VERSION ""

NS_ :

BS_:

BU_: IVI_IF IC HUD MFW ECALL ALC VAP EPA GW_IF

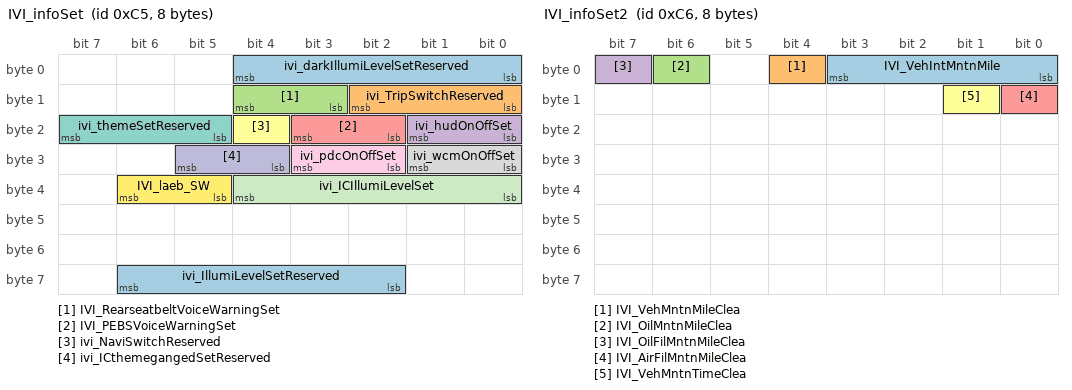
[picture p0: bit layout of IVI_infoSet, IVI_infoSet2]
BO_ 197 IVI_infoSet: 8 IVI_IF
 SG_ ivi_darkIllumiLevelSetReserved : 0|5@1+ (1,0) [0|31] "" Vector__XXX
 SG_ ivi_TripSwitchReserved : 8|3@1+ (1,0) [0|7] "" Vector__XXX
 SG_ IVI_RearseatbeltVoiceWarningSet : 11|2@1+ (1,0) [0|3] ""  GW_IF
 SG_ ivi_hudOnOffSet : 16|2@1+ (1,0) [0|3] ""  HUD,GW_IF
 SG_ IVI_PEBSVoiceWarningSet : 18|2@1+ (1,0) [0|3] ""  GW_IF
 SG_ ivi_NaviSwitchReserved : 20|1@1+ (1,0) [0|1] ""  GW_IF
 SG_ ivi_themeSetReserved : 21|3@1+ (1,0) [0|7] ""  GW_IF
 SG_ ivi_wcmOnOffSet : 24|2@1+ (1,0) [0|3] ""  GW_IF
 SG_ ivi_pdcOnOffSet : 26|2@1+ (1,0) [0|3] ""  GW_IF
 SG_ ivi_ICthemegangedSetReserved : 28|2@1+ (1,0) [0|3] "" Vector__XXX
 SG_ ivi_ICIllumiLevelSet : 32|5@1+ (1,0) [0|31] ""  IC
 SG_ IVI_laeb_SW : 37|2@1+ (1,0) [0|3] ""  GW_IF
 SG_ ivi_IllumiLevelSetReserved : 58|5@1+ (1,0) [0|31] "" Vector__XXX

BO_ 198 IVI_infoSet2: 8 IVI_IF
 SG_ IVI_VehIntMntnMile : 0|4@1+ (500,3000) [3000|10000] "Km" Vector__XXX
 SG_ IVI_VehMntnMileClea : 4|1@1+ (1,0) [0|1] "" Vector__XXX
 SG_ IVI_OilMntnMileClea : 6|1@1+ (1,0) [0|1] "" Vector__XXX
 SG_ IVI_OilFilMntnMileClea : 7|1@1+ (1,0) [0|1] "" Vector__XXX
 SG_ IVI_AirFilMntnMileClea : 8|1@1+ (1,0) [0|1] "" Vector__XXX
 SG_ IVI_VehMntnTimeClea : 9|1@1+ (1,0) [0|1] "" Vector__XXX

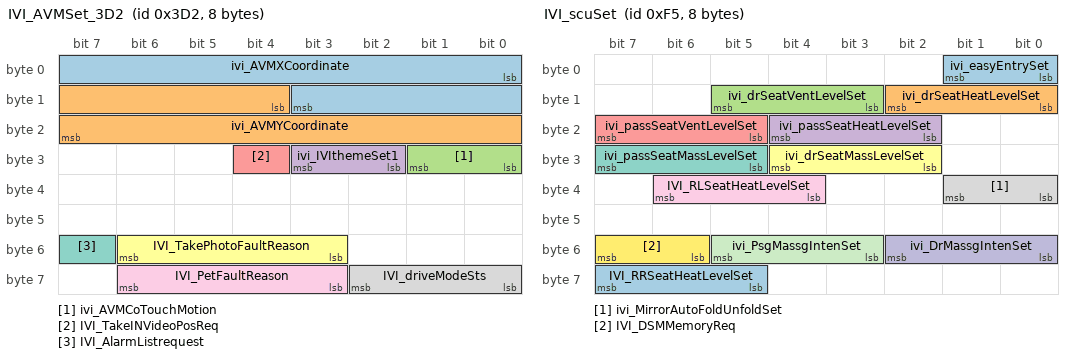
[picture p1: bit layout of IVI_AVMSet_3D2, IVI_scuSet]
BO_ 978 IVI_AVMSet_3D2: 8 IVI_IF
 SG_ ivi_AVMXCoordinate : 0|12@1+ (1,0) [0|1920] ""  GW_IF
 SG_ ivi_AVMYCoordinate : 12|12@1+ (1,0) [0|1080] ""  GW_IF
 SG_ ivi_AVMCoTouchMotion : 24|2@1+ (1,0) [0|3] ""  GW_IF
 SG_ ivi_IVIthemeSet1 : 26|2@1+ (1,0) [0|3] ""  GW_IF
 SG_ IVI_TakeINVideoPosReq : 28|1@1+ (1,0) [0|1] "" Vector__XXX
 SG_ IVI_TakePhotoFaultReason : 51|4@1+ (1,0) [0|15] "" Vector__XXX
 SG_ IVI_AlarmListrequest : 55|1@1+ (1,0) [0|1] "" Vector__XXX
 SG_ IVI_driveModeSts : 56|3@1+ (1,0) [0|7] "" Vector__XXX
 SG_ IVI_PetFaultReason : 59|4@1+ (1,0) [0|15] ""  GW_IF

BO_ 245 IVI_scuSet: 8 IVI_IF
 SG_ ivi_easyEntrySet : 0|2@1+ (1,0) [0|3] ""  GW_IF
 SG_ ivi_drSeatHeatLevelSet : 8|3@1+ (1,0) [0|7] ""  GW_IF
 SG_ ivi_drSeatVentLevelSet : 11|3@1+ (1,0) [0|7] ""  GW_IF
 SG_ ivi_passSeatHeatLevelSet : 18|3@1+ (1,0) [0|7] ""  GW_IF
 SG_ ivi_passSeatVentLevelSet : 21|3@1+ (1,0) [0|7] ""  GW_IF
 SG_ ivi_drSeatMassLevelSet : 26|3@1+ (1,0) [0|7] ""  GW_IF
 SG_ ivi_passSeatMassLevelSet : 29|3@1+ (1,0) [0|7] ""  GW_IF
 SG_ ivi_MirrorAutoFoldUnfoldSet : 32|2@1+ (1,0) [0|3] ""  GW_IF
 SG_ IVI_RLSeatHeatLevelSet : 36|3@1+ (1,0) [0|7] ""  GW_IF
 SG_ ivi_DrMassgIntenSet : 48|3@1+ (1,0) [0|7] ""  GW_IF
 SG_ ivi_PsgMassgIntenSet : 51|3@1+ (1,0) [0|7] ""  GW_IF
 SG_ IVI_DSMMemoryReq : 54|2@1+ (1,0) [0|3] ""  GW_IF
 SG_ IVI_RRSeatHeatLevelSet : 61|3@1+ (1,0) [0|7] ""  GW_IF

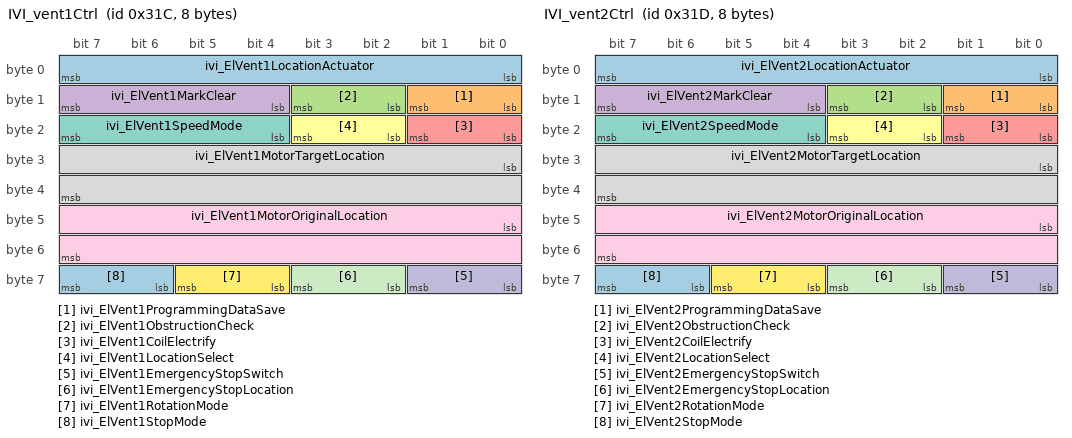
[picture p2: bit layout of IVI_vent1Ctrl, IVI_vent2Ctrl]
BO_ 796 IVI_vent1Ctrl: 8 IVI_IF
 SG_ ivi_ElVent1LocationActuator : 0|8@1+ (1,0) [0|255] ""  GW_IF
 SG_ ivi_ElVent1ProgrammingDataSave : 8|2@1+ (1,0) [0|3] ""  GW_IF
 SG_ ivi_ElVent1ObstructionCheck : 10|2@1+ (1,0) [0|3] ""  GW_IF
 SG_ ivi_ElVent1MarkClear : 12|4@1+ (1,0) [0|15] ""  GW_IF
 SG_ ivi_ElVent1CoilElectrify : 16|2@1+ (1,0) [0|3] ""  GW_IF
 SG_ ivi_ElVent1LocationSelect : 18|2@1+ (1,0) [0|3] ""  GW_IF
 SG_ ivi_ElVent1SpeedMode : 20|4@1+ (1,0) [0|15] ""  GW_IF
 SG_ ivi_ElVent1MotorTargetLocation : 24|16@1+ (1,0) [0|65535] ""  GW_IF
 SG_ ivi_ElVent1MotorOriginalLocation : 40|16@1+ (1,0) [0|65535] ""  GW_IF
 SG_ ivi_ElVent1EmergencyStopSwitch : 56|2@1+ (1,0) [0|3] ""  GW_IF
 SG_ ivi_ElVent1EmergencyStopLocation : 58|2@1+ (1,0) [0|3] ""  GW_IF
 SG_ ivi_ElVent1RotationMode : 60|2@1+ (1,0) [0|3] ""  GW_IF
 SG_ ivi_ElVent1StopMode : 62|2@1+ (1,0) [0|3] ""  GW_IF

BO_ 797 IVI_vent2Ctrl: 8 IVI_IF
 SG_ ivi_ElVent2LocationActuator : 0|8@1+ (1,0) [0|255] ""  GW_IF
 SG_ ivi_ElVent2ProgrammingDataSave : 8|2@1+ (1,0) [0|3] ""  GW_IF
 SG_ ivi_ElVent2ObstructionCheck : 10|2@1+ (1,0) [0|3] ""  GW_IF
 SG_ ivi_ElVent2MarkClear : 12|4@1+ (1,0) [0|15] ""  GW_IF
 SG_ ivi_ElVent2CoilElectrify : 16|2@1+ (1,0) [0|3] ""  GW_IF
 SG_ ivi_ElVent2LocationSelect : 18|2@1+ (1,0) [0|3] ""  GW_IF
 SG_ ivi_ElVent2SpeedMode : 20|4@1+ (1,0) [0|15] ""  GW_IF
 SG_ ivi_ElVent2MotorTargetLocation : 24|16@1+ (1,0) [0|65535] ""  GW_IF
 SG_ ivi_ElVent2MotorOriginalLocation : 40|16@1+ (1,0) [0|65535] ""  GW_IF
 SG_ ivi_ElVent2EmergencyStopSwitch : 56|2@1+ (1,0) [0|3] ""  GW_IF
 SG_ ivi_ElVent2EmergencyStopLocation : 58|2@1+ (1,0) [0|3] ""  GW_IF
 SG_ ivi_ElVent2RotationMode : 60|2@1+ (1,0) [0|3] ""  GW_IF
 SG_ ivi_ElVent2StopMode : 62|2@1+ (1,0) [0|3] ""  GW_IF

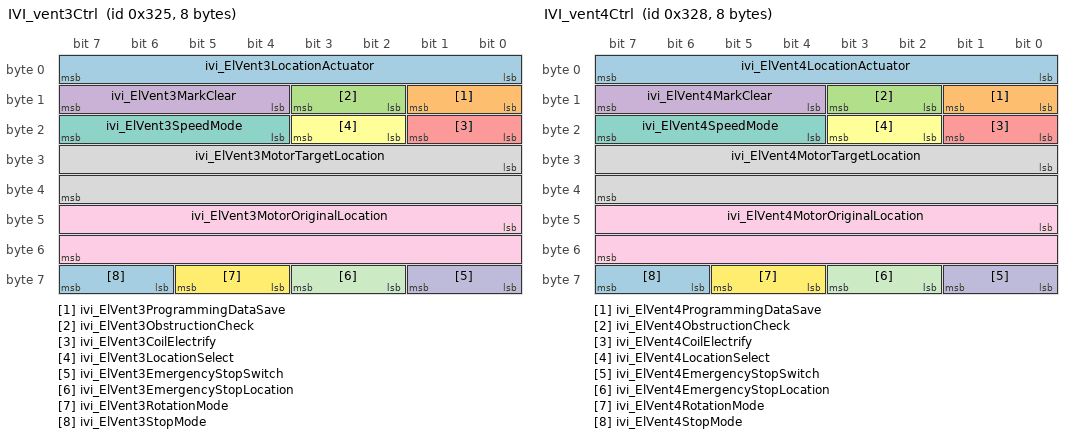
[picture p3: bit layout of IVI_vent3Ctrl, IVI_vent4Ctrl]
BO_ 805 IVI_vent3Ctrl: 8 IVI_IF
 SG_ ivi_ElVent3LocationActuator : 0|8@1+ (1,0) [0|255] ""  GW_IF
 SG_ ivi_ElVent3ProgrammingDataSave : 8|2@1+ (1,0) [0|3] ""  GW_IF
 SG_ ivi_ElVent3ObstructionCheck : 10|2@1+ (1,0) [0|3] ""  GW_IF
 SG_ ivi_ElVent3MarkClear : 12|4@1+ (1,0) [0|15] ""  GW_IF
 SG_ ivi_ElVent3CoilElectrify : 16|2@1+ (1,0) [0|3] ""  GW_IF
 SG_ ivi_ElVent3LocationSelect : 18|2@1+ (1,0) [0|3] ""  GW_IF
 SG_ ivi_ElVent3SpeedMode : 20|4@1+ (1,0) [0|15] ""  GW_IF
 SG_ ivi_ElVent3MotorTargetLocation : 24|16@1+ (1,0) [0|65535] ""  GW_IF
 SG_ ivi_ElVent3MotorOriginalLocation : 40|16@1+ (1,0) [0|65535] ""  GW_IF
 SG_ ivi_ElVent3EmergencyStopSwitch : 56|2@1+ (1,0) [0|3] ""  GW_IF
 SG_ ivi_ElVent3EmergencyStopLocation : 58|2@1+ (1,0) [0|3] ""  GW_IF
 SG_ ivi_ElVent3RotationMode : 60|2@1+ (1,0) [0|3] ""  GW_IF
 SG_ ivi_ElVent3StopMode : 62|2@1+ (1,0) [0|3] ""  GW_IF

BO_ 808 IVI_vent4Ctrl: 8 IVI_IF
 SG_ ivi_ElVent4LocationActuator : 0|8@1+ (1,0) [0|255] ""  GW_IF
 SG_ ivi_ElVent4ProgrammingDataSave : 8|2@1+ (1,0) [0|3] ""  GW_IF
 SG_ ivi_ElVent4ObstructionCheck : 10|2@1+ (1,0) [0|3] ""  GW_IF
 SG_ ivi_ElVent4MarkClear : 12|4@1+ (1,0) [0|15] ""  GW_IF
 SG_ ivi_ElVent4CoilElectrify : 16|2@1+ (1,0) [0|3] ""  GW_IF
 SG_ ivi_ElVent4LocationSelect : 18|2@1+ (1,0) [0|3] ""  GW_IF
 SG_ ivi_ElVent4SpeedMode : 20|4@1+ (1,0) [0|15] ""  GW_IF
 SG_ ivi_ElVent4MotorTargetLocation : 24|16@1+ (1,0) [0|65535] ""  GW_IF
 SG_ ivi_ElVent4MotorOriginalLocation : 40|16@1+ (1,0) [0|65535] ""  GW_IF
 SG_ ivi_ElVent4EmergencyStopSwitch : 56|2@1+ (1,0) [0|3] ""  GW_IF
 SG_ ivi_ElVent4EmergencyStopLocation : 58|2@1+ (1,0) [0|3] ""  GW_IF
 SG_ ivi_ElVent4RotationMode : 60|2@1+ (1,0) [0|3] ""  GW_IF
 SG_ ivi_ElVent4StopMode : 62|2@1+ (1,0) [0|3] ""  GW_IF

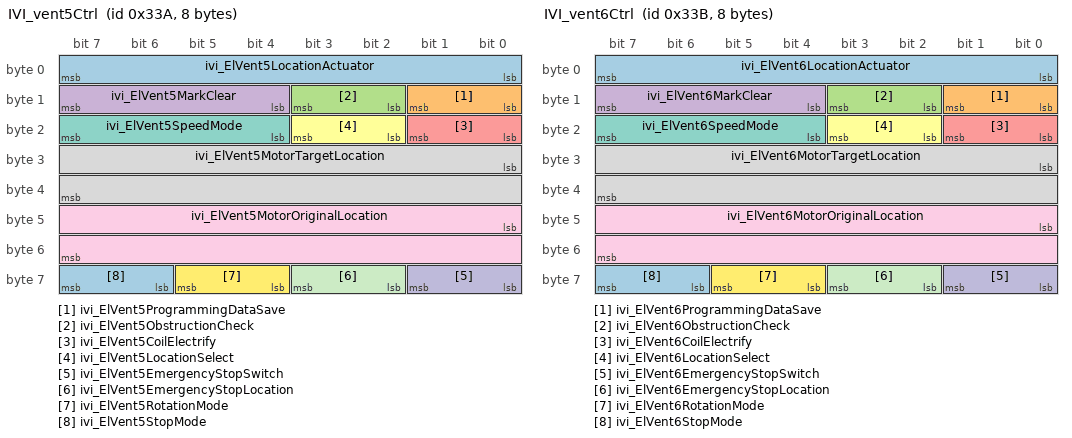
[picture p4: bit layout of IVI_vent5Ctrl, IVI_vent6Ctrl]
BO_ 826 IVI_vent5Ctrl: 8 IVI_IF
 SG_ ivi_ElVent5LocationActuator : 0|8@1+ (1,0) [0|255] ""  GW_IF
 SG_ ivi_ElVent5ProgrammingDataSave : 8|2@1+ (1,0) [0|3] ""  GW_IF
 SG_ ivi_ElVent5ObstructionCheck : 10|2@1+ (1,0) [0|3] ""  GW_IF
 SG_ ivi_ElVent5MarkClear : 12|4@1+ (1,0) [0|15] ""  GW_IF
 SG_ ivi_ElVent5CoilElectrify : 16|2@1+ (1,0) [0|3] ""  GW_IF
 SG_ ivi_ElVent5LocationSelect : 18|2@1+ (1,0) [0|3] ""  GW_IF
 SG_ ivi_ElVent5SpeedMode : 20|4@1+ (1,0) [0|15] ""  GW_IF
 SG_ ivi_ElVent5MotorTargetLocation : 24|16@1+ (1,0) [0|65535] ""  GW_IF
 SG_ ivi_ElVent5MotorOriginalLocation : 40|16@1+ (1,0) [0|65535] ""  GW_IF
 SG_ ivi_ElVent5EmergencyStopSwitch : 56|2@1+ (1,0) [0|3] ""  GW_IF
 SG_ ivi_ElVent5EmergencyStopLocation : 58|2@1+ (1,0) [0|3] ""  GW_IF
 SG_ ivi_ElVent5RotationMode : 60|2@1+ (1,0) [0|3] ""  GW_IF
 SG_ ivi_ElVent5StopMode : 62|2@1+ (1,0) [0|3] ""  GW_IF

BO_ 827 IVI_vent6Ctrl: 8 IVI_IF
 SG_ ivi_ElVent6LocationActuator : 0|8@1+ (1,0) [0|255] ""  GW_IF
 SG_ ivi_ElVent6ProgrammingDataSave : 8|2@1+ (1,0) [0|3] ""  GW_IF
 SG_ ivi_ElVent6ObstructionCheck : 10|2@1+ (1,0) [0|3] ""  GW_IF
 SG_ ivi_ElVent6MarkClear : 12|4@1+ (1,0) [0|15] ""  GW_IF
 SG_ ivi_ElVent6CoilElectrify : 16|2@1+ (1,0) [0|3] ""  GW_IF
 SG_ ivi_ElVent6LocationSelect : 18|2@1+ (1,0) [0|3] ""  GW_IF
 SG_ ivi_ElVent6SpeedMode : 20|4@1+ (1,0) [0|15] ""  GW_IF
 SG_ ivi_ElVent6MotorTargetLocation : 24|16@1+ (1,0) [0|65535] ""  GW_IF
 SG_ ivi_ElVent6MotorOriginalLocation : 40|16@1+ (1,0) [0|65535] ""  GW_IF
 SG_ ivi_ElVent6EmergencyStopSwitch : 56|2@1+ (1,0) [0|3] ""  GW_IF
 SG_ ivi_ElVent6EmergencyStopLocation : 58|2@1+ (1,0) [0|3] ""  GW_IF
 SG_ ivi_ElVent6RotationMode : 60|2@1+ (1,0) [0|3] ""  GW_IF
 SG_ ivi_ElVent6StopMode : 62|2@1+ (1,0) [0|3] ""  GW_IF

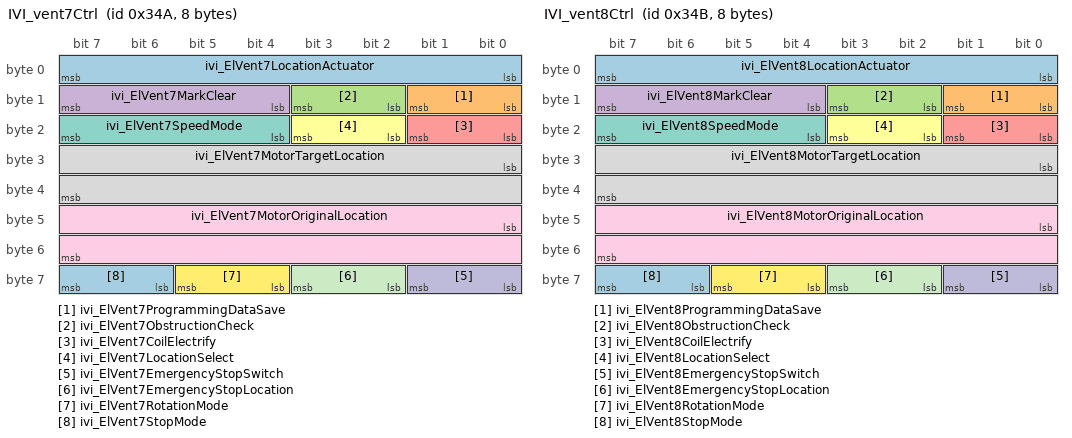
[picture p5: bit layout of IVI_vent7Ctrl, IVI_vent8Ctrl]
BO_ 842 IVI_vent7Ctrl: 8 IVI_IF
 SG_ ivi_ElVent7LocationActuator : 0|8@1+ (1,0) [0|255] ""  GW_IF
 SG_ ivi_ElVent7ProgrammingDataSave : 8|2@1+ (1,0) [0|3] ""  GW_IF
 SG_ ivi_ElVent7ObstructionCheck : 10|2@1+ (1,0) [0|3] ""  GW_IF
 SG_ ivi_ElVent7MarkClear : 12|4@1+ (1,0) [0|15] ""  GW_IF
 SG_ ivi_ElVent7CoilElectrify : 16|2@1+ (1,0) [0|3] ""  GW_IF
 SG_ ivi_ElVent7LocationSelect : 18|2@1+ (1,0) [0|3] ""  GW_IF
 SG_ ivi_ElVent7SpeedMode : 20|4@1+ (1,0) [0|15] ""  GW_IF
 SG_ ivi_ElVent7MotorTargetLocation : 24|16@1+ (1,0) [0|65535] ""  GW_IF
 SG_ ivi_ElVent7MotorOriginalLocation : 40|16@1+ (1,0) [0|65535] ""  GW_IF
 SG_ ivi_ElVent7EmergencyStopSwitch : 56|2@1+ (1,0) [0|3] ""  GW_IF
 SG_ ivi_ElVent7EmergencyStopLocation : 58|2@1+ (1,0) [0|3] ""  GW_IF
 SG_ ivi_ElVent7RotationMode : 60|2@1+ (1,0) [0|3] ""  GW_IF
 SG_ ivi_ElVent7StopMode : 62|2@1+ (1,0) [0|3] ""  GW_IF

BO_ 843 IVI_vent8Ctrl: 8 IVI_IF
 SG_ ivi_ElVent8LocationActuator : 0|8@1+ (1,0) [0|255] ""  GW_IF
 SG_ ivi_ElVent8ProgrammingDataSave : 8|2@1+ (1,0) [0|3] ""  GW_IF
 SG_ ivi_ElVent8ObstructionCheck : 10|2@1+ (1,0) [0|3] ""  GW_IF
 SG_ ivi_ElVent8MarkClear : 12|4@1+ (1,0) [0|15] ""  GW_IF
 SG_ ivi_ElVent8CoilElectrify : 16|2@1+ (1,0) [0|3] ""  GW_IF
 SG_ ivi_ElVent8LocationSelect : 18|2@1+ (1,0) [0|3] ""  GW_IF
 SG_ ivi_ElVent8SpeedMode : 20|4@1+ (1,0) [0|15] ""  GW_IF
 SG_ ivi_ElVent8MotorTargetLocation : 24|16@1+ (1,0) [0|65535] ""  GW_IF
 SG_ ivi_ElVent8MotorOriginalLocation : 40|16@1+ (1,0) [0|65535] ""  GW_IF
 SG_ ivi_ElVent8EmergencyStopSwitch : 56|2@1+ (1,0) [0|3] ""  GW_IF
 SG_ ivi_ElVent8EmergencyStopLocation : 58|2@1+ (1,0) [0|3] ""  GW_IF
 SG_ ivi_ElVent8RotationMode : 60|2@1+ (1,0) [0|3] ""  GW_IF
 SG_ ivi_ElVent8StopMode : 62|2@1+ (1,0) [0|3] ""  GW_IF

BO_ 966 GW_vent1Sts: 8 GW_IF
 SG_ gw_ElVent1ErrorStatus : 0|1@1+ (1,0) [0|1] ""  IVI_IF
 SG_ gw_ElVent1OverHeatStatus : 2|2@1+ (1,0) [0|3] ""  IVI_IF
 SG_ gw_ElVent1ElectricalFailureSts : 4|2@1+ (1,0) [0|3] ""  IVI_IF
 SG_ gw_ElVent1VoltageStatus : 6|2@1+ (1,0) [0|3] ""  IVI_IF
 SG_ gw_ElVent1EmergencyRunningSts : 8|2@1+ (1,0) [0|3] ""  IVI_IF
 SG_ gw_ElVent1ObstructionDetect : 10|2@1+ (1,0) [0|3] ""  IVI_IF
 SG_ gw_ElVent1ObstructionStatus : 12|2@1+ (1,0) [0|3] ""  IVI_IF
 SG_ gw_ElVent1ResetStatus : 14|2@1+ (1,0) [0|3] ""  IVI_IF
 SG_ gw_ElVent1CoilStatus : 16|2@1+ (1,0) [0|3] ""  IVI_IF
 SG_ gw_ElVent1LocationStatus : 18|2@1+ (1,0) [0|3] ""  IVI_IF
 SG_ gw_ElVent1SpeedStatus : 20|4@1+ (1,0) [0|15] ""  IVI_IF
 SG_ gw_ElVent1MotorCurrentLocation : 24|16@1+ (1,0) [0|65535] ""  IVI_IF
 SG_ gw_ElVent1MotorDrivingDirection : 40|2@1+ (1,0) [0|3] ""  IVI_IF
 SG_ gw_ElVent1TorqueKeepingSts : 42|2@1+ (1,0) [0|3] ""  IVI_IF
 SG_ gw_ElVent1SpecialFunction : 44|2@1+ (1,0) [0|3] ""  IVI_IF
 SG_ gw_ElVent1LocationActuator : 48|8@1+ (1,0) [0|255] ""  IVI_IF
 SG_ gw_ElVent1EmgyStopSwitchSts : 56|2@1+ (1,0) [0|3] ""  IVI_IF
 SG_ gw_ElVent1EmgyStopSLocation : 58|2@1+ (1,0) [0|3] ""  IVI_IF
 SG_ gw_ElVent1RotationMode : 60|2@1+ (1,0) [0|3] ""  IVI_IF
 SG_ gw_ElVent1StopStatus : 62|2@1+ (1,0) [0|3] ""  IVI_IF

BO_ 967 GW_vent2Sts: 8 GW_IF
 SG_ gw_ElVent2ErrorStatus : 0|1@1+ (1,0) [0|1] ""  IVI_IF
 SG_ gw_ElVent2OverHeatStatus : 2|2@1+ (1,0) [0|3] ""  IVI_IF
 SG_ gw_ElVent2ElectricalFailureSts : 4|2@1+ (1,0) [0|3] ""  IVI_IF
 SG_ gw_ElVent2VoltageStatus : 6|2@1+ (1,0) [0|3] ""  IVI_IF
 SG_ gw_ElVent2EmergencyRunningSts : 8|2@1+ (1,0) [0|3] ""  IVI_IF
 SG_ gw_ElVent2ObstructionDetect : 10|2@1+ (1,0) [0|3] ""  IVI_IF
 SG_ gw_ElVent2ObstructionStatus : 12|2@1+ (1,0) [0|3] ""  IVI_IF
 SG_ gw_ElVent2ResetStatus : 14|2@1+ (1,0) [0|3] ""  IVI_IF
 SG_ gw_ElVent2CoilStatus : 16|2@1+ (1,0) [0|3] ""  IVI_IF
 SG_ gw_ElVent2LocationStatus : 18|2@1+ (1,0) [0|3] ""  IVI_IF
 SG_ gw_ElVent2SpeedStatus : 20|4@1+ (1,0) [0|15] ""  IVI_IF
 SG_ gw_ElVent2MotorCurrentLocation : 24|16@1+ (1,0) [0|65535] ""  IVI_IF
 SG_ gw_ElVent2MotorDrivingDirection : 40|2@1+ (1,0) [0|3] ""  IVI_IF
 SG_ gw_ElVent2TorqueKeepingSts : 42|2@1+ (1,0) [0|3] ""  IVI_IF
 SG_ gw_ElVent2SpecialFunction : 44|2@1+ (1,0) [0|3] ""  IVI_IF
 SG_ gw_ElVent2LocationActuator : 48|8@1+ (1,0) [0|255] ""  IVI_IF
 SG_ gw_ElVent2EmgyStopSwitchSts : 56|2@1+ (1,0) [0|3] ""  IVI_IF
 SG_ gw_ElVent2EmgyStopSLocation : 58|2@1+ (1,0) [0|3] ""  IVI_IF
 SG_ gw_ElVent2RotationMode : 60|2@1+ (1,0) [0|3] ""  IVI_IF
 SG_ gw_ElVent2StopStatus : 62|2@1+ (1,0) [0|3] ""  IVI_IF

BO_ 968 GW_vent3Sts: 8 GW_IF
 SG_ gw_ElVent3ErrorStatus : 0|1@1+ (1,0) [0|1] ""  IVI_IF
 SG_ gw_ElVent3OverHeatStatus : 2|2@1+ (1,0) [0|3] ""  IVI_IF
 SG_ gw_ElVent3ElectricalFailureSts : 4|2@1+ (1,0) [0|3] ""  IVI_IF
 SG_ gw_ElVent3VoltageStatus : 6|2@1+ (1,0) [0|3] ""  IVI_IF
 SG_ gw_ElVent3EmergencyRunningSts : 8|2@1+ (1,0) [0|3] ""  IVI_IF
 SG_ gw_ElVent3ObstructionDetect : 10|2@1+ (1,0) [0|3] ""  IVI_IF
 SG_ gw_ElVent3ObstructionStatus : 12|2@1+ (1,0) [0|3] ""  IVI_IF
 SG_ gw_ElVent3ResetStatus : 14|2@1+ (1,0) [0|3] ""  IVI_IF
 SG_ gw_ElVent3CoilStatus : 16|2@1+ (1,0) [0|3] ""  IVI_IF
 SG_ gw_ElVent3LocationStatus : 18|2@1+ (1,0) [0|3] ""  IVI_IF
 SG_ gw_ElVent3SpeedStatus : 20|4@1+ (1,0) [0|15] ""  IVI_IF
 SG_ gw_ElVent3MotorCurrentLocation : 24|16@1+ (1,0) [0|65535] ""  IVI_IF
 SG_ gw_ElVent3MotorDrivingDirection : 40|2@1+ (1,0) [0|3] ""  IVI_IF
 SG_ gw_ElVent3TorqueKeepingSts : 42|2@1+ (1,0) [0|3] ""  IVI_IF
 SG_ gw_ElVent3SpecialFunction : 44|2@1+ (1,0) [0|3] ""  IVI_IF
 SG_ gw_ElVent3LocationActuator : 48|8@1+ (1,0) [0|255] ""  IVI_IF
 SG_ gw_ElVent3EmgyStopSwitchSts : 56|2@1+ (1,0) [0|3] ""  IVI_IF
 SG_ gw_ElVent3EmgyStopSLocation : 58|2@1+ (1,0) [0|3] ""  IVI_IF
 SG_ gw_ElVent3RotationMode : 60|2@1+ (1,0) [0|3] ""  IVI_IF
 SG_ gw_ElVent3StopStatus : 62|2@1+ (1,0) [0|3] ""  IVI_IF

BO_ 969 GW_vent4Sts: 8 GW_IF
 SG_ gw_ElVent4ErrorStatus : 0|1@1+ (1,0) [0|1] ""  IVI_IF
 SG_ gw_ElVent4OverHeatStatus : 2|2@1+ (1,0) [0|3] ""  IVI_IF
 SG_ gw_ElVent4ElectricalFailureSts : 4|2@1+ (1,0) [0|3] ""  IVI_IF
 SG_ gw_ElVent4VoltageStatus : 6|2@1+ (1,0) [0|3] ""  IVI_IF
 SG_ gw_ElVent4EmergencyRunningSts : 8|2@1+ (1,0) [0|3] ""  IVI_IF
 SG_ gw_ElVent4ObstructionDetect : 10|2@1+ (1,0) [0|3] ""  IVI_IF
 SG_ gw_ElVent4ObstructionStatus : 12|2@1+ (1,0) [0|3] ""  IVI_IF
 SG_ gw_ElVent4ResetStatus : 14|2@1+ (1,0) [0|3] ""  IVI_IF
 SG_ gw_ElVent4CoilStatus : 16|2@1+ (1,0) [0|3] ""  IVI_IF
 SG_ gw_ElVent4LocationStatus : 18|2@1+ (1,0) [0|3] ""  IVI_IF
 SG_ gw_ElVent4SpeedStatus : 20|4@1+ (1,0) [0|15] ""  IVI_IF
 SG_ gw_ElVent4MotorCurrentLocation : 24|16@1+ (1,0) [0|65535] ""  IVI_IF
 SG_ gw_ElVent4MotorDrivingDirection : 40|2@1+ (1,0) [0|3] ""  IVI_IF
 SG_ gw_ElVent4TorqueKeepingSts : 42|2@1+ (1,0) [0|3] ""  IVI_IF
 SG_ gw_ElVent4SpecialFunction : 44|2@1+ (1,0) [0|3] ""  IVI_IF
 SG_ gw_ElVent4LocationActuator : 48|8@1+ (1,0) [0|255] ""  IVI_IF
 SG_ gw_ElVent4EmgyStopSwitchSts : 56|2@1+ (1,0) [0|3] ""  IVI_IF
 SG_ gw_ElVent4EmgyStopSLocation : 58|2@1+ (1,0) [0|3] ""  IVI_IF
 SG_ gw_ElVent4RotationMode : 60|2@1+ (1,0) [0|3] ""  IVI_IF
 SG_ gw_ElVent4StopStatus : 62|2@1+ (1,0) [0|3] ""  IVI_IF

BO_ 970 GW_vent5Sts: 8 GW_IF
 SG_ gw_ElVent5ErrorStatus : 0|1@1+ (1,0) [0|1] ""  IVI_IF
 SG_ gw_ElVent5OverHeatStatus : 2|2@1+ (1,0) [0|3] ""  IVI_IF
 SG_ gw_ElVent5ElectricalFailureSts : 4|2@1+ (1,0) [0|3] ""  IVI_IF
 SG_ gw_ElVent5VoltageStatus : 6|2@1+ (1,0) [0|3] ""  IVI_IF
 SG_ gw_ElVent5EmergencyRunningSts : 8|2@1+ (1,0) [0|3] ""  IVI_IF
 SG_ gw_ElVent5ObstructionDetect : 10|2@1+ (1,0) [0|3] ""  IVI_IF
 SG_ gw_ElVent5ObstructionStatus : 12|2@1+ (1,0) [0|3] ""  IVI_IF
 SG_ gw_ElVent5ResetStatus : 14|2@1+ (1,0) [0|3] ""  IVI_IF
 SG_ gw_ElVent5CoilStatus : 16|2@1+ (1,0) [0|3] ""  IVI_IF
 SG_ gw_ElVent5LocationStatus : 18|2@1+ (1,0) [0|3] ""  IVI_IF
 SG_ gw_ElVent5SpeedStatus : 20|4@1+ (1,0) [0|15] ""  IVI_IF
 SG_ gw_ElVent5MotorCurrentLocation : 24|16@1+ (1,0) [0|65535] ""  IVI_IF
 SG_ gw_ElVent5MotorDrivingDirection : 40|2@1+ (1,0) [0|3] ""  IVI_IF
 SG_ gw_ElVent5TorqueKeepingSts : 42|2@1+ (1,0) [0|3] ""  IVI_IF
 SG_ gw_ElVent5SpecialFunction : 44|2@1+ (1,0) [0|3] ""  IVI_IF
 SG_ gw_ElVent5LocationActuator : 48|8@1+ (1,0) [0|255] ""  IVI_IF
 SG_ gw_ElVent5EmgyStopSwitchSts : 56|2@1+ (1,0) [0|3] ""  IVI_IF
 SG_ gw_ElVent5EmgyStopSLocation : 58|2@1+ (1,0) [0|3] ""  IVI_IF
 SG_ gw_ElVent5RotationMode : 60|2@1+ (1,0) [0|3] ""  IVI_IF
 SG_ gw_ElVent5StopStatus : 62|2@1+ (1,0) [0|3] ""  IVI_IF

BO_ 971 GW_vent6Sts: 8 GW_IF
 SG_ gw_ElVent6ErrorStatus : 0|1@1+ (1,0) [0|1] ""  IVI_IF
 SG_ gw_ElVent6OverHeatStatus : 2|2@1+ (1,0) [0|3] ""  IVI_IF
 SG_ gw_ElVent6ElectricalFailureSts : 4|2@1+ (1,0) [0|3] ""  IVI_IF
 SG_ gw_ElVent6VoltageStatus : 6|2@1+ (1,0) [0|3] ""  IVI_IF
 SG_ gw_ElVent6EmergencyRunningSts : 8|2@1+ (1,0) [0|3] ""  IVI_IF
 SG_ gw_ElVent6ObstructionDetect : 10|2@1+ (1,0) [0|3] ""  IVI_IF
 SG_ gw_ElVent6ObstructionStatus : 12|2@1+ (1,0) [0|3] ""  IVI_IF
 SG_ gw_ElVent6ResetStatus : 14|2@1+ (1,0) [0|3] ""  IVI_IF
 SG_ gw_ElVent6CoilStatus : 16|2@1+ (1,0) [0|3] ""  IVI_IF
 SG_ gw_ElVent6LocationStatus : 18|2@1+ (1,0) [0|3] ""  IVI_IF
 SG_ gw_ElVent6SpeedStatus : 20|4@1+ (1,0) [0|15] ""  IVI_IF
 SG_ gw_ElVent6MotorCurrentLocation : 24|16@1+ (1,0) [0|65535] ""  IVI_IF
 SG_ gw_ElVent6MotorDrivingDirection : 40|2@1+ (1,0) [0|3] ""  IVI_IF
 SG_ gw_ElVent6TorqueKeepingSts : 42|2@1+ (1,0) [0|3] ""  IVI_IF
 SG_ gw_ElVent6SpecialFunction : 44|2@1+ (1,0) [0|3] ""  IVI_IF
 SG_ gw_ElVent6LocationActuator : 48|8@1+ (1,0) [0|255] ""  IVI_IF
 SG_ gw_ElVent6EmgyStopSwitchSts : 56|2@1+ (1,0) [0|3] ""  IVI_IF
 SG_ gw_ElVent6EmgyStopSLocation : 58|2@1+ (1,0) [0|3] ""  IVI_IF
 SG_ gw_ElVent6RotationMode : 60|2@1+ (1,0) [0|3] ""  IVI_IF
 SG_ gw_ElVent6StopStatus : 62|2@1+ (1,0) [0|3] ""  IVI_IF

BO_ 972 GW_vent7Sts: 8 GW_IF
 SG_ gw_ElVent7ErrorStatus : 0|1@1+ (1,0) [0|1] ""  IVI_IF
 SG_ gw_ElVent7OverHeatStatus : 2|2@1+ (1,0) [0|3] ""  IVI_IF
 SG_ gw_ElVent7ElectricalFailureSts : 4|2@1+ (1,0) [0|3] ""  IVI_IF
 SG_ gw_ElVent7VoltageStatus : 6|2@1+ (1,0) [0|3] ""  IVI_IF
 SG_ gw_ElVent7EmergencyRunningSts : 8|2@1+ (1,0) [0|3] ""  IVI_IF
 SG_ gw_ElVent7ObstructionDetect : 10|2@1+ (1,0) [0|3] ""  IVI_IF
 SG_ gw_ElVent7ObstructionStatus : 12|2@1+ (1,0) [0|3] ""  IVI_IF
 SG_ gw_ElVent7ResetStatus : 14|2@1+ (1,0) [0|3] ""  IVI_IF
 SG_ gw_ElVent7CoilStatus : 16|2@1+ (1,0) [0|3] ""  IVI_IF
 SG_ gw_ElVent7LocationStatus : 18|2@1+ (1,0) [0|3] ""  IVI_IF
 SG_ gw_ElVent7SpeedStatus : 20|4@1+ (1,0) [0|15] ""  IVI_IF
 SG_ gw_ElVent7MotorCurrentLocation : 24|16@1+ (1,0) [0|65535] ""  IVI_IF
 SG_ gw_ElVent7MotorDrivingDirection : 40|2@1+ (1,0) [0|3] ""  IVI_IF
 SG_ gw_ElVent7TorqueKeepingSts : 42|2@1+ (1,0) [0|3] ""  IVI_IF
 SG_ gw_ElVent7SpecialFunction : 44|2@1+ (1,0) [0|3] ""  IVI_IF
 SG_ gw_ElVent7LocationActuator : 48|8@1+ (1,0) [0|255] ""  IVI_IF
 SG_ gw_ElVent7EmgyStopSwitchSts : 56|2@1+ (1,0) [0|3] ""  IVI_IF
 SG_ gw_ElVent7EmgyStopSLocation : 58|2@1+ (1,0) [0|3] ""  IVI_IF
 SG_ gw_ElVent7RotationMode : 60|2@1+ (1,0) [0|3] ""  IVI_IF
 SG_ gw_ElVent7StopStatus : 62|2@1+ (1,0) [0|3] ""  IVI_IF

BO_ 973 GW_vent8Sts: 8 GW_IF
 SG_ gw_ElVent8ErrorStatus : 0|1@1+ (1,0) [0|1] ""  IVI_IF
 SG_ gw_ElVent8OverHeatStatus : 2|2@1+ (1,0) [0|3] ""  IVI_IF
 SG_ gw_ElVent8ElectricalFailureSts : 4|2@1+ (1,0) [0|3] ""  IVI_IF
 SG_ gw_ElVent8VoltageStatus : 6|2@1+ (1,0) [0|3] ""  IVI_IF
 SG_ gw_ElVent8EmergencyRunningSts : 8|2@1+ (1,0) [0|3] ""  IVI_IF
 SG_ gw_ElVent8ObstructionDetect : 10|2@1+ (1,0) [0|3] ""  IVI_IF
 SG_ gw_ElVent8ObstructionStatus : 12|2@1+ (1,0) [0|3] ""  IVI_IF
 SG_ gw_ElVent8ResetStatus : 14|2@1+ (1,0) [0|3] ""  IVI_IF
 SG_ gw_ElVent8CoilStatus : 16|2@1+ (1,0) [0|3] ""  IVI_IF
 SG_ gw_ElVent8LocationStatus : 18|2@1+ (1,0) [0|3] ""  IVI_IF
 SG_ gw_ElVent8SpeedStatus : 20|4@1+ (1,0) [0|15] ""  IVI_IF
 SG_ gw_ElVent8MotorCurrentLocation : 24|16@1+ (1,0) [0|65535] ""  IVI_IF
 SG_ gw_ElVent8MotorDrivingDirection : 40|2@1+ (1,0) [0|3] ""  IVI_IF
 SG_ gw_ElVent8TorqueKeepingSts : 42|2@1+ (1,0) [0|3] ""  IVI_IF
 SG_ gw_ElVent8SpecialFunction : 44|2@1+ (1,0) [0|3] ""  IVI_IF
 SG_ gw_ElVent8LocationActuator : 48|8@1+ (1,0) [0|255] ""  IVI_IF
 SG_ gw_ElVent8EmgyStopSwitchSts : 56|2@1+ (1,0) [0|3] ""  IVI_IF
 SG_ gw_ElVent8EmgyStopSLocation : 58|2@1+ (1,0) [0|3] ""  IVI_IF
 SG_ gw_ElVent8RotationMode : 60|2@1+ (1,0) [0|3] ""  IVI_IF
 SG_ gw_ElVent8StopStatus : 62|2@1+ (1,0) [0|3] ""  IVI_IF

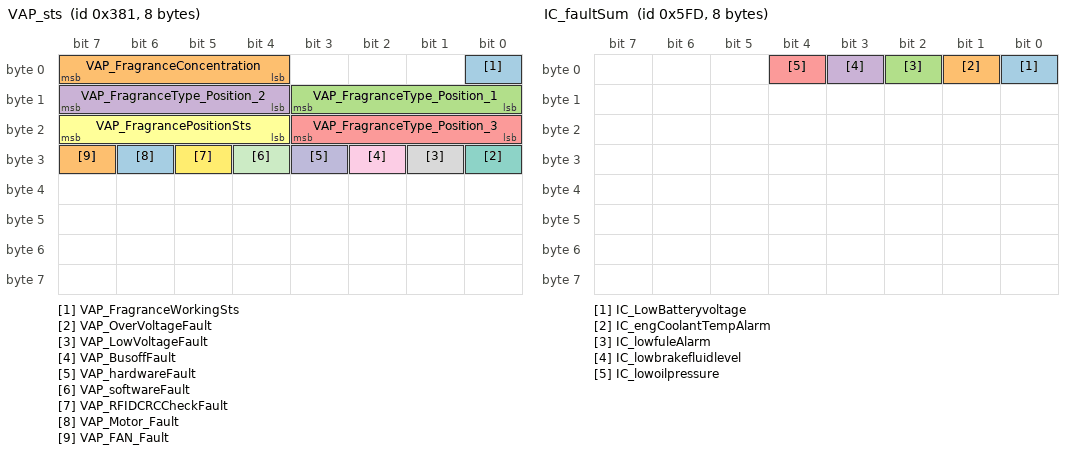
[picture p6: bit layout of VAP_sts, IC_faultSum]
BO_ 897 VAP_sts: 8 VAP
 SG_ VAP_FragranceWorkingSts : 0|1@1+ (1,0) [0|1] ""  IVI_IF
 SG_ VAP_FragranceConcentration : 4|4@1+ (1,0) [0|10] ""  IVI_IF
 SG_ VAP_FragranceType_Position_1 : 8|4@1+ (1,0) [0|15] ""  IVI_IF
 SG_ VAP_FragranceType_Position_2 : 12|4@1+ (1,0) [0|15] ""  IVI_IF
 SG_ VAP_FragranceType_Position_3 : 16|4@1+ (1,0) [0|15] ""  IVI_IF
 SG_ VAP_FragrancePositionSts : 20|4@1+ (1,0) [0|15] ""  IVI_IF
 SG_ VAP_OverVoltageFault : 24|1@1+ (1,0) [0|1] ""  IVI_IF
 SG_ VAP_LowVoltageFault : 25|1@1+ (1,0) [0|1] ""  IVI_IF
 SG_ VAP_BusoffFault : 26|1@1+ (1,0) [0|1] ""  IVI_IF
 SG_ VAP_hardwareFault : 27|1@1+ (1,0) [0|1] ""  IVI_IF
 SG_ VAP_softwareFault : 28|1@1+ (1,0) [0|1] ""  IVI_IF
 SG_ VAP_RFIDCRCCheckFault : 29|1@1+ (1,0) [0|1] ""  IVI_IF
 SG_ VAP_Motor_Fault : 30|1@1+ (1,0) [0|1] ""  IVI_IF
 SG_ VAP_FAN_Fault : 31|1@1+ (1,0) [0|1] ""  IVI_IF

BO_ 82 IC_engineOFF: 8 IVI_IF
 SG_ ic_engOffTime : 0|10@1+ (1,0) [0|1000] "min"  GW_IF
 SG_ ic_engOffTimeValid : 10|1@1+ (1,0) [0|1] ""  GW_IF
 SG_ IC_songFaultNum : 16|6@1+ (1,0) [0|63] "" Vector__XXX
 SG_ IC_songWarningSts : 22|2@1+ (1,0) [0|3] "" Vector__XXX

BO_ 1533 IC_faultSum: 8 IVI_IF
 SG_ IC_LowBatteryvoltage : 0|1@1+ (1,0) [0|1] "" Vector__XXX
 SG_ IC_engCoolantTempAlarm : 1|1@1+ (1,0) [0|1] "" Vector__XXX
 SG_ IC_lowfuleAlarm : 2|1@1+ (1,0) [0|1] "" Vector__XXX
 SG_ IC_lowbrakefluidlevel : 3|1@1+ (1,0) [0|1] "" Vector__XXX
 SG_ IC_lowoilpressure : 4|1@1+ (1,0) [0|1] "" Vector__XXX

BO_ 1010 IC_infoSet: 8 IVI_IF
 SG_ ic_hudScreenTransition : 0|2@1+ (1,0) [0|3] ""  HUD
 SG_ ic_hudHeightSet : 2|5@1+ (1,-14) [-14|14] ""  HUD
 SG_ ic_hudillumiLvSet : 8|4@1+ (1,-5) [-5|5] ""  HUD

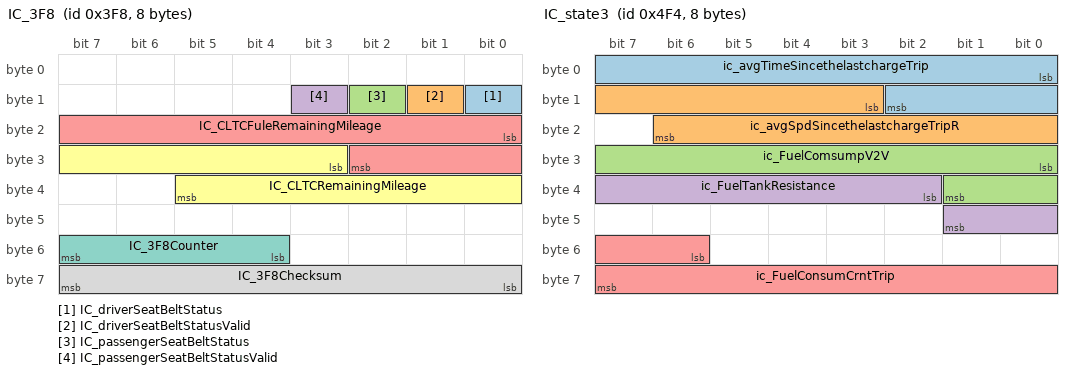
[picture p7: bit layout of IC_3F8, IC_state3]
BO_ 1016 IC_3F8: 8 IVI_IF
 SG_ IC_driverSeatBeltStatus : 8|1@1+ (1,0) [0|1] ""  GW_IF
 SG_ IC_driverSeatBeltStatusValid : 9|1@1+ (1,0) [0|1] ""  GW_IF
 SG_ IC_passengerSeatBeltStatus : 10|1@1+ (1,0) [0|1] ""  GW_IF
 SG_ IC_passengerSeatBeltStatusValid : 11|1@1+ (1,0) [0|1] ""  GW_IF
 SG_ IC_CLTCFuleRemainingMileage : 16|11@1+ (1,0) [0|2047] "km"  GW_IF
 SG_ IC_CLTCRemainingMileage : 27|11@1+ (1,0) [0|2047] "km"  GW_IF
 SG_ IC_3F8Counter : 52|4@1+ (1,0) [0|15] ""  GW_IF
 SG_ IC_3F8Checksum : 56|8@1+ (1,0) [0|255] ""  GW_IF

BO_ 1020 IC_3FC: 8 IVI_IF
 SG_ IC_NEDCRemainingMileage : 0|11@1+ (1,0) [0|2047] "km"  GW_IF
 SG_ IC_NEDCFuleRemainingMileage : 11|11@1+ (1,0) [0|2047] "km"  GW_IF

BO_ 1268 IC_state3: 8 IVI_IF
 SG_ ic_avgTimeSincethelastchargeTrip : 0|11@1+ (1,0) [0|1440] "min"  GW_IF
 SG_ ic_avgSpdSincethelastchargeTripR : 11|12@1+ (0.1,0) [0|280] "KPH"  GW_IF
 SG_ ic_FuelComsumpV2V : 24|10@1+ (0.1,0) [0|102.3] "L"  GW_IF
 SG_ ic_FuelTankResistance : 34|8@1+ (1,0) [0|255] "Ω"  GW_IF
 SG_ ic_FuelConsumCrntTrip : 54|10@1+ (0.1,0) [0|99.9] "L" Vector__XXX

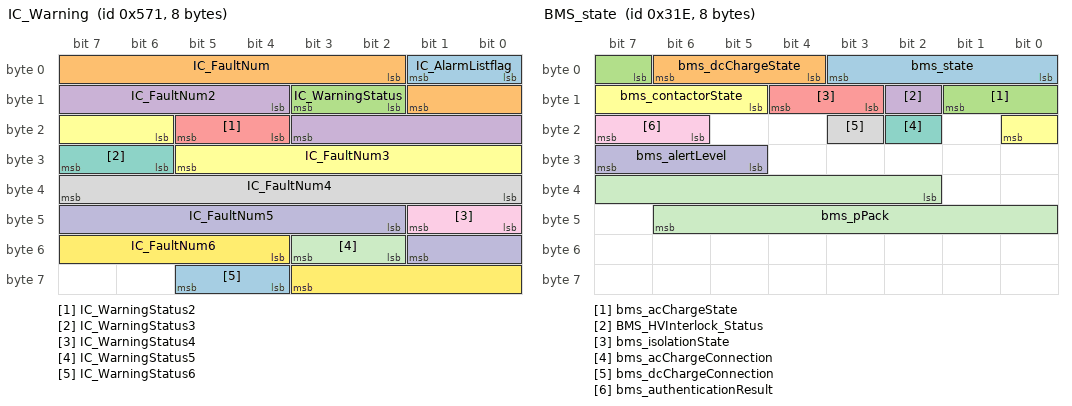
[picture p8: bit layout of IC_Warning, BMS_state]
BO_ 1393 IC_Warning: 8 IVI_IF
 SG_ IC_AlarmListflag : 0|2@1+ (1,0) [0|3] "" Vector__XXX
 SG_ IC_FaultNum : 2|8@1+ (1,0) [0|255] "" Vector__XXX
 SG_ IC_WarningStatus : 10|2@1+ (1,0) [0|3] "" Vector__XXX
 SG_ IC_FaultNum2 : 12|8@1+ (1,0) [0|255] "" Vector__XXX
 SG_ IC_WarningStatus2 : 20|2@1+ (1,0) [0|3] "" Vector__XXX
 SG_ IC_FaultNum3 : 22|8@1+ (1,0) [0|255] "" Vector__XXX
 SG_ IC_WarningStatus3 : 30|2@1+ (1,0) [0|3] "" Vector__XXX
 SG_ IC_FaultNum4 : 32|8@1+ (1,0) [0|255] "" Vector__XXX
 SG_ IC_WarningStatus4 : 40|2@1+ (1,0) [0|3] "" Vector__XXX
 SG_ IC_FaultNum5 : 42|8@1+ (1,0) [0|255] "" Vector__XXX
 SG_ IC_WarningStatus5 : 50|2@1+ (1,0) [0|3] "" Vector__XXX
 SG_ IC_FaultNum6 : 52|8@1+ (1,0) [0|255] "" Vector__XXX
 SG_ IC_WarningStatus6 : 60|2@1+ (1,0) [0|3] "" Vector__XXX

BO_ 1392 IC_Warningfb: 8 IVI_IF
 SG_ IC_DMS_DistractionIconFB : 0|3@1+ (1,0) [0|7] "" Vector__XXX
 SG_ IC_DMS_FatigueIconFB : 3|3@1+ (1,0) [0|7] "" Vector__XXX
 SG_ IC_DMS_Res1 : 16|8@1+ (1,0) [0|255] "" Vector__XXX
 SG_ IC_DMS_Res2 : 24|8@1+ (1,0) [0|255] "" Vector__XXX
 SG_ IC_DMS_Res3 : 32|8@1+ (1,0) [0|255] "" Vector__XXX

BO_ 990 GW_BMS_meas: 8 GW_IF
 SG_ bms_vPackBmu : 0|14@1+ (0.05,0) [0|800] "V"  IVI_IF
 SG_ bms_vPackBms : 14|14@1+ (0.05,0) [0|800] "V"  IVI_IF
 SG_ bms_iPack : 28|14@1+ (0.2,-600) [-600|2500] "A"  IVI_IF

BO_ 798 BMS_state: 8 GW_IF
 SG_ bms_state : 0|4@1+ (1,0) [0|15] ""  IVI_IF
 SG_ bms_dcChargeState : 4|3@1+ (1,0) [0|7] ""  IVI_IF
 SG_ bms_acChargeState : 7|3@1+ (1,0) [0|7] ""  IVI_IF
 SG_ BMS_HVInterlock_Status : 10|1@1+ (1,0) [0|1] ""  IVI_IF
 SG_ bms_isolationState : 11|2@1+ (1,0) [0|3] ""  IVI_IF
 SG_ bms_contactorState : 13|4@1+ (1,0) [0|15] ""  IVI_IF
 SG_ bms_acChargeConnection : 18|1@1+ (1,0) [0|1] ""  IVI_IF
 SG_ bms_dcChargeConnection : 19|1@1+ (1,0) [0|1] ""  IVI_IF
 SG_ bms_authenticationResult : 22|2@1+ (1,0) [0|3] ""  IVI_IF
 SG_ bms_alertLevel : 29|3@1+ (1,0) [0|7] ""  IVI_IF
 SG_ bms_pPack : 34|13@1+ (0.25,-200) [-200|1000] "KW"  IVI_IF

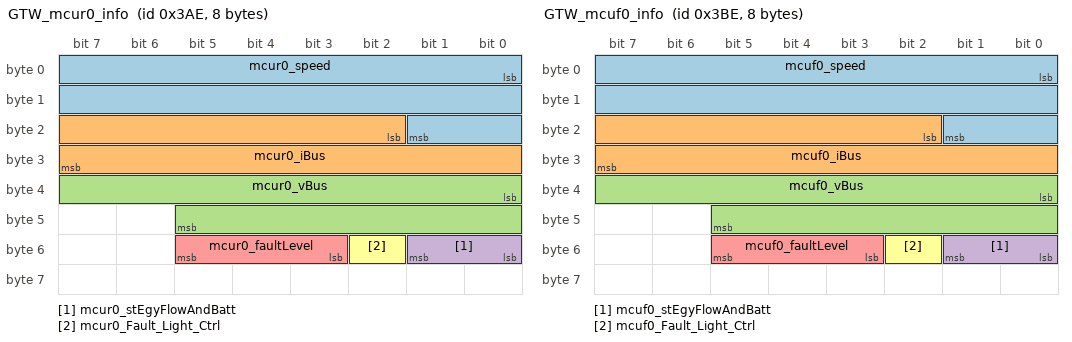
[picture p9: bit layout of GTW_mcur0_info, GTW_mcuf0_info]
BO_ 942 GTW_mcur0_info: 8 GW_IF
 SG_ mcur0_speed : 0|18@1- (0.2,0) [-26000|26000] "RPM"  IVI_IF
 SG_ mcur0_iBus : 18|14@1+ (0.2,-600) [-600|2500] "A"  IVI_IF
 SG_ mcur0_vBus : 32|14@1+ (0.05,0) [0|800] "V"  IVI_IF
 SG_ mcur0_stEgyFlowAndBatt : 48|2@1+ (1,0) [0|3] ""  IVI_IF
 SG_ mcur0_faultLevel : 51|3@1+ (1,0) [0|7] ""  IVI_IF
 SG_ mcur0_Fault_Light_Ctrl : 50|1@1+ (1,0) [0|1] ""  IVI_IF

BO_ 958 GTW_mcuf0_info: 8 GW_IF
 SG_ mcuf0_speed : 0|18@1- (0.2,0) [-26000|26000] "RPM"  IVI_IF
 SG_ mcuf0_iBus : 18|14@1+ (0.2,-600) [-600|2500] "A"  IVI_IF
 SG_ mcuf0_vBus : 32|14@1+ (0.05,0) [0|800] "V"  IVI_IF
 SG_ mcuf0_stEgyFlowAndBatt : 48|2@1+ (1,0) [0|3] ""  IVI_IF
 SG_ mcuf0_faultLevel : 51|3@1+ (1,0) [0|7] ""  IVI_IF
 SG_ mcuf0_Fault_Light_Ctrl : 50|1@1+ (1,0) [0|1] ""  IVI_IF

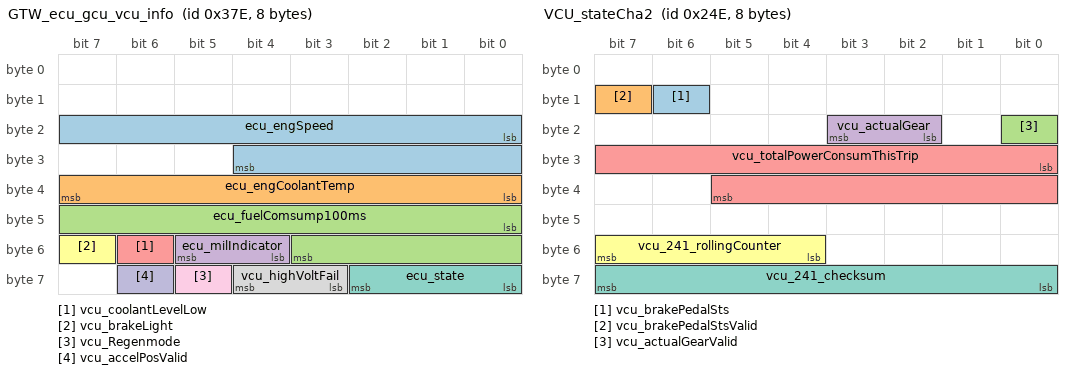
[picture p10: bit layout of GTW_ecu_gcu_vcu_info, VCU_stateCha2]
BO_ 894 GTW_ecu_gcu_vcu_info: 8 GW_IF
 SG_ ecu_engSpeed : 16|13@1+ (1,0) [0|8000] "RPM"  IVI_IF
 SG_ ecu_engCoolantTemp : 32|8@1+ (0.75,-48) [-48|142.5] "C"  IVI_IF
 SG_ ecu_fuelComsump100ms : 40|12@1+ (0.001,0) [0|4] "ml"  IVI_IF
 SG_ ecu_milIndicator : 52|2@1+ (1,0) [0|3] ""  IVI_IF
 SG_ vcu_coolantLevelLow : 54|1@1+ (1,0) [0|1] ""  IVI_IF
 SG_ vcu_brakeLight : 55|1@1+ (1,0) [0|1] ""  IVI_IF
 SG_ ecu_state : 56|3@1+ (1,0) [0|7] ""  IVI_IF
 SG_ vcu_highVoltFail : 59|2@1+ (1,0) [0|3] ""  IVI_IF
 SG_ vcu_Regenmode : 61|1@1+ (1,0) [0|1] ""  IVI_IF
 SG_ vcu_accelPosValid : 62|1@1+ (1,0) [0|1] ""  IVI_IF,EPA

BO_ 547 GTW_esc_eps_iB_info: 8 GW_IF
 SG_ esc_vehicleSpeed : 0|13@1+ (0.05625,0) [0|270] "km/h"  IVI_IF,MFW,ALC,EPA
 SG_ esc_vehicleSpeedValid : 13|1@1+ (1,0) [0|1] ""  IVI_IF,MFW,ALC,EPA
 SG_ esc_avhActive : 15|1@1+ (1,0) [0|1] ""  IVI_IF,HUD
 SG_ esc_avhStandby : 16|1@1+ (1,0) [0|1] ""  IVI_IF,HUD
 SG_ esc_avhAvailable : 17|1@1+ (1,0) [0|1] ""  IVI_IF
 SG_ esc_hdcStatus : 19|2@1+ (1,0) [0|3] ""  IVI_IF
 SG_ esc_vlcTorqReq : 24|13@1+ (0.25,-500) [-500|1547.5] "N.m"  IVI_IF
 SG_ esc_vlcTorqReqActive : 37|1@1+ (1,0) [0|1] ""  IVI_IF
 SG_ esc_vlcError : 38|1@1+ (1,0) [0|1] ""  IVI_IF
 SG_ esc_vlcAvalible : 39|1@1+ (1,0) [0|1] ""  IVI_IF
 SG_ esc_vlcInterTargetAx : 40|8@1+ (0.05,-7) [-7|5.75] ""  IVI_IF
 SG_ esc_vlcActive : 48|1@1+ (1,0) [0|1] ""  IVI_IF
 SG_ eps_modeStatus : 50|2@1+ (1,0) [0|3] ""  IVI_IF
 SG_ esc_escActive : 52|1@1+ (1,0) [0|1] ""  IVI_IF
 SG_ esc_hdcAvailable : 55|1@1+ (1,0) [0|1] ""  IVI_IF
 SG_ iB_hmiWarningOn : 58|2@1+ (1,0) [0|3] ""  IVI_IF
 SG_ iB_hmiWarningOn_Q : 60|2@1+ (1,0) [0|3] ""  IVI_IF
 SG_ esc_hhcAvailable : 63|1@1+ (1,0) [0|1] ""  IVI_IF

BO_ 851 GW_EPS_state: 8 GW_IF
 SG_ eps_torsionBarTorque : 8|11@1+ (0.01,-10.24) [-10.24|10.23] "Nm"  IVI_IF
 SG_ eps_torsionBarTorqueValid : 19|1@1+ (1,0) [0|1] ""  IVI_IF

BO_ 590 VCU_stateCha2: 8 GW_IF
 SG_ vcu_brakePedalSts : 14|1@1+ (1,0) [0|1] ""  IVI_IF
 SG_ vcu_brakePedalStsValid : 15|1@1+ (1,0) [0|1] ""  IVI_IF
 SG_ vcu_actualGearValid : 16|1@1+ (1,0) [0|1] ""  IVI_IF,IC,HUD,ALC,EPA
 SG_ vcu_actualGear : 18|2@1+ (1,0) [0|3] ""  IVI_IF,IC,HUD,ALC,EPA
 SG_ vcu_totalPowerConsumThisTrip : 24|14@1+ (0.1,0) [0|1000] "kw/h"  IVI_IF
 SG_ vcu_241_rollingCounter : 52|4@1+ (1,0) [0|15] ""  IVI_IF
 SG_ vcu_241_checksum : 56|8@1+ (1,0) [0|255] ""  IVI_IF

BO_ 974 AC_temp_pressure: 8 GW_IF
 SG_ ac_ambientTemp : 0|8@1+ (0.5,-40) [-40|85] "degreeC"  IVI_IF
 SG_ ac_cabinTemp : 8|8@1+ (0.5,-40) [-40|85] "degreeC"  IVI_IF
 SG_ ac_ambientTempValid : 56|1@1+ (1,0) [0|1] "bit"  IVI_IF

BO_ 951 PDC_state: 8 GW_IF
 SG_ pdc_buzzerAlarmPattern : 0|3@1+ (1,0) [0|7] ""  IVI_IF
 SG_ pdc_modeStatus : 3|3@1+ (1,0) [0|7] ""  IVI_IF
 SG_ pdc_distanceFL : 8|3@1+ (1,0) [0|7] ""  IVI_IF
 SG_ pdc_sensorFaultFL : 11|1@1+ (1,0) [0|1] ""  IVI_IF
 SG_ pdc_distanceFML : 12|3@1+ (1,0) [0|7] ""  IVI_IF
 SG_ pdc_sensorFaultFML : 15|1@1+ (1,0) [0|1] ""  IVI_IF
 SG_ pdc_distanceFMR : 16|3@1+ (1,0) [0|7] ""  IVI_IF
 SG_ pdc_sensorFaultFMR : 19|1@1+ (1,0) [0|1] ""  IVI_IF
 SG_ pdc_distanceFR : 20|3@1+ (1,0) [0|7] ""  IVI_IF
 SG_ pdc_sensorFaultFR : 23|1@1+ (1,0) [0|1] ""  IVI_IF
 SG_ pdc_distanceRL : 24|3@1+ (1,0) [0|7] ""  IVI_IF
 SG_ pdc_sensorFaultRL : 27|1@1+ (1,0) [0|1] ""  IVI_IF
 SG_ pdc_distanceRML : 28|3@1+ (1,0) [0|7] ""  IVI_IF
 SG_ pdc_sensorFaultRML : 31|1@1+ (1,0) [0|1] ""  IVI_IF
 SG_ pdc_distanceRMR : 32|3@1+ (1,0) [0|7] ""  IVI_IF
 SG_ pdc_sensorFaultRMR : 35|1@1+ (1,0) [0|1] ""  IVI_IF
 SG_ pdc_distanceRR : 36|3@1+ (1,0) [0|7] ""  IVI_IF
 SG_ pdc_sensorFaultRR : 39|1@1+ (1,0) [0|1] ""  IVI_IF
 SG_ pdc_FrontRadarActiveStatus : 46|2@1+ (1,0) [0|3] ""  IVI_IF
 SG_ pdc_distanceFSL : 48|3@1+ (1,0) [0|7] ""  IVI_IF
 SG_ pdc_sensorFaultFSL : 51|1@1+ (1,0) [0|1] ""  IVI_IF
 SG_ pdc_distanceFSR : 52|3@1+ (1,0) [0|7] ""  IVI_IF
 SG_ pdc_sensorFaultFSR : 55|1@1+ (1,0) [0|1] ""  IVI_IF
 SG_ pdc_distanceRSL : 56|3@1+ (1,0) [0|7] ""  IVI_IF
 SG_ pdc_sensorFaultRSL : 59|1@1+ (1,0) [0|1] ""  IVI_IF
 SG_ pdc_distanceRSR : 60|3@1+ (1,0) [0|7] ""  IVI_IF
 SG_ pdc_sensorFaultRSR : 63|1@1+ (1,0) [0|1] ""  IVI_IF

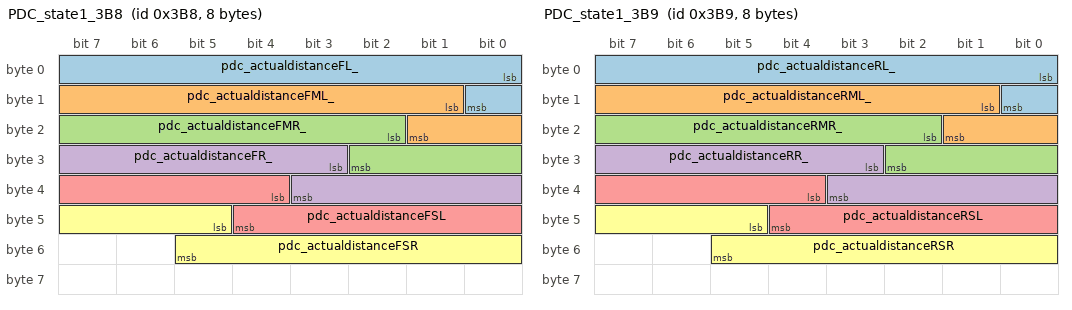
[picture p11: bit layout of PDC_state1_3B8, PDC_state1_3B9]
BO_ 952 PDC_state1_3B8: 8 GW_IF
 SG_ pdc_actualdistanceFL_ : 0|9@1+ (1,0) [0|500] "cm"  IVI_IF
 SG_ pdc_actualdistanceFML_ : 9|9@1+ (1,0) [0|500] "cm"  IVI_IF
 SG_ pdc_actualdistanceFMR_ : 18|9@1+ (1,0) [0|500] "cm"  IVI_IF
 SG_ pdc_actualdistanceFR_ : 27|9@1+ (1,0) [0|500] "cm"  IVI_IF
 SG_ pdc_actualdistanceFSL : 36|9@1+ (1,0) [0|500] "cm"  IVI_IF
 SG_ pdc_actualdistanceFSR : 45|9@1+ (1,0) [0|500] "cm"  IVI_IF

BO_ 953 PDC_state1_3B9: 8 GW_IF
 SG_ pdc_actualdistanceRL_ : 0|9@1+ (1,0) [0|500] "cm"  IVI_IF
 SG_ pdc_actualdistanceRML_ : 9|9@1+ (1,0) [0|500] "cm"  IVI_IF
 SG_ pdc_actualdistanceRMR_ : 18|9@1+ (1,0) [0|500] "cm"  IVI_IF
 SG_ pdc_actualdistanceRR_ : 27|9@1+ (1,0) [0|500] "cm"  IVI_IF
 SG_ pdc_actualdistanceRSL : 36|9@1+ (1,0) [0|500] "cm"  IVI_IF
 SG_ pdc_actualdistanceRSR : 45|9@1+ (1,0) [0|500] "cm"  IVI_IF

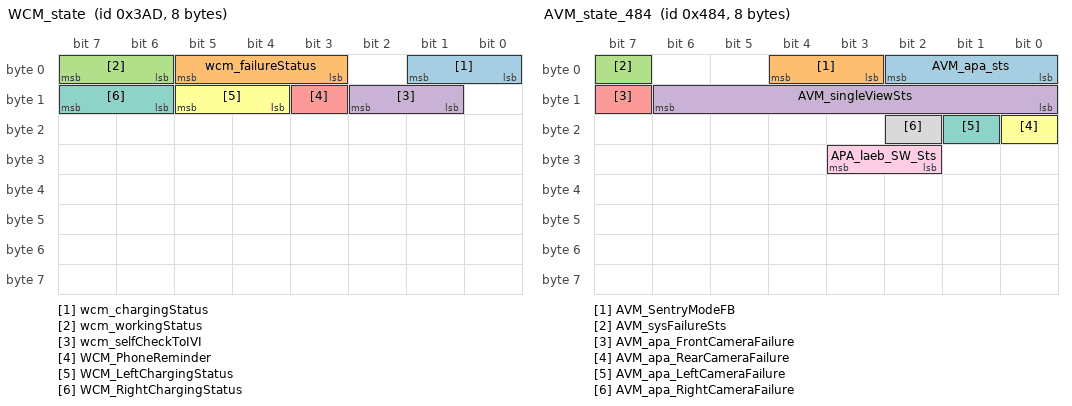
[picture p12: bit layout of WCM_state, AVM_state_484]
BO_ 941 WCM_state: 8 GW_IF
 SG_ wcm_chargingStatus : 0|2@1+ (1,0) [0|3] ""  IVI_IF
 SG_ wcm_failureStatus : 3|3@1+ (1,0) [0|7] ""  IVI_IF
 SG_ wcm_workingStatus : 6|2@1+ (1,0) [0|3] ""  IVI_IF
 SG_ wcm_selfCheckToIVI : 9|2@1+ (1,0) [0|3] ""  IVI_IF
 SG_ WCM_PhoneReminder : 11|1@1+ (1,0) [0|1] ""  IVI_IF
 SG_ WCM_LeftChargingStatus : 12|2@1+ (1,0) [0|3] ""  IVI_IF
 SG_ WCM_RightChargingStatus : 14|2@1+ (1,0) [0|3] ""  IVI_IF

BO_ 1156 AVM_state_484: 8 GW_IF
 SG_ AVM_apa_sts : 0|3@1+ (1,0) [0|7] ""  IVI_IF
 SG_ AVM_SentryModeFB : 3|2@1+ (1,0) [0|3] ""  IVI_IF
 SG_ AVM_sysFailureSts : 7|1@1+ (1,0) [0|1] ""  IVI_IF
 SG_ AVM_singleViewSts : 8|7@1+ (1,0) [0|63] ""  IVI_IF
 SG_ AVM_apa_FrontCameraFailure : 15|1@1+ (1,0) [0|1] ""  IVI_IF
 SG_ AVM_apa_RearCameraFailure : 16|1@1+ (1,0) [0|1] ""  IVI_IF
 SG_ AVM_apa_LeftCameraFailure : 17|1@1+ (1,0) [0|1] ""  IVI_IF
 SG_ AVM_apa_RightCameraFailure : 18|1@1+ (1,0) [0|1] ""  IVI_IF
 SG_ APA_laeb_SW_Sts : 26|2@1+ (1,0) [0|3] ""  IVI_IF

BO_ 1018 HUD_state: 8 HUD
 SG_ hud_onOffSts : 0|1@1+ (1,0) [0|1] ""  IVI_IF

BO_ 169 MFW_Ctrl: 8 MFW
 SG_ MFW_PRE_Key : 0|2@1+ (1,0) [0|3] ""  IVI_IF,GW_IF
 SG_ MFW_NEXT_Key : 2|2@1+ (1,0) [0|3] ""  IVI_IF,GW_IF
 SG_ MFW_VolumeUp_Key : 4|2@1+ (1,0) [0|3] ""  IVI_IF,GW_IF
 SG_ MFW_VolumeDown_Key : 6|2@1+ (1,0) [0|3] ""  IVI_IF,GW_IF
 SG_ MFW_PlayPause_Key : 8|2@1+ (1,0) [0|3] ""  IVI_IF,GW_IF
 SG_ MFW_Answer_Key : 10|2@1+ (1,0) [0|3] ""  IVI_IF,GW_IF
 SG_ MFW_HangUp_Key : 12|2@1+ (1,0) [0|3] ""  IVI_IF,GW_IF
 SG_ MFW_APA_AVM_Key : 14|2@1+ (1,0) [0|3] ""  IVI_IF,GW_IF
 SG_ MFW_PageUP_Key : 16|2@1+ (1,0) [0|3] ""  IVI_IF,GW_IF
 SG_ MFW_PageDown_Key : 18|2@1+ (1,0) [0|3] ""  IVI_IF,GW_IF
 SG_ MFW_Interface_Key : 20|2@1+ (1,0) [0|3] ""  IVI_IF,GW_IF
 SG_ MFW_VoiceButton_Key : 22|2@1+ (1,0) [0|3] ""  IVI_IF,GW_IF
 SG_ MFW_CustomButton1_Key : 24|2@1+ (1,0) [0|3] ""  IVI_IF,GW_IF
 SG_ MFW_ExhibitionMode : 26|2@1+ (1,0) [0|3] ""  IVI_IF,GW_IF
 SG_ MFW_TJAICAACTIVEKeySts : 28|2@1+ (1,0) [0|3] ""  IVI_IF,GW_IF
 SG_ MFW_TJAICAACTIVEKeyStsValid : 30|1@1+ (1,0) [0|1] ""  IVI_IF,GW_IF
 SG_ MFW_IVI_Reset : 32|2@1+ (1,0) [0|3] ""  IVI_IF,GW_IF

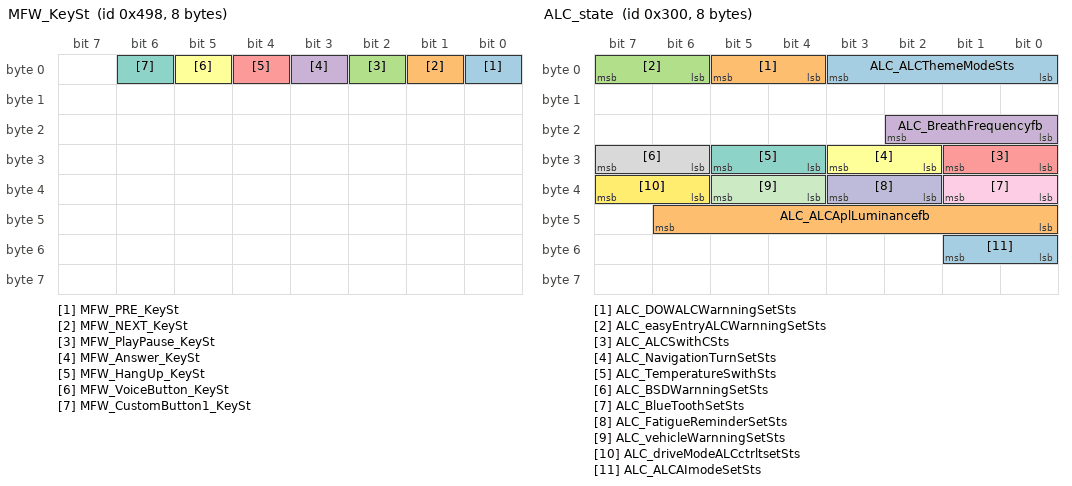
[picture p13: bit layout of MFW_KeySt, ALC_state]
BO_ 1176 MFW_KeySt: 8 MFW
 SG_ MFW_PRE_KeySt : 0|1@1+ (1,0) [0|1] ""  IVI_IF
 SG_ MFW_NEXT_KeySt : 1|1@1+ (1,0) [0|1] ""  IVI_IF
 SG_ MFW_PlayPause_KeySt : 2|1@1+ (1,0) [0|1] ""  IVI_IF
 SG_ MFW_Answer_KeySt : 3|1@1+ (1,0) [0|1] ""  IVI_IF
 SG_ MFW_HangUp_KeySt : 4|1@1+ (1,0) [0|1] ""  IVI_IF
 SG_ MFW_VoiceButton_KeySt : 5|1@1+ (1,0) [0|1] ""  IVI_IF
 SG_ MFW_CustomButton1_KeySt : 6|1@1+ (1,0) [0|1] ""  IVI_IF

BO_ 1141 SWHC_475: 8 MFW
 SG_ SWHC_SterringWheelHeatSts : 0|3@1+ (1,0) [0|7] ""  IVI_IF,GW_IF
 SG_ SWHC_SterringWheelHeatFaultReaso : 3|4@1+ (1,0) [0|15] ""  IVI_IF,GW_IF

BO_ 768 ALC_state: 8 ALC
 SG_ ALC_ALCThemeModeSts : 0|4@1+ (1,0) [0|15] ""  IVI_IF
 SG_ ALC_DOWALCWarnningSetSts : 4|2@1+ (1,0) [0|3] ""  IVI_IF
 SG_ ALC_easyEntryALCWarnningSetSts : 6|2@1+ (1,0) [0|3] ""  IVI_IF
 SG_ ALC_BreathFrequencyfb : 16|3@1+ (1,0) [0|7] ""  IVI_IF
 SG_ ALC_ALCSwithCSts : 24|2@1+ (1,0) [0|3] ""  IVI_IF
 SG_ ALC_NavigationTurnSetSts : 26|2@1+ (1,0) [0|3] ""  IVI_IF
 SG_ ALC_TemperatureSwithSts : 28|2@1+ (1,0) [0|3] ""  IVI_IF
 SG_ ALC_BSDWarnningSetSts : 30|2@1+ (1,0) [0|3] ""  IVI_IF
 SG_ ALC_BlueToothSetSts : 32|2@1+ (1,0) [0|3] ""  IVI_IF
 SG_ ALC_FatigueReminderSetSts : 34|2@1+ (1,0) [0|3] ""  IVI_IF
 SG_ ALC_vehicleWarnningSetSts : 36|2@1+ (1,0) [0|3] ""  IVI_IF
 SG_ ALC_driveModeALCctrltsetSts : 38|2@1+ (1,0) [0|3] ""  IVI_IF
 SG_ ALC_ALCAImodeSetSts : 48|2@1+ (1,0) [0|3] ""  IVI_IF
 SG_ ALC_ALCAplLuminancefb : 40|7@1+ (1,0) [0|127] ""  IVI_IF

BO_ 385 IC_info_181: 8 IC
 SG_ ic_displayFail : 34|1@1+ (1,0) [0|1] ""  IVI_IF
 SG_ ic_IllumiLevelSts : 59|5@1+ (1,0) [0|31] ""  IVI_IF

BO_ 754 IC_state: 8 IVI_IF
 SG_ ic_totalMileage : 0|24@1+ (0.1,0) [0|1677721.4] "km"  GW_IF
 SG_ ic_RRSeatDetectSts : 27|1@1+ (1,0) [0|1] ""  ALC,GW_IF
 SG_ ic_RMSeatDetectSts : 26|1@1+ (1,0) [0|1] ""  ALC,GW_IF
 SG_ ic_lowSocIndication : 24|1@1+ (1,0) [0|1] ""  HUD,GW_IF
 SG_ ic_passengerSeatDetectSts : 25|1@1+ (1,0) [0|1] ""  ALC,GW_IF
 SG_ ic_2ndRowLeftSeatBeltSts : 28|1@1+ (1,0) [0|1] ""  ALC,GW_IF
 SG_ ic_2ndRowLeftSeatBeltStsValid : 29|1@1+ (1,0) [0|1] ""  ALC,GW_IF
 SG_ ic_2ndRowMiddleSeatBeltSts : 30|1@1+ (1,0) [0|1] ""  GW_IF
 SG_ ic_2ndRowMiddleSeatBeltStsValid : 31|1@1+ (1,0) [0|1] ""  GW_IF
 SG_ ic_2ndRowRightSeatBeltSts : 32|1@1+ (1,0) [0|1] ""  ALC,GW_IF
 SG_ ic_2ndRowRightSeatBeltStsValid : 33|1@1+ (1,0) [0|1] ""  ALC,GW_IF
 SG_ ic_displayFail : 34|1@1+ (1,0) [0|1] ""  GW_IF
 SG_ ic_qDashACCFail : 35|2@1+ (1,0) [0|3] ""  GW_IF
 SG_ ic_RLSeatDetectSts : 39|1@1+ (1,0) [0|1] ""  ALC,GW_IF
 SG_ ic_vehicleSpeedDisp : 40|9@1+ (1,0) [0|280] "KPH"  HUD,GW_IF
 SG_ ic_brakeFluidLevel : 49|1@1+ (1,0) [0|1] ""  GW_IF
 SG_ ic_totalMileageValid : 50|1@1+ (1,0) [0|1] ""  GW_IF
 SG_ ic_vehicleSpeedDispValid : 51|1@1+ (1,0) [0|1] ""  HUD,GW_IF
 SG_ ic_state_rollingCounter : 52|4@1+ (1,0) [0|15] ""  GW_IF
 SG_ ic_state_CheckSum : 56|8@1+ (1,0) [0|255] ""  GW_IF

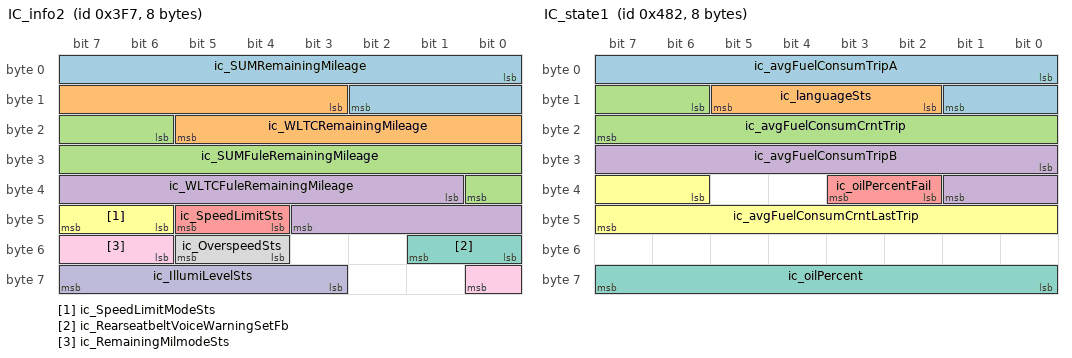
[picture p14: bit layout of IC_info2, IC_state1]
BO_ 1015 IC_info2: 8 IVI_IF
 SG_ ic_SUMRemainingMileage : 0|11@1+ (1,0) [0|2047] "km"  GW_IF
 SG_ ic_WLTCRemainingMileage : 11|11@1+ (1,0) [0|2047] "km"  GW_IF
 SG_ ic_SUMFuleRemainingMileage : 22|11@1+ (1,0) [0|2047] "km"  GW_IF
 SG_ ic_WLTCFuleRemainingMileage : 33|11@1+ (1,0) [0|2047] "km"  GW_IF
 SG_ ic_SpeedLimitSts : 44|2@1+ (1,0) [0|3] ""  GW_IF
 SG_ ic_SpeedLimitModeSts : 46|2@1+ (1,0) [0|3] ""  GW_IF
 SG_ ic_RearseatbeltVoiceWarningSetFb : 48|2@1+ (1,0) [0|3] ""  GW_IF
 SG_ ic_OverspeedSts : 52|2@1+ (1,0) [0|3] ""  GW_IF
 SG_ ic_RemainingMilmodeSts : 54|3@1+ (1,0) [0|7] ""  GW_IF
 SG_ ic_IllumiLevelSts : 59|5@1+ (1,0) [0|31] ""  GW_IF

BO_ 1154 IC_state1: 8 IVI_IF
 SG_ ic_avgFuelConsumTripA : 0|10@1+ (0.1,0) [0|99.9] "L/100km" Vector__XXX
 SG_ ic_languageSts : 10|4@1+ (1,0) [0|15] "" Vector__XXX
 SG_ ic_avgFuelConsumCrntTrip : 14|10@1+ (0.1,0) [0|99.9] "L/100km" Vector__XXX
 SG_ ic_avgFuelConsumTripB : 24|10@1+ (0.1,0) [0|99.9] "L/100km" Vector__XXX
 SG_ ic_oilPercentFail : 34|2@1+ (1,0) [0|3] ""  GW_IF
 SG_ ic_avgFuelConsumCrntLastTrip : 38|10@1+ (0.1,0) [0|99.9] "L/100km" Vector__XXX
 SG_ ic_oilPercent : 56|8@1+ (1,0) [0|100] "%" Vector__XXX

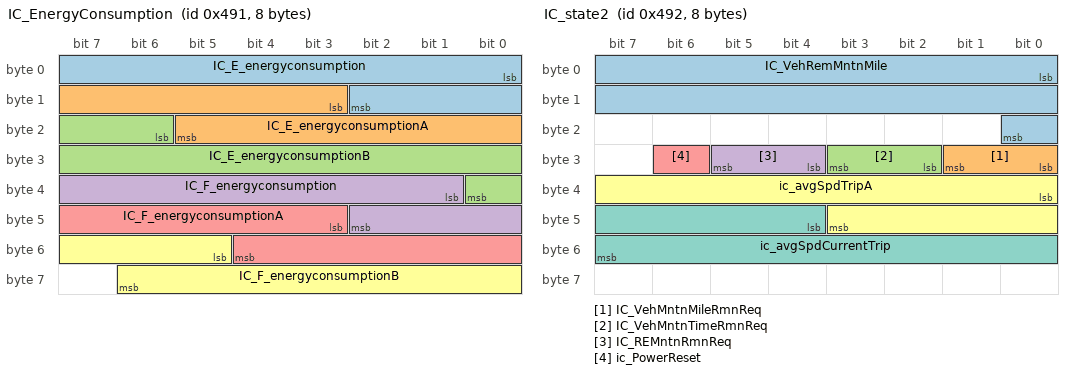
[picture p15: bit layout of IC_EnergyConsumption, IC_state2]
BO_ 1169 IC_EnergyConsumption: 8 IVI_IF
 SG_ IC_E_energyconsumption : 0|11@1+ (0.1,-50) [-50|154.7] "kWh/100km" Vector__XXX
 SG_ IC_E_energyconsumptionA : 11|11@1+ (0.1,-50) [-50|154.7] "kWh/100km" Vector__XXX
 SG_ IC_E_energyconsumptionB : 22|11@1+ (0.1,-50) [-50|154.7] "kWh/100km" Vector__XXX
 SG_ IC_F_energyconsumption : 33|10@1+ (0.1,0) [0|99.9] "L/100km" Vector__XXX
 SG_ IC_F_energyconsumptionA : 43|10@1+ (0.1,0) [0|99.9] "L/100km" Vector__XXX
 SG_ IC_F_energyconsumptionB : 53|10@1+ (0.1,0) [0|99.9] "L/100km" Vector__XXX

BO_ 1170 IC_state2: 8 IVI_IF
 SG_ IC_VehRemMntnMile : 0|17@1+ (1,0) [0|131071] "Km"  GW_IF
 SG_ IC_VehMntnMileRmnReq : 24|2@1+ (1,0) [0|3] ""  GW_IF
 SG_ IC_VehMntnTimeRmnReq : 26|2@1+ (1,0) [0|3] ""  GW_IF
 SG_ IC_REMntnRmnReq : 28|2@1+ (1,0) [0|3] ""  GW_IF
 SG_ ic_PowerReset : 30|1@1+ (1,0) [0|1] ""  GW_IF
 SG_ ic_avgSpdTripA : 32|12@1+ (0.1,0) [0|280] "min"  GW_IF
 SG_ ic_avgSpdCurrentTrip : 44|12@1+ (0.1,0) [0|280] "KPH"  GW_IF

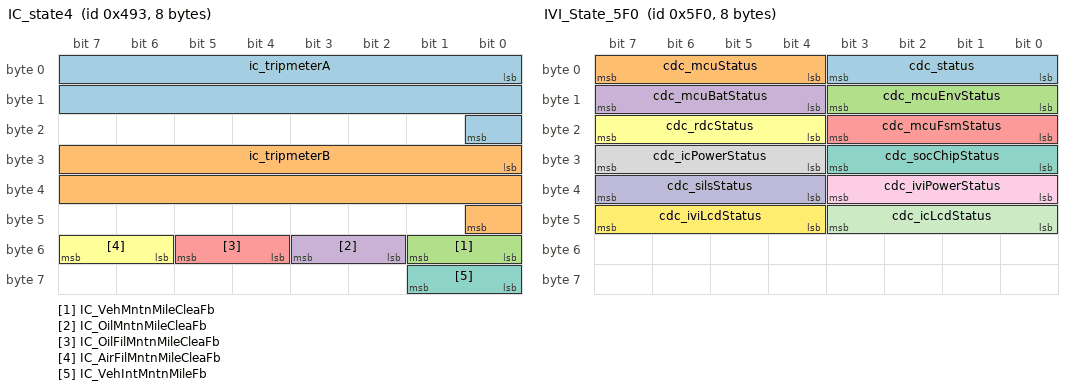
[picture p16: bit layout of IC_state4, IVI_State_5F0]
BO_ 1171 IC_state4: 8 IVI_IF
 SG_ ic_tripmeterA : 0|17@1+ (0.1,0) [0|10000] "km"  GW_IF
 SG_ ic_tripmeterB : 24|17@1+ (0.1,0) [0|10000] "km"  GW_IF
 SG_ IC_VehMntnMileCleaFb : 48|2@1+ (1,0) [0|3] "" Vector__XXX
 SG_ IC_OilMntnMileCleaFb : 50|2@1+ (1,0) [0|3] "" Vector__XXX
 SG_ IC_OilFilMntnMileCleaFb : 52|2@1+ (1,0) [0|3] "" Vector__XXX
 SG_ IC_AirFilMntnMileCleaFb : 54|2@1+ (1,0) [0|3] "" Vector__XXX
 SG_ IC_VehIntMntnMileFb : 56|2@1+ (1,0) [0|3] "" Vector__XXX

BO_ 1172 IC_state5: 8 IVI_IF
 SG_ IC_OilRemMntnMile : 0|17@1+ (1,0) [0|131071] "Km"  GW_IF
 SG_ IC_VehRemMntnTime : 17|9@1+ (1,0) [0|511] "天"  GW_IF
 SG_ IC_OilFilRemMntnMile : 26|17@1+ (1,0) [0|131071] "Km"  GW_IF
 SG_ IC_AirFilRemMntnMile : 43|17@1+ (1,0) [0|131071] "Km"  GW_IF

BO_ 1173 IVI_StatusAndNotify: 8 IVI_IF
 SG_ IVI_FrameType : 0|4@1+ (1,0) [0|15] ""  GW_IF
 SG_ IVI_WorkStatus : 4|4@1+ (1,0) [0|15] ""  GW_IF
 SG_ IVI_CurrentVideo : 8|4@1+ (1,0) [0|15] ""  GW_IF
 SG_ IVI_EventNotify : 12|4@1+ (1,0) [0|15] ""  GW_IF
 SG_ IVI_IC_Sync : 16|4@1+ (1,0) [0|15] ""  GW_IF
 SG_ IVI_Respitemodests : 20|2@1+ (1,0) [0|3] ""  ALC
 SG_ IVI_ModeSts : 22|2@1+ (1,0) [0|3] ""  GW_IF
 SG_ IVI_averagePowerConsumThisTrip : 24|14@1+ (0.1,0) [0|1000] "kw/h"  GW_IF
 SG_ IVI_SentryReq : 38|2@1+ (1,0) [0|3] ""  GW_IF
 SG_ IVI_SentryAlarmSts : 40|2@1+ (1,0) [0|3] ""  ALC,GW_IF
 SG_ IVI_ModeReq : 42|2@1+ (1,0) [0|3] ""  GW_IF
 SG_ IVI_SentryTimeFd : 44|5@1+ (1,0) [0|31] ""  GW_IF
 SG_ IVI_RangeExtenderdisenable : 49|2@1+ (1,0) [0|3] ""  GW_IF
 SG_ IVI_ChildrenLeftremindSts : 51|2@1+ (1,0) [0|3] ""  GW_IF
 SG_ IVI_PetModeSts : 53|2@1+ (1,0) [0|3] ""  GW_IF
 SG_ IVI_SentryFaultReason : 55|5@1+ (1,0) [0|31] ""  GW_IF
 SG_ IVI_WashModeSts : 60|2@1+ (1,0) [0|3] ""  GW_IF
 SG_ IVI_HCUcontrol : 62|2@1+ (1,0) [0|3] ""  GW_IF

BO_ 1174 IVI_hmi: 8 IVI_IF
 SG_ IVI_DMS_DistractionIcon : 0|3@1+ (1,0) [0|7] ""  GW_IF
 SG_ IVI_DMS_FatigueIcon : 3|3@1+ (1,0) [0|7] ""  ALC,GW_IF
 SG_ IVI_DMS_Res1 : 16|8@1+ (1,0) [0|255] ""  GW_IF
 SG_ IVI_DMS_Res2 : 24|8@1+ (1,0) [0|255] ""  GW_IF
 SG_ IVI_DMS_Res3 : 32|8@1+ (1,0) [0|255] ""  GW_IF

BO_ 1520 IVI_State_5F0: 8 IVI_IF
 SG_ cdc_status : 0|4@1+ (1,0) [0|15] "" Vector__XXX
 SG_ cdc_mcuStatus : 4|4@1+ (1,0) [0|15] "" Vector__XXX
 SG_ cdc_mcuEnvStatus : 8|4@1+ (1,0) [0|15] "" Vector__XXX
 SG_ cdc_mcuBatStatus : 12|4@1+ (1,0) [0|15] "" Vector__XXX
 SG_ cdc_mcuFsmStatus : 16|4@1+ (1,0) [0|15] "" Vector__XXX
 SG_ cdc_rdcStatus : 20|4@1+ (1,0) [0|15] "" Vector__XXX
 SG_ cdc_socChipStatus : 24|4@1+ (1,0) [0|15] "" Vector__XXX
 SG_ cdc_icPowerStatus : 28|4@1+ (1,0) [0|15] "" Vector__XXX
 SG_ cdc_iviPowerStatus : 32|4@1+ (1,0) [0|15] "%" Vector__XXX
 SG_ cdc_silsStatus : 36|4@1+ (1,0) [0|15] "" Vector__XXX
 SG_ cdc_icLcdStatus : 40|4@1+ (1,0) [0|15] "" Vector__XXX
 SG_ cdc_iviLcdStatus : 44|4@1+ (1,0) [0|15] "" Vector__XXX

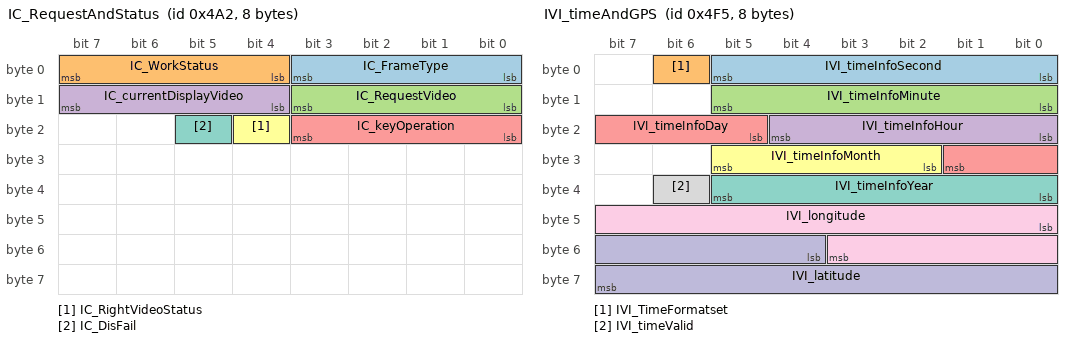
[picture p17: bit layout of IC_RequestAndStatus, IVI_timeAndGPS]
BO_ 1186 IC_RequestAndStatus: 8 IVI_IF
 SG_ IC_FrameType : 0|4@1+ (1,0) [0|15] "" Vector__XXX
 SG_ IC_WorkStatus : 4|4@1+ (1,0) [0|15] "" Vector__XXX
 SG_ IC_RequestVideo : 8|4@1+ (1,0) [0|15] "" Vector__XXX
 SG_ IC_currentDisplayVideo : 12|4@1+ (1,0) [0|15] "" Vector__XXX
 SG_ IC_keyOperation : 16|4@1+ (1,0) [0|15] "" Vector__XXX
 SG_ IC_RightVideoStatus : 20|1@1+ (1,0) [0|1] "" Vector__XXX
 SG_ IC_DisFail : 21|1@1+ (1,0) [0|1] "" Vector__XXX

BO_ 949 IVI_set: 8 IVI_IF
 SG_ ivi_hvacDefrostMode : 0|1@1+ (1,0) [0|1] ""  GW_IF
 SG_ ivi_hvacOnOffReq : 1|1@1+ (1,0) [0|1] ""  GW_IF
 SG_ IVI_ExhibitionScene : 2|2@1+ (1,0) [0|3] ""  GW_IF
 SG_ ivi_hvacAutoModeReq : 8|1@1+ (1,0) [0|1] ""  GW_IF
 SG_ ivi_hvacRecircModeReq : 9|1@1+ (1,0) [0|1] ""  GW_IF
 SG_ ivi_hvacModeReq : 16|3@1+ (1,0) [0|7] ""  GW_IF
 SG_ ivi_driverTempCSet : 19|5@1+ (0.5,17.5) [17.5|32.5] "degreeC"  GW_IF
 SG_ ivi_hvacBlowLvReq : 24|3@1+ (1,0) [0|7] ""  GW_IF
 SG_ ivi_passengerTempCSet : 27|5@1+ (0.5,17.5) [17.5|32.5] "degreeC"  GW_IF
 SG_ ivi_hvacDualMode : 32|1@1+ (1,0) [0|1] ""  GW_IF
 SG_ ivi_acReq : 34|1@1+ (1,0) [0|1] ""  GW_IF
 SG_ IVI_NavigatioRecircReq : 35|2@1+ (1,0) [0|3] ""  GW_IF
 SG_ IVI_NaviTunnelstatus : 37|1@1+ (1,0) [0|1] ""  GW_IF
 SG_ IVI_ScreenOutReq : 38|2@1+ (1,0) [0|3] "" Vector__XXX
 SG_ USB_Sts : 42|2@1+ (1,0) [0|3] ""  GW_IF
 SG_ ivi_svcSteerInteractionSetReserv : 44|1@1+ (1,0) [0|1] ""  GW_IF
 SG_ ivi_InterfaceSwitchReq : 46|2@1+ (1,0) [0|3] ""  GW_IF
 SG_ ivi_languageSet : 48|2@1+ (1,0) [0|3] ""  HUD,GW_IF
 SG_ ivi_unitSet : 52|2@1+ (1,0) [0|3] ""  HUD,GW_IF
 SG_ IVI_IntPuficationSw : 50|2@1+ (1,0) [0|3] ""  GW_IF
 SG_ IVI_NaturalwindSw : 54|2@1+ (1,0) [0|3] ""  GW_IF
 SG_ IVI_VideoResult : 57|2@1+ (1,0) [0|3] ""  GW_IF
 SG_ IVI_AutoRainWiperReq : 59|2@1+ (1,0) [0|3] ""  GW_IF
 SG_ IVI_TakePhotoReq : 61|3@1+ (1,0) [0|7] ""  GW_IF

BO_ 1269 IVI_timeAndGPS: 8 IVI_IF
 SG_ IVI_timeInfoSecond : 0|6@1+ (1,0) [0|59] ""  ALC,GW_IF
 SG_ IVI_TimeFormatset : 6|1@1+ (1,0) [0|1] "" Vector__XXX
 SG_ IVI_timeInfoMinute : 8|6@1+ (1,0) [0|59] ""  ALC,GW_IF
 SG_ IVI_timeInfoHour : 16|5@1+ (1,0) [0|23] ""  ALC,GW_IF
 SG_ IVI_timeInfoDay : 21|5@1+ (1,0) [1|31] ""  ALC,GW_IF
 SG_ IVI_timeInfoMonth : 26|4@1+ (1,0) [1|12] ""  ALC,GW_IF
 SG_ IVI_timeInfoYear : 32|6@1+ (1,0) [0|59] ""  ALC,GW_IF
 SG_ IVI_timeValid : 38|1@1+ (1,0) [0|1] ""  ALC,GW_IF
 SG_ IVI_longitude : 40|12@1+ (0.1,-180) [-180|180] "degree"  ALC,GW_IF
 SG_ IVI_latitude : 52|12@1+ (0.1,-180) [-180|180] "degree"  ALC,GW_IF

BO_ 1157 IVI_navi: 8 IVI_IF
 SG_ ivi_crossNaviMode : 0|7@1+ (1,0) [0|127] ""  HUD,ALC
 SG_ ivi_crossNaviDistance : 28|20@1+ (1,0) [0|999999] "m(米"  HUD,ALC
 SG_ ivi_naviDirection : 24|4@1+ (1,0) [0|15] ""  HUD

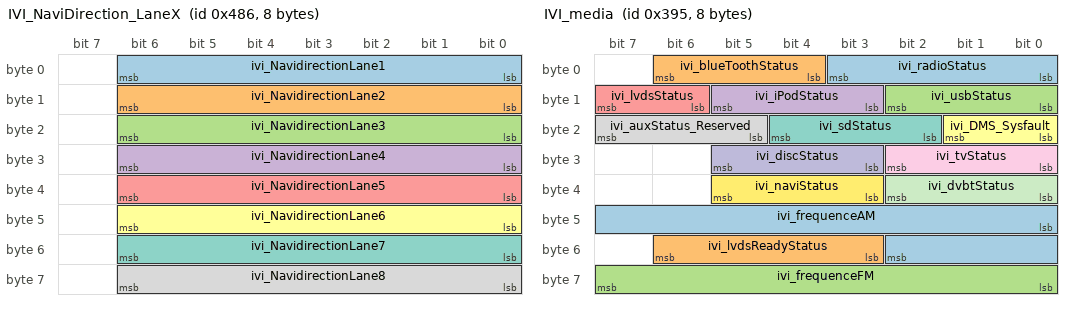
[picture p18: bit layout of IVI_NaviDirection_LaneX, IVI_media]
BO_ 1158 IVI_NaviDirection_LaneX: 8 IVI_IF
 SG_ ivi_NavidirectionLane1 : 0|7@1+ (1,0) [0|127] ""  HUD
 SG_ ivi_NavidirectionLane2 : 8|7@1+ (1,0) [0|127] ""  HUD
 SG_ ivi_NavidirectionLane3 : 16|7@1+ (1,0) [0|127] ""  HUD
 SG_ ivi_NavidirectionLane4 : 24|7@1+ (1,0) [0|127] ""  HUD
 SG_ ivi_NavidirectionLane5 : 32|7@1+ (1,0) [0|127] ""  HUD
 SG_ ivi_NavidirectionLane6 : 40|7@1+ (1,0) [0|127] ""  HUD
 SG_ ivi_NavidirectionLane7 : 48|7@1+ (1,0) [0|127] ""  HUD
 SG_ ivi_NavidirectionLane8 : 56|7@1+ (1,0) [0|127] ""  HUD

BO_ 917 IVI_media: 8 IVI_IF
 SG_ ivi_radioStatus : 0|4@1+ (1,0) [0|15] ""  HUD,GW_IF
 SG_ ivi_blueToothStatus : 4|3@1+ (1,0) [0|7] ""  HUD,GW_IF
 SG_ ivi_usbStatus : 8|3@1+ (1,0) [0|7] ""  HUD,GW_IF
 SG_ ivi_iPodStatus : 11|3@1+ (1,0) [0|7] ""  GW_IF
 SG_ ivi_lvdsStatus : 14|2@1+ (1,0) [0|3] ""  GW_IF
 SG_ ivi_DMS_Sysfault : 16|2@1+ (1,0) [0|3] ""  GW_IF
 SG_ ivi_sdStatus : 18|3@1+ (1,0) [0|7] ""  GW_IF
 SG_ ivi_auxStatus_Reserved : 21|3@1+ (1,0) [0|7] ""  HUD,GW_IF
 SG_ ivi_tvStatus : 24|3@1+ (1,0) [0|7] ""  GW_IF
 SG_ ivi_discStatus : 27|3@1+ (1,0) [0|7] ""  GW_IF
 SG_ ivi_dvbtStatus : 32|3@1+ (1,0) [0|7] ""  GW_IF
 SG_ ivi_naviStatus : 35|3@1+ (1,0) [0|7] ""  HUD,GW_IF
 SG_ ivi_frequenceAM : 40|11@1+ (1,522) [522|1620] "KHZ"  HUD,GW_IF
 SG_ ivi_lvdsReadyStatus : 51|4@1+ (1,0) [0|15] ""  GW_IF
 SG_ ivi_frequenceFM : 56|8@1+ (0.1,87.5) [87.5|108] "MHZ"  HUD,GW_IF

BO_ 965 IVI_naviText: 8 IVI_IF
 SG_ ivi_naviTextStrLength : 0|6@1+ (1,0) [0|63] ""  HUD
 SG_ ivi_naviTextCountNum : 8|4@1+ (1,0) [0|15] ""  HUD
 SG_ ivi_naviText1 : 16|16@1+ (1,0) [0|65535] ""  HUD
 SG_ ivi_naviText2 : 32|16@1+ (1,0) [0|65535] ""  HUD
 SG_ ivi_naviText3 : 48|16@1+ (1,0) [0|65535] ""  HUD

BO_ 975 ECALL_3CF: 8 ECALL
 SG_ ECALL_EcallState : 5|3@1+ (1,0) [0|7] ""  IVI_IF

BO_ 81 ECALL_051: 8 ECALL
 SG_ ECALL_EcallReq : 6|2@1+ (1,0) [0|3] ""  IVI_IF
 SG_ ECALL_MUTE : 4|2@1+ (1,0) [0|3] ""  IVI_IF

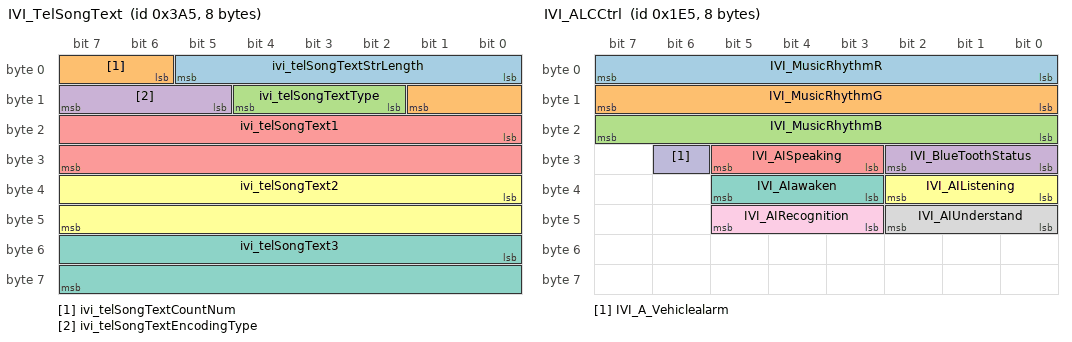
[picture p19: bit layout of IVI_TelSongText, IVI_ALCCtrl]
BO_ 933 IVI_TelSongText: 8 IVI_IF
 SG_ ivi_telSongTextStrLength : 0|6@1+ (1,0) [0|63] ""  HUD
 SG_ ivi_telSongTextCountNum : 6|4@1+ (1,0) [0|15] ""  HUD
 SG_ ivi_telSongTextType : 10|3@1+ (1,0) [0|7] ""  HUD
 SG_ ivi_telSongTextEncodingType : 13|3@1+ (1,0) [0|7] ""  HUD
 SG_ ivi_telSongText1 : 16|16@1+ (1,0) [0|65535] ""  HUD
 SG_ ivi_telSongText2 : 32|16@1+ (1,0) [0|65535] ""  HUD
 SG_ ivi_telSongText3 : 48|16@1+ (1,0) [0|65535] ""  HUD

BO_ 485 IVI_ALCCtrl: 8 IVI_IF
 SG_ IVI_MusicRhythmR : 0|8@1+ (1,0) [0|255] ""  ALC
 SG_ IVI_MusicRhythmG : 8|8@1+ (1,0) [0|255] ""  ALC
 SG_ IVI_MusicRhythmB : 16|8@1+ (1,0) [0|255] ""  ALC
 SG_ IVI_BlueToothStatus : 24|3@1+ (1,0) [0|7] ""  ALC
 SG_ IVI_AISpeaking : 27|3@1+ (1,0) [0|7] ""  ALC
 SG_ IVI_AIListening : 32|3@1+ (1,0) [0|7] ""  ALC
 SG_ IVI_AIawaken : 35|3@1+ (1,0) [0|7] ""  ALC
 SG_ IVI_AIUnderstand : 40|3@1+ (1,0) [0|7] ""  ALC
 SG_ IVI_AIRecognition : 43|3@1+ (1,0) [0|7] ""  ALC
 SG_ IVI_A_Vehiclealarm : 30|1@1+ (1,0) [0|1] ""  ALC

BO_ 1570 NM_IVI: 8 IVI_IF
 SG_ NM_IVI_SourceNodeIdentifier : 0|8@1+ (1,0) [0|255] "" Vector__XXX
 SG_ NM_IVI_RepeatMessageRequestBit : 8|1@1+ (1,0) [0|1] "" Vector__XXX
 SG_ NM_IVI_ActiveWakeup_Bit : 12|1@1+ (1,0) [0|1] "" Vector__XXX
 SG_ NM_IVI_RepeatSts : 16|1@1+ (1,0) [0|1] "" Vector__XXX
 SG_ NMIVI_Active_Source : 24|4@1+ (1,0) [0|15] "" Vector__XXX

BO_ 862 GTW_BMS_Rev: 8 GW_IF
 SG_ obc_acVoltage : 0|16@1+ (0.1,0) [0|6553.5] "V"  IVI_IF
 SG_ obc_acCurrent : 16|12@1+ (0.1,0) [0|409.5] "A"  IVI_IF
 SG_ CCU_CompressorState : 28|3@1+ (1,0) [0|7] ""  IVI_IF
 SG_ vcu_PTC_Request : 31|2@1+ (1,0) [0|3] ""  IVI_IF
 SG_ bms_v2vChrgConnection : 53|1@1+ (1,0) [0|1] ""  IVI_IF

BO_ 1829 Diag_PhyReq_IVI: 8 GW_IF
 SG_ Diag_PhyReq_IVI_Data : 0|64@1+ (1,0) [0|0] "N/A"  IVI_IF

BO_ 1957 Diag_Resp_IVI: 8 IVI_IF
 SG_ Diag_Resp_IVI_Data : 0|64@1+ (1,0) [0|0] "N/A"  GW_IF

CM_ SG_ 197 ivi_darkIllumiLevelSetReserved "darkilluminationlevelset
夜晚亮度同步等级预留";
CM_ SG_ 197 ivi_TripSwitchReserved "TripSwitch
IVI与IC同步里程显示预留";
CM_ SG_ 197 IVI_RearseatbeltVoiceWarningSet "后排安全带未系声音报警开关
RearseatbeltVoiceWarningSet";
CM_ SG_ 197 ivi_hudOnOffSet "HUDONOFFset.";
CM_ SG_ 197 IVI_PEBSVoiceWarningSet "PEBSVoiceWarningSetSwitch
PEBS声音开关";
CM_ SG_ 197 ivi_NaviSwitchReserved "ivi_NaviSwitch预留
Navi按键";
CM_ SG_ 197 ivi_themeSetReserved "ICThememodeset.
IC主题设置预留";
CM_ SG_ 197 ivi_wcmOnOffSet "WCMONOFFset.";
CM_ SG_ 197 ivi_pdcOnOffSet "PDCONOFFset.";
CM_ SG_ 197 ivi_ICthemegangedSetReserved "ivi_ICthemegangedSet
仪表和大屏主题联动开关设置预留";
CM_ SG_ 197 ivi_ICIllumiLevelSet "仪表亮度设置信号";
CM_ SG_ 197 IVI_laeb_SW "Laeb功能设置开关";
CM_ SG_ 197 ivi_IllumiLevelSetReserved "illuminationlevelset
白天亮度同步等级预留";
CM_ SG_ 198 IVI_VehIntMntnMile "整车间隔保养里程设置";
CM_ SG_ 198 IVI_VehMntnMileClea "整车保养里程清零重置";
CM_ SG_ 198 IVI_OilMntnMileClea "机油保养里程重置";
CM_ SG_ 198 IVI_OilFilMntnMileClea "机油滤清器保养里程重置";
CM_ SG_ 198 IVI_AirFilMntnMileClea "空气滤清器保养里程重置";
CM_ SG_ 198 IVI_VehMntnTimeClea "整车保养时间重置";
CM_ SG_ 978 ivi_AVMXCoordinate "Xcoordinate
AVM画面按键坐标，X坐标";
CM_ SG_ 978 ivi_AVMYCoordinate "Ycoordinate
AVM画面按键坐标，Y坐标";
CM_ SG_ 978 ivi_AVMCoTouchMotion "AVMimageuserTouchorreleasecoordinate
AVM画面下，用户点击及释放坐标状态";
CM_ SG_ 978 ivi_IVIthemeSet1 "大屏模式设置信号";
CM_ SG_ 978 IVI_TakeINVideoPosReq "车内停车监控请求";
CM_ SG_ 978 IVI_TakePhotoFaultReason "停车拍照失败原因";
CM_ SG_ 978 IVI_AlarmListrequest "故障列表置位请求";
CM_ SG_ 978 IVI_driveModeSts "驾驶模式信号";
CM_ SG_ 978 IVI_PetFaultReason "宠物模式开启失败的原因";
CM_ SG_ 245 ivi_easyEntrySet "Easyentryfunctionset.";
CM_ SG_ 245 ivi_drSeatHeatLevelSet "Driverseatheatinglevelset.";
CM_ SG_ 245 ivi_drSeatVentLevelSet "DriverseatVentinglevelset.";
CM_ SG_ 245 ivi_passSeatHeatLevelSet "Passengerseatheatinglevelset.";
CM_ SG_ 245 ivi_passSeatVentLevelSet "PassengerseatVentinglevelset.";
CM_ SG_ 245 ivi_drSeatMassLevelSet "DriverseatMassagelevelset.";
CM_ SG_ 245 ivi_passSeatMassLevelSet "PassengerseatMassagelevelset.";
CM_ SG_ 245 ivi_MirrorAutoFoldUnfoldSet "Mirrorautofold/unfoldfunctionset.
后视镜折叠设置";
CM_ SG_ 245 IVI_RLSeatHeatLevelSet "Rearleftheatinglevelset.
后排左侧座椅加热等级设置";
CM_ SG_ 245 ivi_DrMassgIntenSet "DriverSeatmassageIntenSet";
CM_ SG_ 245 ivi_PsgMassgIntenSet "PassSeatmassageIntenSet";
CM_ SG_ 245 IVI_DSMMemoryReq "座椅记忆请求";
CM_ SG_ 245 IVI_RRSeatHeatLevelSet "RearrightseatVentinglevelset.
后排右侧加热等级设置";
CM_ SG_ 796 ivi_ElVent1LocationActuator "地址执行器";
CM_ SG_ 796 ivi_ElVent1ProgrammingDataSave "保存编程数据";
CM_ SG_ 796 ivi_ElVent1ObstructionCheck "阻塞检测";
CM_ SG_ 796 ivi_ElVent1MarkClear "清除标记";
CM_ SG_ 796 ivi_ElVent1CoilElectrify "线圈通电";
CM_ SG_ 796 ivi_ElVent1LocationSelect "位置选择";
CM_ SG_ 796 ivi_ElVent1SpeedMode "速度模式";
CM_ SG_ 796 ivi_ElVent1MotorTargetLocation "电机目标位置";
CM_ SG_ 796 ivi_ElVent1MotorOriginalLocation "电机起始位置";
CM_ SG_ 796 ivi_ElVent1EmergencyStopSwitch "急停开关";
CM_ SG_ 796 ivi_ElVent1EmergencyStopLocation "急停位置";
CM_ SG_ 796 ivi_ElVent1RotationMode "旋转方式";
CM_ SG_ 796 ivi_ElVent1StopMode "停止模式";
CM_ SG_ 797 ivi_ElVent2LocationActuator "地址执行器";
CM_ SG_ 797 ivi_ElVent2ProgrammingDataSave "保存编程数据";
CM_ SG_ 797 ivi_ElVent2ObstructionCheck "阻塞检测";
CM_ SG_ 797 ivi_ElVent2MarkClear "清除标记";
CM_ SG_ 797 ivi_ElVent2CoilElectrify "线圈通电";
CM_ SG_ 797 ivi_ElVent2LocationSelect "位置选择";
CM_ SG_ 797 ivi_ElVent2SpeedMode "速度模式";
CM_ SG_ 797 ivi_ElVent2MotorTargetLocation "电机目标位置";
CM_ SG_ 797 ivi_ElVent2MotorOriginalLocation "电机起始位置";
CM_ SG_ 797 ivi_ElVent2EmergencyStopSwitch "急停开关";
CM_ SG_ 797 ivi_ElVent2EmergencyStopLocation "急停位置";
CM_ SG_ 797 ivi_ElVent2RotationMode "旋转方式";
CM_ SG_ 797 ivi_ElVent2StopMode "停止模式";
CM_ SG_ 805 ivi_ElVent3LocationActuator "地址执行器";
CM_ SG_ 805 ivi_ElVent3ProgrammingDataSave "保存编程数据";
CM_ SG_ 805 ivi_ElVent3ObstructionCheck "阻塞检测";
CM_ SG_ 805 ivi_ElVent3MarkClear "清除标记";
CM_ SG_ 805 ivi_ElVent3CoilElectrify "线圈通电";
CM_ SG_ 805 ivi_ElVent3LocationSelect "位置选择";
CM_ SG_ 805 ivi_ElVent3SpeedMode "速度模式";
CM_ SG_ 805 ivi_ElVent3MotorTargetLocation "电机目标位置";
CM_ SG_ 805 ivi_ElVent3MotorOriginalLocation "电机起始位置";
CM_ SG_ 805 ivi_ElVent3EmergencyStopSwitch "急停开关";
CM_ SG_ 805 ivi_ElVent3EmergencyStopLocation "急停位置";
CM_ SG_ 805 ivi_ElVent3RotationMode "旋转方式";
CM_ SG_ 805 ivi_ElVent3StopMode "停止模式";
CM_ SG_ 808 ivi_ElVent4LocationActuator "地址执行器";
CM_ SG_ 808 ivi_ElVent4ProgrammingDataSave "保存编程数据";
CM_ SG_ 808 ivi_ElVent4ObstructionCheck "阻塞检测";
CM_ SG_ 808 ivi_ElVent4MarkClear "清除标记";
CM_ SG_ 808 ivi_ElVent4CoilElectrify "线圈通电";
CM_ SG_ 808 ivi_ElVent4LocationSelect "位置选择";
CM_ SG_ 808 ivi_ElVent4SpeedMode "速度模式";
CM_ SG_ 808 ivi_ElVent4MotorTargetLocation "电机目标位置";
CM_ SG_ 808 ivi_ElVent4MotorOriginalLocation "电机起始位置";
CM_ SG_ 808 ivi_ElVent4EmergencyStopSwitch "急停开关";
CM_ SG_ 808 ivi_ElVent4EmergencyStopLocation "急停位置";
CM_ SG_ 808 ivi_ElVent4RotationMode "旋转方式";
CM_ SG_ 808 ivi_ElVent4StopMode "停止模式";
CM_ SG_ 826 ivi_ElVent5LocationActuator "地址执行器";
CM_ SG_ 826 ivi_ElVent5ProgrammingDataSave "保存编程数据";
CM_ SG_ 826 ivi_ElVent5ObstructionCheck "阻塞检测";
CM_ SG_ 826 ivi_ElVent5MarkClear "清除标记";
CM_ SG_ 826 ivi_ElVent5CoilElectrify "线圈通电";
CM_ SG_ 826 ivi_ElVent5LocationSelect "位置选择";
CM_ SG_ 826 ivi_ElVent5SpeedMode "速度模式";
CM_ SG_ 826 ivi_ElVent5MotorTargetLocation "电机目标位置";
CM_ SG_ 826 ivi_ElVent5MotorOriginalLocation "电机起始位置";
CM_ SG_ 826 ivi_ElVent5EmergencyStopSwitch "急停开关";
CM_ SG_ 826 ivi_ElVent5EmergencyStopLocation "急停位置";
CM_ SG_ 826 ivi_ElVent5RotationMode "旋转方式";
CM_ SG_ 826 ivi_ElVent5StopMode "停止模式";
CM_ SG_ 827 ivi_ElVent6LocationActuator "地址执行器";
CM_ SG_ 827 ivi_ElVent6ProgrammingDataSave "保存编程数据";
CM_ SG_ 827 ivi_ElVent6ObstructionCheck "阻塞检测";
CM_ SG_ 827 ivi_ElVent6MarkClear "清除标记";
CM_ SG_ 827 ivi_ElVent6CoilElectrify "线圈通电";
CM_ SG_ 827 ivi_ElVent6LocationSelect "位置选择";
CM_ SG_ 827 ivi_ElVent6SpeedMode "速度模式";
CM_ SG_ 827 ivi_ElVent6MotorTargetLocation "电机目标位置";
CM_ SG_ 827 ivi_ElVent6MotorOriginalLocation "电机起始位置";
CM_ SG_ 827 ivi_ElVent6EmergencyStopSwitch "急停开关";
CM_ SG_ 827 ivi_ElVent6EmergencyStopLocation "急停位置";
CM_ SG_ 827 ivi_ElVent6RotationMode "旋转方式";
CM_ SG_ 827 ivi_ElVent6StopMode "停止模式";
CM_ SG_ 842 ivi_ElVent7LocationActuator "地址执行器";
CM_ SG_ 842 ivi_ElVent7ProgrammingDataSave "保存编程数据";
CM_ SG_ 842 ivi_ElVent7ObstructionCheck "阻塞检测";
CM_ SG_ 842 ivi_ElVent7MarkClear "清除标记";
CM_ SG_ 842 ivi_ElVent7CoilElectrify "线圈通电";
CM_ SG_ 842 ivi_ElVent7LocationSelect "位置选择";
CM_ SG_ 842 ivi_ElVent7SpeedMode "速度模式";
CM_ SG_ 842 ivi_ElVent7MotorTargetLocation "电机目标位置";
CM_ SG_ 842 ivi_ElVent7MotorOriginalLocation "电机起始位置";
CM_ SG_ 842 ivi_ElVent7EmergencyStopSwitch "急停开关";
CM_ SG_ 842 ivi_ElVent7EmergencyStopLocation "急停位置";
CM_ SG_ 842 ivi_ElVent7RotationMode "旋转方式";
CM_ SG_ 842 ivi_ElVent7StopMode "停止模式";
CM_ SG_ 843 ivi_ElVent8LocationActuator "地址执行器";
CM_ SG_ 843 ivi_ElVent8ProgrammingDataSave "保存编程数据";
CM_ SG_ 843 ivi_ElVent8ObstructionCheck "阻塞检测";
CM_ SG_ 843 ivi_ElVent8MarkClear "清除标记";
CM_ SG_ 843 ivi_ElVent8CoilElectrify "线圈通电";
CM_ SG_ 843 ivi_ElVent8LocationSelect "位置选择";
CM_ SG_ 843 ivi_ElVent8SpeedMode "速度模式";
CM_ SG_ 843 ivi_ElVent8MotorTargetLocation "电机目标位置";
CM_ SG_ 843 ivi_ElVent8MotorOriginalLocation "电机起始位置";
CM_ SG_ 843 ivi_ElVent8EmergencyStopSwitch "急停开关";
CM_ SG_ 843 ivi_ElVent8EmergencyStopLocation "急停位置";
CM_ SG_ 843 ivi_ElVent8RotationMode "旋转方式";
CM_ SG_ 843 ivi_ElVent8StopMode "停止模式";
CM_ SG_ 966 gw_ElVent1ErrorStatus "错误信息";
CM_ SG_ 966 gw_ElVent1OverHeatStatus "过热状态";
CM_ SG_ 966 gw_ElVent1ElectricalFailureSts "电气缺陷";
CM_ SG_ 966 gw_ElVent1VoltageStatus "电压状态";
CM_ SG_ 966 gw_ElVent1EmergencyRunningSts "紧急运行状态";
CM_ SG_ 966 gw_ElVent1ObstructionDetect "阻塞检测";
CM_ SG_ 966 gw_ElVent1ObstructionStatus "阻塞状态";
CM_ SG_ 966 gw_ElVent1ResetStatus "复位状态";
CM_ SG_ 966 gw_ElVent1CoilStatus "线圈状态";
CM_ SG_ 966 gw_ElVent1LocationStatus "定位状态";
CM_ SG_ 966 gw_ElVent1SpeedStatus "速度状态";
CM_ SG_ 966 gw_ElVent1MotorCurrentLocation "电机当前位置";
CM_ SG_ 966 gw_ElVent1MotorDrivingDirection "驱动方向";
CM_ SG_ 966 gw_ElVent1TorqueKeepingSts "保持扭矩";
CM_ SG_ 966 gw_ElVent1SpecialFunction "特殊功能";
CM_ SG_ 966 gw_ElVent1LocationActuator "地址执行器";
CM_ SG_ 966 gw_ElVent1EmgyStopSwitchSts "急停开关";
CM_ SG_ 966 gw_ElVent1EmgyStopSLocation "急停位置";
CM_ SG_ 966 gw_ElVent1RotationMode "旋转方式";
CM_ SG_ 966 gw_ElVent1StopStatus "停止状态";
CM_ SG_ 967 gw_ElVent2ErrorStatus "错误信息";
CM_ SG_ 967 gw_ElVent2OverHeatStatus "过热状态";
CM_ SG_ 967 gw_ElVent2ElectricalFailureSts "电气缺陷";
CM_ SG_ 967 gw_ElVent2VoltageStatus "电压状态";
CM_ SG_ 967 gw_ElVent2EmergencyRunningSts "紧急运行状态";
CM_ SG_ 967 gw_ElVent2ObstructionDetect "阻塞检测";
CM_ SG_ 967 gw_ElVent2ObstructionStatus "阻塞状态";
CM_ SG_ 967 gw_ElVent2ResetStatus "复位状态";
CM_ SG_ 967 gw_ElVent2CoilStatus "线圈状态";
CM_ SG_ 967 gw_ElVent2LocationStatus "定位状态";
CM_ SG_ 967 gw_ElVent2SpeedStatus "速度状态";
CM_ SG_ 967 gw_ElVent2MotorCurrentLocation "电机当前位置";
CM_ SG_ 967 gw_ElVent2MotorDrivingDirection "驱动方向";
CM_ SG_ 967 gw_ElVent2TorqueKeepingSts "保持扭矩";
CM_ SG_ 967 gw_ElVent2SpecialFunction "特殊功能";
CM_ SG_ 967 gw_ElVent2LocationActuator "地址执行器";
CM_ SG_ 967 gw_ElVent2EmgyStopSwitchSts "急停开关";
CM_ SG_ 967 gw_ElVent2EmgyStopSLocation "急停位置";
CM_ SG_ 967 gw_ElVent2RotationMode "旋转方式";
CM_ SG_ 967 gw_ElVent2StopStatus "停止状态";
CM_ SG_ 968 gw_ElVent3ErrorStatus "错误信息";
CM_ SG_ 968 gw_ElVent3OverHeatStatus "过热状态";
CM_ SG_ 968 gw_ElVent3ElectricalFailureSts "电气缺陷";
CM_ SG_ 968 gw_ElVent3VoltageStatus "电压状态";
CM_ SG_ 968 gw_ElVent3EmergencyRunningSts "紧急运行状态";
CM_ SG_ 968 gw_ElVent3ObstructionDetect "阻塞检测";
CM_ SG_ 968 gw_ElVent3ObstructionStatus "阻塞状态";
CM_ SG_ 968 gw_ElVent3ResetStatus "复位状态";
CM_ SG_ 968 gw_ElVent3CoilStatus "线圈状态";
CM_ SG_ 968 gw_ElVent3LocationStatus "定位状态";
CM_ SG_ 968 gw_ElVent3SpeedStatus "速度状态";
CM_ SG_ 968 gw_ElVent3MotorCurrentLocation "电机当前位置";
CM_ SG_ 968 gw_ElVent3MotorDrivingDirection "驱动方向";
CM_ SG_ 968 gw_ElVent3TorqueKeepingSts "保持扭矩";
CM_ SG_ 968 gw_ElVent3SpecialFunction "特殊功能";
CM_ SG_ 968 gw_ElVent3LocationActuator "地址执行器";
CM_ SG_ 968 gw_ElVent3EmgyStopSwitchSts "急停开关";
CM_ SG_ 968 gw_ElVent3EmgyStopSLocation "急停位置";
CM_ SG_ 968 gw_ElVent3RotationMode "旋转方式";
CM_ SG_ 968 gw_ElVent3StopStatus "停止状态";
CM_ SG_ 969 gw_ElVent4ErrorStatus "错误信息";
CM_ SG_ 969 gw_ElVent4OverHeatStatus "过热状态";
CM_ SG_ 969 gw_ElVent4ElectricalFailureSts "电气缺陷";
CM_ SG_ 969 gw_ElVent4VoltageStatus "电压状态";
CM_ SG_ 969 gw_ElVent4EmergencyRunningSts "紧急运行状态";
CM_ SG_ 969 gw_ElVent4ObstructionDetect "阻塞检测";
CM_ SG_ 969 gw_ElVent4ObstructionStatus "阻塞状态";
CM_ SG_ 969 gw_ElVent4ResetStatus "复位状态";
CM_ SG_ 969 gw_ElVent4CoilStatus "线圈状态";
CM_ SG_ 969 gw_ElVent4LocationStatus "定位状态";
CM_ SG_ 969 gw_ElVent4SpeedStatus "速度状态";
CM_ SG_ 969 gw_ElVent4MotorCurrentLocation "电机当前位置";
CM_ SG_ 969 gw_ElVent4MotorDrivingDirection "驱动方向";
CM_ SG_ 969 gw_ElVent4TorqueKeepingSts "保持扭矩";
CM_ SG_ 969 gw_ElVent4SpecialFunction "特殊功能";
CM_ SG_ 969 gw_ElVent4LocationActuator "地址执行器";
CM_ SG_ 969 gw_ElVent4EmgyStopSwitchSts "急停开关";
CM_ SG_ 969 gw_ElVent4EmgyStopSLocation "急停位置";
CM_ SG_ 969 gw_ElVent4RotationMode "旋转方式";
CM_ SG_ 969 gw_ElVent4StopStatus "停止状态";
CM_ SG_ 970 gw_ElVent5ErrorStatus "错误信息";
CM_ SG_ 970 gw_ElVent5OverHeatStatus "过热状态";
CM_ SG_ 970 gw_ElVent5ElectricalFailureSts "电气缺陷";
CM_ SG_ 970 gw_ElVent5VoltageStatus "电压状态";
CM_ SG_ 970 gw_ElVent5EmergencyRunningSts "紧急运行状态";
CM_ SG_ 970 gw_ElVent5ObstructionDetect "阻塞检测";
CM_ SG_ 970 gw_ElVent5ObstructionStatus "阻塞状态";
CM_ SG_ 970 gw_ElVent5ResetStatus "复位状态";
CM_ SG_ 970 gw_ElVent5CoilStatus "线圈状态";
CM_ SG_ 970 gw_ElVent5LocationStatus "定位状态";
CM_ SG_ 970 gw_ElVent5SpeedStatus "速度状态";
CM_ SG_ 970 gw_ElVent5MotorCurrentLocation "电机当前位置";
CM_ SG_ 970 gw_ElVent5MotorDrivingDirection "驱动方向";
CM_ SG_ 970 gw_ElVent5TorqueKeepingSts "保持扭矩";
CM_ SG_ 970 gw_ElVent5SpecialFunction "特殊功能";
CM_ SG_ 970 gw_ElVent5LocationActuator "地址执行器";
CM_ SG_ 970 gw_ElVent5EmgyStopSwitchSts "急停开关";
CM_ SG_ 970 gw_ElVent5EmgyStopSLocation "急停位置";
CM_ SG_ 970 gw_ElVent5RotationMode "旋转方式";
CM_ SG_ 970 gw_ElVent5StopStatus "停止状态";
CM_ SG_ 971 gw_ElVent6ErrorStatus "错误信息";
CM_ SG_ 971 gw_ElVent6OverHeatStatus "过热状态";
CM_ SG_ 971 gw_ElVent6ElectricalFailureSts "电气缺陷";
CM_ SG_ 971 gw_ElVent6VoltageStatus "电压状态";
CM_ SG_ 971 gw_ElVent6EmergencyRunningSts "紧急运行状态";
CM_ SG_ 971 gw_ElVent6ObstructionDetect "阻塞检测";
CM_ SG_ 971 gw_ElVent6ObstructionStatus "阻塞状态";
CM_ SG_ 971 gw_ElVent6ResetStatus "复位状态";
CM_ SG_ 971 gw_ElVent6CoilStatus "线圈状态";
CM_ SG_ 971 gw_ElVent6LocationStatus "定位状态";
CM_ SG_ 971 gw_ElVent6SpeedStatus "速度状态";
CM_ SG_ 971 gw_ElVent6MotorCurrentLocation "电机当前位置";
CM_ SG_ 971 gw_ElVent6MotorDrivingDirection "驱动方向";
CM_ SG_ 971 gw_ElVent6TorqueKeepingSts "保持扭矩";
CM_ SG_ 971 gw_ElVent6SpecialFunction "特殊功能";
CM_ SG_ 971 gw_ElVent6LocationActuator "地址执行器";
CM_ SG_ 971 gw_ElVent6EmgyStopSwitchSts "急停开关";
CM_ SG_ 971 gw_ElVent6EmgyStopSLocation "急停位置";
CM_ SG_ 971 gw_ElVent6RotationMode "旋转方式";
CM_ SG_ 971 gw_ElVent6StopStatus "停止状态";
CM_ SG_ 972 gw_ElVent7ErrorStatus "错误信息";
CM_ SG_ 972 gw_ElVent7OverHeatStatus "过热状态";
CM_ SG_ 972 gw_ElVent7ElectricalFailureSts "电气缺陷";
CM_ SG_ 972 gw_ElVent7VoltageStatus "电压状态";
CM_ SG_ 972 gw_ElVent7EmergencyRunningSts "紧急运行状态";
CM_ SG_ 972 gw_ElVent7ObstructionDetect "阻塞检测";
CM_ SG_ 972 gw_ElVent7ObstructionStatus "阻塞状态";
CM_ SG_ 972 gw_ElVent7ResetStatus "复位状态";
CM_ SG_ 972 gw_ElVent7CoilStatus "线圈状态";
CM_ SG_ 972 gw_ElVent7LocationStatus "定位状态";
CM_ SG_ 972 gw_ElVent7SpeedStatus "速度状态";
CM_ SG_ 972 gw_ElVent7MotorCurrentLocation "电机当前位置";
CM_ SG_ 972 gw_ElVent7MotorDrivingDirection "驱动方向";
CM_ SG_ 972 gw_ElVent7TorqueKeepingSts "保持扭矩";
CM_ SG_ 972 gw_ElVent7SpecialFunction "特殊功能";
CM_ SG_ 972 gw_ElVent7LocationActuator "地址执行器";
CM_ SG_ 972 gw_ElVent7EmgyStopSwitchSts "急停开关";
CM_ SG_ 972 gw_ElVent7EmgyStopSLocation "急停位置";
CM_ SG_ 972 gw_ElVent7RotationMode "旋转方式";
CM_ SG_ 972 gw_ElVent7StopStatus "停止状态";
CM_ SG_ 973 gw_ElVent8ErrorStatus "错误信息";
CM_ SG_ 973 gw_ElVent8OverHeatStatus "过热状态";
CM_ SG_ 973 gw_ElVent8ElectricalFailureSts "电气缺陷";
CM_ SG_ 973 gw_ElVent8VoltageStatus "电压状态";
CM_ SG_ 973 gw_ElVent8EmergencyRunningSts "紧急运行状态";
CM_ SG_ 973 gw_ElVent8ObstructionDetect "阻塞检测";
CM_ SG_ 973 gw_ElVent8ObstructionStatus "阻塞状态";
CM_ SG_ 973 gw_ElVent8ResetStatus "复位状态";
CM_ SG_ 973 gw_ElVent8CoilStatus "线圈状态";
CM_ SG_ 973 gw_ElVent8LocationStatus "定位状态";
CM_ SG_ 973 gw_ElVent8SpeedStatus "速度状态";
CM_ SG_ 973 gw_ElVent8MotorCurrentLocation "电机当前位置";
CM_ SG_ 973 gw_ElVent8MotorDrivingDirection "驱动方向";
CM_ SG_ 973 gw_ElVent8TorqueKeepingSts "保持扭矩";
CM_ SG_ 973 gw_ElVent8SpecialFunction "特殊功能";
CM_ SG_ 973 gw_ElVent8LocationActuator "地址执行器";
CM_ SG_ 973 gw_ElVent8EmgyStopSwitchSts "急停开关";
CM_ SG_ 973 gw_ElVent8EmgyStopSLocation "急停位置";
CM_ SG_ 973 gw_ElVent8RotationMode "旋转方式";
CM_ SG_ 973 gw_ElVent8StopStatus "停止状态";
CM_ SG_ 897 VAP_FragranceWorkingSts "香氛工作状态";
CM_ SG_ 897 VAP_FragranceConcentration "香氛浓度";
CM_ SG_ 897 VAP_FragranceType_Position_1 "位置1香型";
CM_ SG_ 897 VAP_FragranceType_Position_2 "位置2香型";
CM_ SG_ 897 VAP_FragranceType_Position_3 "位置3香型";
CM_ SG_ 897 VAP_FragrancePositionSts "香氛位置设置状态";
CM_ SG_ 897 VAP_OverVoltageFault "电压过高故障状态";
CM_ SG_ 897 VAP_LowVoltageFault "电压过低故障状态";
CM_ SG_ 897 VAP_BusoffFault "Bus-off故障状态";
CM_ SG_ 897 VAP_hardwareFault "控制器硬件故障";
CM_ SG_ 897 VAP_softwareFault "控制器软件故障";
CM_ SG_ 897 VAP_RFIDCRCCheckFault "电子标签CRC校验失败";
CM_ SG_ 897 VAP_Motor_Fault "电机故障";
CM_ SG_ 897 VAP_FAN_Fault "风机故障";
CM_ SG_ 82 ic_engOffTime "引擎熄火时间（分钟）";
CM_ SG_ 82 ic_engOffTimeValid "引擎熄火时间有效标志";
CM_ SG_ 82 IC_songFaultNum "报警声音";
CM_ SG_ 82 IC_songWarningSts "IC_songWarningStatus故障码状态位";
CM_ SG_ 1533 IC_LowBatteryvoltage "蓄电池电压低";
CM_ SG_ 1533 IC_engCoolantTempAlarm "冷却液温度高";
CM_ SG_ 1533 IC_lowfuleAlarm "燃油不足";
CM_ SG_ 1533 IC_lowbrakefluidlevel "制动液位低";
CM_ SG_ 1533 IC_lowoilpressure "机油压力低";
CM_ SG_ 1010 ic_hudScreenTransition "HUDscreentransition.";
CM_ SG_ 1010 ic_hudHeightSet "HUDdisplayheightset.";
CM_ SG_ 1010 ic_hudillumiLvSet "HUDilluminationlevelset.";
CM_ SG_ 1016 IC_driverSeatBeltStatus "Driverseatbeltstatus
主驾安全带状态";
CM_ SG_ 1016 IC_driverSeatBeltStatusValid "Driverseatbeltstatusvailidsignal
主驾安全带状态有效位";
CM_ SG_ 1016 IC_passengerSeatBeltStatus "Passengerseatbeltstatus
副驾安全带状态";
CM_ SG_ 1016 IC_passengerSeatBeltStatusValid "Passengerseatbeltstatusvalidsignal
副驾安全带状态有效位";
CM_ SG_ 1016 IC_CLTCFuleRemainingMileage "CLTC油续航";
CM_ SG_ 1016 IC_CLTCRemainingMileage "CLTC续航";
CM_ SG_ 1016 IC_3F8Counter "IC_3F8Counter";
CM_ SG_ 1016 IC_3F8Checksum "IC_3F8Checksum";
CM_ SG_ 1020 IC_NEDCRemainingMileage "NEDC续航";
CM_ SG_ 1020 IC_NEDCFuleRemainingMileage "NEDC油续航";
CM_ SG_ 1268 ic_avgTimeSincethelastchargeTrip "自上次充电后里程的持续时间";
CM_ SG_ 1268 ic_avgSpdSincethelastchargeTripR "自上次充电后的平均车速";
CM_ SG_ 1268 ic_FuelComsumpV2V "FuelconsumptionduringV2V
V2V互充消耗的油量";
CM_ SG_ 1268 ic_FuelTankResistance "FuelTankResistance
油箱电阻值";
CM_ SG_ 1268 ic_FuelConsumCrntTrip "本次油耗";
CM_ SG_ 1393 IC_AlarmListflag "故障列表请求标志位
（置位后，故障以列表形式传输，未置位，以单个故障传输）";
CM_ SG_ 1393 IC_FaultNum "故障码";
CM_ SG_ 1393 IC_WarningStatus "故障码状态位";
CM_ SG_ 1393 IC_FaultNum2 "故障码（如果故障列表请求标志位置0，不发）";
CM_ SG_ 1393 IC_WarningStatus2 "故障码状态位（如果故障列表请求标志位置0，不发）";
CM_ SG_ 1393 IC_FaultNum3 "故障码（如果故障列表请求标志位置0，不发）";
CM_ SG_ 1393 IC_WarningStatus3 "故障码状态位（如果故障列表请求标志位置0，不发）";
CM_ SG_ 1393 IC_FaultNum4 "故障码（如果故障列表请求标志位置0，不发）";
CM_ SG_ 1393 IC_WarningStatus4 "故障码状态位（如果故障列表请求标志位置0，不发）";
CM_ SG_ 1393 IC_FaultNum5 "故障码（如果故障列表请求标志位置0，不发）";
CM_ SG_ 1393 IC_WarningStatus5 "故障码状态位（如果故障列表请求标志位置0，不发）";
CM_ SG_ 1393 IC_FaultNum6 "故障码（如果故障列表请求标志位置0，不发）";
CM_ SG_ 1393 IC_WarningStatus6 "故障码状态位（如果故障列表请求标志位置0，不发）";
CM_ SG_ 1392 IC_DMS_DistractionIconFB "显示分神图标反馈";
CM_ SG_ 1392 IC_DMS_FatigueIconFB "显示疲劳图标反馈";
CM_ SG_ 1392 IC_DMS_Res1 "DMS功能保留";
CM_ SG_ 1392 IC_DMS_Res2 "DMS功能保留";
CM_ SG_ 1392 IC_DMS_Res3 "DMS功能保留";
CM_ SG_ 990 bms_vPackBmu "Currentbatterypackvoltage.";
CM_ SG_ 990 bms_vPackBms "Currentbatterypackvoltage.";
CM_ SG_ 990 bms_iPack "Currentbatterypackcurrent.";
CM_ SG_ 798 bms_state "系统状态";
CM_ SG_ 798 bms_dcChargeState "直流充电状态";
CM_ SG_ 798 bms_acChargeState "交流充电状态";
CM_ SG_ 798 BMS_HVInterlock_Status "BMS_HVInterlock_Status";
CM_ SG_ 798 bms_isolationState "bms_isolationState";
CM_ SG_ 798 bms_contactorState "bms_contactorState";
CM_ SG_ 798 bms_acChargeConnection "bms_acChargeConnection";
CM_ SG_ 798 bms_dcChargeConnection "bms_dcChargeConnection";
CM_ SG_ 798 bms_authenticationResult "bms_authenticationResult";
CM_ SG_ 798 bms_alertLevel "bms_alertLevel";
CM_ SG_ 798 bms_pPack "Currentbatterypackpower.
电池组总功率";
CM_ SG_ 942 mcur0_speed "MCUF0motorspeed";
CM_ SG_ 942 mcur0_iBus "MCUR0buscurrent.";
CM_ SG_ 942 mcur0_vBus "MCUR0busvoltage.";
CM_ SG_ 942 mcur0_stEgyFlowAndBatt "后电机能量流动";
CM_ SG_ 942 mcur0_faultLevel "mcur1_faultLevel";
CM_ SG_ 942 mcur0_Fault_Light_Ctrl "mcur0_Fault_Light_Ctrl";
CM_ SG_ 958 mcuf0_speed "Frontmotorspeed.";
CM_ SG_ 958 mcuf0_iBus "MCUF0buscurrent.";
CM_ SG_ 958 mcuf0_vBus "MCUF0busvoltage.";
CM_ SG_ 958 mcuf0_stEgyFlowAndBatt "前电机能量流动";
CM_ SG_ 958 mcuf0_Fault_Light_Ctrl "mcuf0_Fault_Light_Ctrl";
CM_ SG_ 894 ecu_engSpeed "enginespeed";
CM_ SG_ 894 ecu_engCoolantTemp "enginecoolanttemperature";
CM_ SG_ 894 ecu_fuelComsump100ms "fuelconsumptionduring100ms";
CM_ SG_ 894 ecu_milIndicator "MILindicatorlight";
CM_ SG_ 894 vcu_coolantLevelLow "冷却液液位低";
CM_ SG_ 894 ecu_state "Enginerunningstatus";
CM_ SG_ 894 vcu_highVoltFail "上高压失败";
CM_ SG_ 894 vcu_Regenmode "整车处于能量回收状态";
CM_ SG_ 894 vcu_accelPosValid "Accelerationpedalpositionvalid.";
CM_ SG_ 547 esc_vehicleSpeed "vehiclereferencespeed";
CM_ SG_ 547 esc_vehicleSpeedValid "vehiclereferencespeedvalidsignal";
CM_ SG_ 547 esc_avhActive "indicatesAVHinactiveornot";
CM_ SG_ 547 esc_avhStandby "indicatesAVHinstandbymodeornot";
CM_ SG_ 547 esc_avhAvailable "HMIResponsible,CANgetdegrateAVHstatementfromDSWandsendout";
CM_ SG_ 547 esc_hdcStatus "indicatesHDCcontrolstatus.";
CM_ SG_ 547 esc_vlcTorqReq "VLCengineTorqueRequest";
CM_ SG_ 547 esc_vlcTorqReqActive "VLCengineTorqueRequestActive";
CM_ SG_ 547 esc_vlcError "IndicatethefailurestatusofVLC";
CM_ SG_ 547 esc_vlcAvalible "IndicatingwhetherVLCisbasicallyreadyforactivationornot.ItcouldbecombinedwithVLCFail.";
CM_ SG_ 547 esc_vlcInterTargetAx "InternalVLCtargetacceleration";
CM_ SG_ 547 esc_vlcActive "IndicatesVLCisactiveornot";
CM_ SG_ 547 eps_modeStatus "EPSmodestatus.";
CM_ SG_ 547 esc_escActive "IndicationthatVDC/TCS(enginetorquecontrolorbraketorquecontrol)systemcurrentlyperformsabrake/engineintervention.";
CM_ SG_ 547 esc_hdcAvailable "HMIResponsible,CANgetdegrateHDCstatementfromDSWandsendout";
CM_ SG_ 547 iB_hmiWarningOn "WiththissignaliBoosterrequeststhewarninglampinthedashboard";
CM_ SG_ 547 iB_hmiWarningOn_Q "QualifierofiB_hmiWarningOn.";
CM_ SG_ 547 esc_hhcAvailable "HMIResponsible,CANgetdegradeHHCstatementfromDSWandsendout
坡道辅助HHC是否可用";
CM_ SG_ 851 eps_torsionBarTorque "EPStorsionbartorque.Leftpositive,rightnegtive.";
CM_ SG_ 851 eps_torsionBarTorqueValid "ValiddataofsignalEPStorsionbartorque.";
CM_ SG_ 590 vcu_brakePedalSts "Indicatingbrakepedalactivatedbydriverornot";
CM_ SG_ 590 vcu_brakePedalStsValid "Indicatingthevalidbitforbrakepedalstatus.";
CM_ SG_ 590 vcu_actualGearValid "Actualgearvalidsignal.";
CM_ SG_ 590 vcu_actualGear "Actualgearengaged.";
CM_ SG_ 590 vcu_totalPowerConsumThisTrip "totalpowerconsumthistrip";
CM_ SG_ 590 vcu_241_rollingCounter "Messagecounterforthemessage";
CM_ SG_ 590 vcu_241_checksum "CRC8,messagechecksum.";
CM_ SG_ 974 ac_ambientTemp "AmbientTemperature
环境温度";
CM_ SG_ 974 ac_cabinTemp "IncarTemperature
车内温度";
CM_ SG_ 974 ac_ambientTempValid "AmbientTemperatureValid
环境温度有效位";
CM_ SG_ 951 pdc_buzzerAlarmPattern "alarmmethodofbuzzer
蜂鸣器报警方式";
CM_ SG_ 951 pdc_modeStatus "operationmodeofparkingdistancecontrol
泊车雷达的工作模式";
CM_ SG_ 951 pdc_distanceFL "Distancedisplayofparkingradarinfrontleftside.
左前雷达显示
NoDistance:120<Distance
Range1:Distance<=35
Range2:35<Distance<=60
Range3:60<Distance<=120
others:reserved";
CM_ SG_ 951 pdc_sensorFaultFL "Frontleftsensorfault.";
CM_ SG_ 951 pdc_distanceFML "Distancedisplayofparkingradarinfrontmiddleleftside
左中前雷达显示
NoDistance:120<Distance
Range1:Distance<=35
Range2:35<Distance<=60
Range3:60<Distance<=120
others:reserved";
CM_ SG_ 951 pdc_sensorFaultFML "Frontmiddleleftsensorfault.";
CM_ SG_ 951 pdc_distanceFMR "Distancedisplayofparkingradarinfrontmiddlerightside
右中前雷达显示
NoDistance:120<Distance
Range1:Distance<=35
Range2:35<Distance<=60
Range3:60<Distance<=120
others:reserved";
CM_ SG_ 951 pdc_sensorFaultFMR "Frontmiddlerightsensorfault.";
CM_ SG_ 951 pdc_distanceFR "Distancedisplayofparkingradarinfrontrightside
右前雷达显示
NoDistance:60<Distance
Range1:Distance<=35
Range2:35<Distance<=60
others:reserved";
CM_ SG_ 951 pdc_sensorFaultFR "Frontrightsensorfault.";
CM_ SG_ 951 pdc_distanceRL "Distancedisplayofparkingradarinfrontleftside
左后雷达显示
NoDistance:120<Distance
Range1:Distance<=35
Range2:35<Distance<=60
Range3:60<Distance<=120
others:reserved";
CM_ SG_ 951 pdc_sensorFaultRL "Rearleftsensorfault.";
CM_ SG_ 951 pdc_distanceRML "Distancedisplayofparkingradarinfrontmiddleleftside
左中后雷达显示
NoDistance:150<Distance
Range1:Distance<=35
Range2:35<Distance<=60
Range3:60<Distance<=90
Range4:60<Distance<=150
others:reserved";
CM_ SG_ 951 pdc_sensorFaultRML "Rearmiddleleftsensorfault.";
CM_ SG_ 951 pdc_distanceRMR "Distancedisplayofparkingradarinrearmiddlerightside
右中后雷达显示
NoDistance:150<Distance
Range1:Distance<=35
Range2:35<Distance<=60
Range3:60<Distance<=90
Range4:60<Distance<=150
others:reserved";
CM_ SG_ 951 pdc_sensorFaultRMR "Rearmiddlerightsensorfault.";
CM_ SG_ 951 pdc_distanceRR "Distancedisplayofparkingradarinrearrightside
右后雷达显示
NoDistance:120<Distance
Range1:Distance<=35
Range2:35<Distance<=60
Range3:60<Distance<=120
others:reserved";
CM_ SG_ 951 pdc_sensorFaultRR "Rearrightsensorfault.";
CM_ SG_ 951 pdc_FrontRadarActiveStatus "前雷达开关状态";
CM_ SG_ 951 pdc_distanceFSL "DistancedisplayofparkingradarinFrontsideleft
前左侧雷达距离显示
NoDistance:120<Distance
Range1:Distance<=35
Range2:35<Distance<=60
Range3:60<Distance<=120
others:reserved";
CM_ SG_ 951 pdc_sensorFaultFSL "Frontsideleftsensorfault.";
CM_ SG_ 951 pdc_distanceFSR "DistancedisplayofparkingradarinFrontsideright
前右侧雷达距离显示
NoDistance:120<Distance
Range1:Distance<=35
Range2:35<Distance<=60
Range3:60<Distance<=120
others:reserved";
CM_ SG_ 951 pdc_sensorFaultFSR "Frontsiderightsensorfault.";
CM_ SG_ 951 pdc_distanceRSL "Distancedisplayofparkingradarinrearsideleft
后左侧雷达距离显示
NoDistance:120<Distance
Range1:Distance<=35
Range2:35<Distance<=60
Range3:60<Distance<=120
others:reserved";
CM_ SG_ 951 pdc_sensorFaultRSL "Frontsideleftsensorfault.";
CM_ SG_ 951 pdc_distanceRSR "Distancedisplayofparkingradarinrearsideright
后右侧雷达距离显示
NoDistance:120<Distance
Range1:Distance<=35
Range2:35<Distance<=60
Range3:60<Distance<=120
others:reserved";
CM_ SG_ 951 pdc_sensorFaultRSR "rearsiderightsensorfault.";
CM_ SG_ 952 pdc_actualdistanceFL_ "左前雷达真实距离";
CM_ SG_ 952 pdc_actualdistanceFML_ "左中前雷达真实距离";
CM_ SG_ 952 pdc_actualdistanceFMR_ "右中前雷达真实距离";
CM_ SG_ 952 pdc_actualdistanceFR_ "右前雷达真实距离";
CM_ SG_ 952 pdc_actualdistanceFSL "左前测雷达真实距离";
CM_ SG_ 952 pdc_actualdistanceFSR "右前测雷达真实距离";
CM_ SG_ 953 pdc_actualdistanceRL_ "左后雷达真实距离";
CM_ SG_ 953 pdc_actualdistanceRML_ "左中后雷达真实距离";
CM_ SG_ 953 pdc_actualdistanceRMR_ "右中后雷达真实距离";
CM_ SG_ 953 pdc_actualdistanceRR_ "右后雷达真实距离";
CM_ SG_ 953 pdc_actualdistanceRSL "左后测雷达真实距离";
CM_ SG_ 953 pdc_actualdistanceRSR "右后侧雷达真实距离";
CM_ SG_ 941 wcm_chargingStatus "Chargingstatus.
充电状态";
CM_ SG_ 941 wcm_failureStatus "WCMfailurestatus.
故障信息";
CM_ SG_ 941 wcm_workingStatus "WCMworkingstatus.
无线充电器工作状态";
CM_ SG_ 941 wcm_selfCheckToIVI "WCMselfCheck无线充电器自检";
CM_ SG_ 941 WCM_PhoneReminder "手机遗忘提醒";
CM_ SG_ 941 WCM_LeftChargingStatus "左侧区域充电状态";
CM_ SG_ 941 WCM_RightChargingStatus "右侧区充电状态";
CM_ SG_ 1156 AVM_apa_sts "AVM的工作状态";
CM_ SG_ 1156 AVM_SentryModeFB "哨兵模式反馈";
CM_ SG_ 1156 AVM_sysFailureSts "Systemfunctionalstatus/failureindication
失效状态";
CM_ SG_ 1156 AVM_singleViewSts "视图状态";
CM_ SG_ 1156 AVM_apa_FrontCameraFailure "前摄像头故障";
CM_ SG_ 1156 AVM_apa_RearCameraFailure "后摄像头故障";
CM_ SG_ 1156 AVM_apa_LeftCameraFailure "左摄像头故障";
CM_ SG_ 1156 AVM_apa_RightCameraFailure "右摄像头故障";
CM_ SG_ 1156 APA_laeb_SW_Sts "LAEB功能开关设置状态";
CM_ SG_ 1018 hud_onOffSts "HUDonoffstatus.";
CM_ SG_ 169 MFW_PRE_Key "上一曲按键";
CM_ SG_ 169 MFW_NEXT_Key "下一曲按键";
CM_ SG_ 169 MFW_VolumeUp_Key "音量增加按键";
CM_ SG_ 169 MFW_VolumeDown_Key "音量减少按键";
CM_ SG_ 169 MFW_PlayPause_Key "播放/暂停按键";
CM_ SG_ 169 MFW_Answer_Key "接听按键";
CM_ SG_ 169 MFW_HangUp_Key "挂断按键";
CM_ SG_ 169 MFW_APA_AVM_Key "APA/全景按键";
CM_ SG_ 169 MFW_PageUP_Key "页面上翻";
CM_ SG_ 169 MFW_PageDown_Key "页面下翻";
CM_ SG_ 169 MFW_Interface_Key "界面切换按键IC使用";
CM_ SG_ 169 MFW_VoiceButton_Key "语音请求按键";
CM_ SG_ 169 MFW_CustomButton1_Key "自定义按键1";
CM_ SG_ 169 MFW_ExhibitionMode "展车模式按键";
CM_ SG_ 169 MFW_TJAICAACTIVEKeySts "TJI/ICA一键激活开关";
CM_ SG_ 169 MFW_TJAICAACTIVEKeyStsValid "TJI/ICA一键激活开关有效位";
CM_ SG_ 169 MFW_IVI_Reset "MFW_IVI_Reset";
CM_ SG_ 1176 MFW_PRE_KeySt "上一曲按键状态";
CM_ SG_ 1176 MFW_NEXT_KeySt "下一曲按键状态";
CM_ SG_ 1176 MFW_PlayPause_KeySt "播放/暂停按键状态";
CM_ SG_ 1176 MFW_Answer_KeySt "接听按键状态";
CM_ SG_ 1176 MFW_HangUp_KeySt "挂断按键状态";
CM_ SG_ 1176 MFW_VoiceButton_KeySt "语音请求按键状态";
CM_ SG_ 1176 MFW_CustomButton1_KeySt "自定义按键1状态";
CM_ SG_ 1141 SWHC_SterringWheelHeatSts "方向盘加热状态";
CM_ SG_ 1141 SWHC_SterringWheelHeatFaultReaso "方向盘加热故障原因";
CM_ SG_ 768 ALC_ALCThemeModeSts "模式状态信号";
CM_ SG_ 768 ALC_DOWALCWarnningSetSts "开门预警控制氛围灯开关反馈信号";
CM_ SG_ 768 ALC_easyEntryALCWarnningSetSts "迎宾控制氛围开关反馈信号";
CM_ SG_ 768 ALC_BreathFrequencyfb "固定色呼吸频率调节反馈";
CM_ SG_ 768 ALC_ALCSwithCSts "氛围灯总开关反馈";
CM_ SG_ 768 ALC_NavigationTurnSetSts "导航转向控制氛围灯开关反馈";
CM_ SG_ 768 ALC_TemperatureSwithSts "氛围灯温度开关反馈";
CM_ SG_ 768 ALC_BSDWarnningSetSts "BSD报警控制氛围灯开关反馈信号";
CM_ SG_ 768 ALC_BlueToothSetSts "ALC_BlueToothSetSts
蓝牙来电控制氛围灯开关反馈";
CM_ SG_ 768 ALC_FatigueReminderSetSts "ALC_FatigueReminderSetSts";
CM_ SG_ 768 ALC_vehicleWarnningSetSts "仪表报警提示控制氛围灯开关反馈信号";
CM_ SG_ 768 ALC_driveModeALCctrltsetSts "切换驾驶模式控制氛围灯开关反馈信号";
CM_ SG_ 768 ALC_ALCAImodeSetSts "氛围灯AI模式开关";
CM_ SG_ 768 ALC_ALCAplLuminancefb "ALC_ALCAplLuminancefb";
CM_ SG_ 385 ic_displayFail "Errorinthedisplayordisplaycontrolunit.ADASReruirment";
CM_ SG_ 385 ic_IllumiLevelSts "仪表亮度反馈";
CM_ SG_ 754 ic_totalMileage "Totalmileage总里程";
CM_ SG_ 754 ic_RRSeatDetectSts "二排座椅右边乘员检测状态";
CM_ SG_ 754 ic_RMSeatDetectSts "二排座椅中间乘员检测状态";
CM_ SG_ 754 ic_lowSocIndication "LowSOCindication";
CM_ SG_ 754 ic_passengerSeatDetectSts "副驾座椅乘员检测状态
passengerdetectionstatus.";
CM_ SG_ 754 ic_2ndRowLeftSeatBeltSts "Secondrowleftseatbeltstatus.";
CM_ SG_ 754 ic_2ndRowLeftSeatBeltStsValid "Secondrowleftseatbeltstatusvalidsignal.";
CM_ SG_ 754 ic_2ndRowMiddleSeatBeltSts "Secondrowmiddleseatbeltstatus.";
CM_ SG_ 754 ic_2ndRowMiddleSeatBeltStsValid "Secondrowmiddleseatbeltstatusvalidsignal.";
CM_ SG_ 754 ic_2ndRowRightSeatBeltSts "Secondrowrightseatbeltstatus.";
CM_ SG_ 754 ic_2ndRowRightSeatBeltStsValid "Secondrowrightseatbeltstatusvalidsignal.";
CM_ SG_ 754 ic_displayFail "Errorinthedisplayordisplaycontrolunit.ADASReruirment";
CM_ SG_ 754 ic_qDashACCFail "ErrorintheACCmessagedetectedbytheHMI,liketimeoutoralivecountererror.
仪表检测到ACC报文错误，例如超时或者AliveCounter错误.";
CM_ SG_ 754 ic_RLSeatDetectSts "二排座椅左边乘员检测状态";
CM_ SG_ 754 ic_vehicleSpeedDisp "ICdisplayedvehiclespeed.";
CM_ SG_ 754 ic_brakeFluidLevel "Brakefluidlevel.";
CM_ SG_ 754 ic_totalMileageValid "Totalmileagevalidsignal.";
CM_ SG_ 754 ic_vehicleSpeedDispValid "ICdisplayedvehiclespeedvalidsignal.";
CM_ SG_ 754 ic_state_rollingCounter "messagerollingcounter.";
CM_ SG_ 754 ic_state_CheckSum "CRC8checksum";
CM_ SG_ 1015 ic_SUMRemainingMileage "RemainingMileage
总综合续航里程";
CM_ SG_ 1015 ic_WLTCRemainingMileage "RemainingMileage
总WLTC续航里程";
CM_ SG_ 1015 ic_SUMFuleRemainingMileage "燃油综合续航里程";
CM_ SG_ 1015 ic_WLTCFuleRemainingMileage "燃油WLTC综合续航里程";
CM_ SG_ 1015 ic_SpeedLimitSts "SpeedLimitOnOffStatus
限速辅助开关反馈状态";
CM_ SG_ 1015 ic_SpeedLimitModeSts "SpeedLimitmodestatus
限速辅助模式反馈";
CM_ SG_ 1015 ic_RearseatbeltVoiceWarningSetFb "后排座椅安全带报警";
CM_ SG_ 1015 ic_OverspeedSts "超速状态";
CM_ SG_ 1015 ic_RemainingMilmodeSts "续航里程显示模式状态反馈";
CM_ SG_ 1015 ic_IllumiLevelSts "仪表亮度反馈";
CM_ SG_ 1154 ic_avgFuelConsumTripA "Tripaveragefuelconsumption.
小计里程A平均油耗";
CM_ SG_ 1154 ic_languageSts "Languagestatus.";
CM_ SG_ 1154 ic_avgFuelConsumCrntTrip "Currenttripaveragefuelconsumption.
本次平均油耗";
CM_ SG_ 1154 ic_avgFuelConsumTripB "Tripaveragefuelconsumption.
小计里程B平均油耗";
CM_ SG_ 1154 ic_oilPercentFail "oilpercentsensorerror";
CM_ SG_ 1154 ic_avgFuelConsumCrntLastTrip "Lasttripaveragefuelconsumption.
自上次充电后的平均油耗";
CM_ SG_ 1154 ic_oilPercent "Oiltankpercent
剩余油量";
CM_ SG_ 1169 IC_E_energyconsumption "当前行程综合能耗（电单位）";
CM_ SG_ 1169 IC_E_energyconsumptionA "行程A综合能耗（电单位）";
CM_ SG_ 1169 IC_E_energyconsumptionB "行程B综合能耗（电单位）";
CM_ SG_ 1169 IC_F_energyconsumption "当前行程综合能耗（油单位）";
CM_ SG_ 1169 IC_F_energyconsumptionA "行程A综合能耗（油单位）";
CM_ SG_ 1169 IC_F_energyconsumptionB "行程B综合能耗（油单位）";
CM_ SG_ 1170 IC_VehRemMntnMile "整车剩余保养里程";
CM_ SG_ 1170 IC_VehMntnMileRmnReq "整车维保里程提醒请求";
CM_ SG_ 1170 IC_VehMntnTimeRmnReq "整车维保时间提醒请求";
CM_ SG_ 1170 IC_REMntnRmnReq "增程器保养提醒请求";
CM_ SG_ 1170 ic_PowerReset "KL30断电复位标志";
CM_ SG_ 1170 ic_avgSpdTripA "Averagevehiclespeedsincetripmeterreset.
小计里程A平均车速";
CM_ SG_ 1170 ic_avgSpdCurrentTrip "Averagevehiclespeedofcurrenttrip.
本次平均车速";
CM_ SG_ 1171 ic_tripmeterA "ICtripmeterA
小计里程A";
CM_ SG_ 1171 ic_tripmeterB "ICtripmeterB
小计里程B";
CM_ SG_ 1171 IC_VehMntnMileCleaFb "整车保养数据重置反馈";
CM_ SG_ 1171 IC_OilMntnMileCleaFb "机油保养里程重置反馈";
CM_ SG_ 1171 IC_OilFilMntnMileCleaFb "机油滤清器保养里程重置反馈";
CM_ SG_ 1171 IC_AirFilMntnMileCleaFb "空气滤清器保养里程重置反馈";
CM_ SG_ 1171 IC_VehIntMntnMileFb "整车间隔保养里程设置反馈";
CM_ SG_ 1172 IC_OilRemMntnMile "机油剩余保养里程值";
CM_ SG_ 1172 IC_VehRemMntnTime "整车剩余保养时间";
CM_ SG_ 1172 IC_OilFilRemMntnMile "机油滤清器剩余保养里程值";
CM_ SG_ 1172 IC_AirFilRemMntnMile "空气滤清器剩余保养里程值";
CM_ SG_ 1173 IVI_FrameType "IVI_FrameType";
CM_ SG_ 1173 IVI_WorkStatus "IVI_WorkStatus";
CM_ SG_ 1173 IVI_CurrentVideo "IVI_CurrentVideo";
CM_ SG_ 1173 IVI_EventNotify "IVI_EventNotify";
CM_ SG_ 1173 IVI_IC_Sync "IVI_IC_Sync";
CM_ SG_ 1173 IVI_Respitemodests "小憩模式状态";
CM_ SG_ 1173 IVI_ModeSts "情景模式状态";
CM_ SG_ 1173 IVI_averagePowerConsumThisTrip "IVI_averagePowerConsumThisTrip";
CM_ SG_ 1173 IVI_SentryReq "哨兵模式进入请求(高阶自动驾驶版才发送次信号）";
CM_ SG_ 1173 IVI_SentryAlarmSts "哨兵状态";
CM_ SG_ 1173 IVI_ModeReq "情景模式进入请求";
CM_ SG_ 1173 IVI_SentryTimeFd "哨兵状态时间设置反馈信号";
CM_ SG_ 1173 IVI_RangeExtenderdisenable "增程器禁止启动请求";
CM_ SG_ 1173 IVI_ChildrenLeftremindSts "儿童遗留提醒状态";
CM_ SG_ 1173 IVI_PetModeSts "宠物状态";
CM_ SG_ 1173 IVI_SentryFaultReason "哨兵模式开启失败的原因";
CM_ SG_ 1173 IVI_WashModeSts "洗车模式状态";
CM_ SG_ 1173 IVI_HCUcontrol "门把手控制命令";
CM_ SG_ 1174 IVI_DMS_DistractionIcon "显示分神图标";
CM_ SG_ 1174 IVI_DMS_FatigueIcon "显示疲劳图标";
CM_ SG_ 1174 IVI_DMS_Res1 "DMS功能保留";
CM_ SG_ 1174 IVI_DMS_Res2 "DMS功能保留";
CM_ SG_ 1174 IVI_DMS_Res3 "DMS功能保留";
CM_ SG_ 1520 cdc_status "CDC域状态(对外接口)";
CM_ SG_ 1520 cdc_mcuStatus "CDC域内mcu状态";
CM_ SG_ 1520 cdc_mcuEnvStatus "CDC域内mcu检测环境状态";
CM_ SG_ 1520 cdc_mcuBatStatus "CDC域内mcu检测供电状态";
CM_ SG_ 1520 cdc_mcuFsmStatus "CDC域内mcu电源管理状态";
CM_ SG_ 1520 cdc_rdcStatus "CDC域内rdc链路状态";
CM_ SG_ 1520 cdc_socChipStatus "CDC域内soc芯片状态";
CM_ SG_ 1520 cdc_icPowerStatus "CDC域内IC仪表电源管理状态";
CM_ SG_ 1520 cdc_iviPowerStatus "CDC域内IVI电源管理状态";
CM_ SG_ 1520 cdc_silsStatus "CDC域内安全岛状态";
CM_ SG_ 1520 cdc_icLcdStatus "CDC域内仪表屏幕状态";
CM_ SG_ 1520 cdc_iviLcdStatus "CDC域内IVI屏幕状态";
CM_ SG_ 1186 IC_FrameType "IC_FrameType";
CM_ SG_ 1186 IC_WorkStatus "IC_WorkStatus";
CM_ SG_ 1186 IC_RequestVideo "IC_RequestVideo";
CM_ SG_ 1186 IC_currentDisplayVideo "IC_currentDisplayVideo";
CM_ SG_ 1186 IC_keyOperation "IC_keyOperation";
CM_ SG_ 1186 IC_RightVideoStatus "仪表右侧显示状态";
CM_ SG_ 1186 IC_DisFail "投屏失败";
CM_ SG_ 949 ivi_hvacDefrostMode "空调前除霜模式控制信号";
CM_ SG_ 949 ivi_hvacOnOffReq "RequestHVACswitchStatus.";
CM_ SG_ 949 IVI_ExhibitionScene "展车模式场景";
CM_ SG_ 949 ivi_hvacAutoModeReq "HVACautomoderequest.";
CM_ SG_ 949 ivi_hvacRecircModeReq "HVACrecirculationmoderequest.";
CM_ SG_ 949 ivi_hvacModeReq "HVACmoderequest.";
CM_ SG_ 949 ivi_driverTempCSet "DriverTemperatureCelsius
驾驶侧设置温度_摄氏度";
CM_ SG_ 949 ivi_hvacBlowLvReq "HVACblowlevelrequest.";
CM_ SG_ 949 ivi_passengerTempCSet "PassengerTemperatureCelsius
乘客侧设置温度_摄氏度";
CM_ SG_ 949 ivi_hvacDualMode "HVACDualmode.
双分区模式";
CM_ SG_ 949 ivi_acReq "RequestthestatusofHVACclutch.";
CM_ SG_ 949 IVI_NavigatioRecircReq "导航隧道空气循环模式";
CM_ SG_ 949 IVI_NaviTunnelstatus "导航隧道状态";
CM_ SG_ 949 IVI_ScreenOutReq "情景模式熄屏";
CM_ SG_ 949 USB_Sts "USB存储状态";
CM_ SG_ 949 ivi_svcSteerInteractionSetReserv "SVCsteeringinteractiononoffswitch.
SVC转向联动功能预留信号";
CM_ SG_ 949 ivi_InterfaceSwitchReq "IVI界面切换开关";
CM_ SG_ 949 ivi_languageSet "Languageset.";
CM_ SG_ 949 ivi_unitSet "Lengthmeasurementunitset.";
CM_ SG_ 949 IVI_IntPuficationSw "智能净化开关";
CM_ SG_ 949 IVI_NaturalwindSw "自然风开关";
CM_ SG_ 949 IVI_VideoResult "视频结果";
CM_ SG_ 949 IVI_AutoRainWiperReq "自动雨刮控制开关";
CM_ SG_ 949 IVI_TakePhotoReq "停车拍照请求";
CM_ SG_ 1269 IVI_timeInfoSecond "IVI_timeInfoSecond";
CM_ SG_ 1269 IVI_TimeFormatset "时间格式设置";
CM_ SG_ 1269 IVI_timeInfoMinute "IVI_timeInfoMinute";
CM_ SG_ 1269 IVI_timeInfoHour "IVI_timeInfoHour";
CM_ SG_ 1269 IVI_timeInfoDay "IVI_timeInfoDay";
CM_ SG_ 1269 IVI_timeInfoMonth "IVI_timeInfoMonth";
CM_ SG_ 1269 IVI_timeInfoYear "IVI_timeInfoYear，startfrom2000";
CM_ SG_ 1269 IVI_timeValid "IVI_timeValid";
CM_ SG_ 1269 IVI_longitude "IVI_longitude";
CM_ SG_ 1269 IVI_latitude "IVI_latitude";
CM_ SG_ 1157 ivi_crossNaviMode "导航转向模式";
CM_ SG_ 1157 ivi_crossNaviDistance "导航转向距离";
CM_ SG_ 1157 ivi_naviDirection "导航方向";
CM_ SG_ 1158 ivi_NavidirectionLane1 "导航方向_车道1";
CM_ SG_ 1158 ivi_NavidirectionLane2 "导航方向_车道2";
CM_ SG_ 1158 ivi_NavidirectionLane3 "导航方向_车道3";
CM_ SG_ 1158 ivi_NavidirectionLane4 "导航方向_车道4";
CM_ SG_ 1158 ivi_NavidirectionLane5 "导航方向_车道5";
CM_ SG_ 1158 ivi_NavidirectionLane6 "导航方向_车道6";
CM_ SG_ 1158 ivi_NavidirectionLane7 "导航方向_车道7";
CM_ SG_ 1158 ivi_NavidirectionLane8 "导航方向_车道8";
CM_ SG_ 917 ivi_radioStatus "收音机连接状态";
CM_ SG_ 917 ivi_blueToothStatus "蓝牙连接状态";
CM_ SG_ 917 ivi_usbStatus "USB连接状态";
CM_ SG_ 917 ivi_iPodStatus "iPod连接状态";
CM_ SG_ 917 ivi_lvdsStatus "导航信息状态反馈";
CM_ SG_ 917 ivi_DMS_Sysfault "DMS系统故障";
CM_ SG_ 917 ivi_sdStatus "SD连接状态";
CM_ SG_ 917 ivi_auxStatus_Reserved "AUX连接状态
预留的信号";
CM_ SG_ 917 ivi_tvStatus "TV连接状态";
CM_ SG_ 917 ivi_discStatus "DISC连接状态";
CM_ SG_ 917 ivi_dvbtStatus "DVBT连接状态";
CM_ SG_ 917 ivi_naviStatus "导航连接状态";
CM_ SG_ 917 ivi_frequenceAM "IVI主机AM频率接收无效值时不显示";
CM_ SG_ 917 ivi_lvdsReadyStatus "当前LVDS画面是否准备就绪";
CM_ SG_ 917 ivi_frequenceFM "IVI主机FM频率接收无效值时不显示";
CM_ SG_ 965 ivi_naviTextStrLength "导航信息文本长度.触发时以20ms周期发送，最多发送10帧.HUD提需求导航文字信息需重复发送一次";
CM_ SG_ 965 ivi_naviTextCountNum "导航信息文本数据包编号";
CM_ SG_ 965 ivi_naviText1 "导航信息文本1";
CM_ SG_ 965 ivi_naviText2 "导航信息文本2";
CM_ SG_ 965 ivi_naviText3 "导航信息文本3";
CM_ SG_ 975 ECALL_EcallState "E-call通话状态";
CM_ SG_ 81 ECALL_EcallReq "E-call请求";
CM_ SG_ 81 ECALL_MUTE "MUTE请求";
CM_ SG_ 933 ivi_telSongTextStrLength "通话或歌曲信息文本长度.触发时以20ms周期发送，最多发送15帧.";
CM_ SG_ 933 ivi_telSongTextCountNum "通话或歌曲信息文本数据包编号";
CM_ SG_ 933 ivi_telSongTextType "通话或歌曲信息文本类型";
CM_ SG_ 933 ivi_telSongTextEncodingType "通话或歌曲信息文本编码方式";
CM_ SG_ 933 ivi_telSongText1 "通话或歌曲信息信息文本1";
CM_ SG_ 933 ivi_telSongText2 "通话或歌曲信息信息文本2";
CM_ SG_ 933 ivi_telSongText3 "通话或歌曲信息信息文本3";
CM_ SG_ 485 IVI_MusicRhythmR "音乐律动氛围灯颜色R值";
CM_ SG_ 485 IVI_MusicRhythmG "音乐律动氛围灯颜色G值";
CM_ SG_ 485 IVI_MusicRhythmB "音乐律动氛围灯颜色B值";
CM_ SG_ 485 IVI_BlueToothStatus "IVI_BlueToothStatus";
CM_ SG_ 485 IVI_AISpeaking "IVI_AISpeaking";
CM_ SG_ 485 IVI_AIListening "IVI_AIListening";
CM_ SG_ 485 IVI_AIawaken "AI唤醒模式信号";
CM_ SG_ 485 IVI_AIUnderstand "AI理解模式信号";
CM_ SG_ 485 IVI_AIRecognition "AI识别模式信号";
CM_ SG_ 485 IVI_A_Vehiclealarm "IVI_A_Vehiclealarm";
CM_ SG_ 1570 NM_IVI_SourceNodeIdentifier "源节点ID";
CM_ SG_ 1570 NM_IVI_RepeatMessageRequestBit "重复报文请求位";
CM_ SG_ 1570 NM_IVI_ActiveWakeup_Bit "主动唤醒标志位";
CM_ SG_ 1570 NM_IVI_RepeatSts "重复报文状态";
CM_ SG_ 1570 NMIVI_Active_Source "唤醒源";
CM_ SG_ 862 obc_acVoltage "OBC交流侧电压";
CM_ SG_ 862 obc_acCurrent "OBC交流侧电流";
CM_ SG_ 862 CCU_CompressorState "CCU_CompressorState";
CM_ SG_ 862 vcu_PTC_Request "PTC加热请求";
CM_ SG_ 862 bms_v2vChrgConnection "bms_v2vChrgConnection";
CM_ SG_ 1829 Diag_PhyReq_IVI_Data "Diag_PhyReq_IVI_Data";
CM_ SG_ 1957 Diag_Resp_IVI_Data "Diag_Resp_IVI_Data";
BA_DEF_ BO_  "GenMsgSendType" ENUM  "Cycle","Event","CE";
BA_DEF_ BO_  "GenMsgCycleTime" INT 0 0;
BA_DEF_ SG_  "GenSigSendType" ENUM  "Cycle","OnChange","OnWrite","IfActive","OnChangeWithRepetition","OnWriteWithRepetition","IfActiveWithRepetition";
BA_DEF_ SG_  "GenSigStartValue" INT 0 0;
BA_DEF_ SG_  "SystemSignalLongSymbol" STRING ;
BA_DEF_DEF_  "GenMsgSendType" "Cycle";
BA_DEF_DEF_  "GenMsgCycleTime" 0;
BA_DEF_DEF_  "GenSigSendType" "Cycle";
BA_DEF_DEF_  "GenSigStartValue" 0;
BA_DEF_DEF_  "SystemSignalLongSymbol" "";
BA_ "GenMsgSendType" BO_ 197 1;
BA_ "GenMsgSendType" BO_ 198 1;
BA_ "GenMsgCycleTime" BO_ 978 100;
BA_ "GenMsgSendType" BO_ 245 1;
BA_ "GenMsgCycleTime" BO_ 796 100;
BA_ "GenMsgCycleTime" BO_ 797 100;
BA_ "GenMsgCycleTime" BO_ 805 100;
BA_ "GenMsgCycleTime" BO_ 808 100;
BA_ "GenMsgCycleTime" BO_ 826 100;
BA_ "GenMsgCycleTime" BO_ 827 100;
BA_ "GenMsgCycleTime" BO_ 842 100;
BA_ "GenMsgCycleTime" BO_ 843 100;
BA_ "GenMsgCycleTime" BO_ 966 100;
BA_ "GenMsgCycleTime" BO_ 967 100;
BA_ "GenMsgCycleTime" BO_ 968 100;
BA_ "GenMsgCycleTime" BO_ 969 100;
BA_ "GenMsgCycleTime" BO_ 970 100;
BA_ "GenMsgCycleTime" BO_ 971 100;
BA_ "GenMsgCycleTime" BO_ 972 100;
BA_ "GenMsgCycleTime" BO_ 973 100;
BA_ "GenMsgCycleTime" BO_ 897 100;
BA_ "GenMsgSendType" BO_ 82 1;
BA_ "GenMsgCycleTime" BO_ 1533 5000;
BA_ "GenMsgCycleTime" BO_ 1010 100;
BA_ "GenMsgCycleTime" BO_ 1016 100;
BA_ "GenMsgCycleTime" BO_ 1020 100;
BA_ "GenMsgCycleTime" BO_ 1268 200;
BA_ "GenMsgCycleTime" BO_ 1393 500;
BA_ "GenMsgCycleTime" BO_ 1392 500;
BA_ "GenMsgCycleTime" BO_ 990 100;
BA_ "GenMsgCycleTime" BO_ 798 100;
BA_ "GenMsgCycleTime" BO_ 942 100;
BA_ "GenMsgCycleTime" BO_ 958 100;
BA_ "GenMsgCycleTime" BO_ 894 100;
BA_ "GenMsgCycleTime" BO_ 547 50;
BA_ "GenMsgCycleTime" BO_ 851 100;
BA_ "GenMsgCycleTime" BO_ 590 20;
BA_ "GenMsgCycleTime" BO_ 974 100;
BA_ "GenMsgCycleTime" BO_ 951 100;
BA_ "GenMsgCycleTime" BO_ 952 100;
BA_ "GenMsgCycleTime" BO_ 953 100;
BA_ "GenMsgCycleTime" BO_ 941 100;
BA_ "GenMsgCycleTime" BO_ 1156 100;
BA_ "GenMsgCycleTime" BO_ 1018 100;
BA_ "GenMsgSendType" BO_ 169 1;
BA_ "GenMsgCycleTime" BO_ 1176 500;
BA_ "GenMsgCycleTime" BO_ 1141 200;
BA_ "GenMsgCycleTime" BO_ 768 100;
BA_ "GenMsgCycleTime" BO_ 385 20;
BA_ "GenMsgCycleTime" BO_ 754 20;
BA_ "GenMsgCycleTime" BO_ 1015 100;
BA_ "GenMsgCycleTime" BO_ 1154 500;
BA_ "GenMsgCycleTime" BO_ 1169 500;
BA_ "GenMsgCycleTime" BO_ 1170 500;
BA_ "GenMsgCycleTime" BO_ 1171 500;
BA_ "GenMsgCycleTime" BO_ 1172 500;
BA_ "GenMsgCycleTime" BO_ 1173 500;
BA_ "GenMsgCycleTime" BO_ 1174 500;
BA_ "GenMsgCycleTime" BO_ 1520 500;
BA_ "GenMsgCycleTime" BO_ 1186 500;
BA_ "GenMsgCycleTime" BO_ 949 100;
BA_ "GenMsgCycleTime" BO_ 1269 200;
BA_ "GenMsgCycleTime" BO_ 1157 500;
BA_ "GenMsgCycleTime" BO_ 1158 500;
BA_ "GenMsgCycleTime" BO_ 917 100;
BA_ "GenMsgCycleTime" BO_ 965 400;
BA_ "GenMsgCycleTime" BO_ 975 400;
BA_ "GenMsgSendType" BO_ 81 1;
BA_ "GenMsgCycleTime" BO_ 933 400;
BA_ "GenMsgCycleTime" BO_ 485 50;
BA_ "GenMsgSendType" BO_ 1570 1;
BA_ "GenMsgCycleTime" BO_ 862 500;
BA_ "GenMsgSendType" BO_ 1829 1;
BA_ "GenMsgSendType" BO_ 1957 1;
BA_ "GenSigSendType" SG_ 197 ivi_darkIllumiLevelSetReserved 1;
BA_ "GenSigStartValue" SG_ 197 ivi_darkIllumiLevelSetReserved 1;
BA_ "GenSigSendType" SG_ 197 ivi_TripSwitchReserved 1;
BA_ "GenSigSendType" SG_ 197 IVI_RearseatbeltVoiceWarningSet 1;
BA_ "GenSigSendType" SG_ 197 ivi_hudOnOffSet 1;
BA_ "GenSigSendType" SG_ 197 IVI_PEBSVoiceWarningSet 1;
BA_ "GenSigSendType" SG_ 197 ivi_NaviSwitchReserved 1;
BA_ "GenSigSendType" SG_ 197 ivi_themeSetReserved 1;
BA_ "GenSigSendType" SG_ 197 ivi_wcmOnOffSet 1;
BA_ "GenSigSendType" SG_ 197 ivi_pdcOnOffSet 1;
BA_ "GenSigSendType" SG_ 197 ivi_ICthemegangedSetReserved 1;
BA_ "GenSigSendType" SG_ 197 ivi_ICIllumiLevelSet 1;
BA_ "GenSigSendType" SG_ 197 IVI_laeb_SW 1;
BA_ "GenSigSendType" SG_ 197 ivi_IllumiLevelSetReserved 1;
BA_ "GenSigStartValue" SG_ 197 ivi_IllumiLevelSetReserved 1;
BA_ "GenSigSendType" SG_ 198 IVI_VehIntMntnMile 1;
BA_ "GenSigSendType" SG_ 198 IVI_VehMntnMileClea 1;
BA_ "GenSigSendType" SG_ 198 IVI_OilMntnMileClea 1;
BA_ "GenSigSendType" SG_ 198 IVI_OilFilMntnMileClea 1;
BA_ "GenSigSendType" SG_ 198 IVI_AirFilMntnMileClea 1;
BA_ "GenSigSendType" SG_ 198 IVI_VehMntnTimeClea 1;
BA_ "GenSigSendType" SG_ 245 ivi_easyEntrySet 1;
BA_ "GenSigSendType" SG_ 245 ivi_drSeatHeatLevelSet 1;
BA_ "GenSigSendType" SG_ 245 ivi_drSeatVentLevelSet 1;
BA_ "GenSigSendType" SG_ 245 ivi_passSeatHeatLevelSet 1;
BA_ "GenSigSendType" SG_ 245 ivi_passSeatVentLevelSet 1;
BA_ "GenSigSendType" SG_ 245 ivi_drSeatMassLevelSet 1;
BA_ "GenSigSendType" SG_ 245 ivi_passSeatMassLevelSet 1;
BA_ "GenSigSendType" SG_ 245 ivi_MirrorAutoFoldUnfoldSet 1;
BA_ "GenSigSendType" SG_ 245 IVI_RLSeatHeatLevelSet 1;
BA_ "GenSigSendType" SG_ 245 ivi_DrMassgIntenSet 1;
BA_ "GenSigSendType" SG_ 245 ivi_PsgMassgIntenSet 1;
BA_ "GenSigSendType" SG_ 245 IVI_DSMMemoryReq 1;
BA_ "GenSigSendType" SG_ 245 IVI_RRSeatHeatLevelSet 1;
BA_ "GenSigSendType" SG_ 82 ic_engOffTime 1;
BA_ "GenSigSendType" SG_ 82 ic_engOffTimeValid 1;
BA_ "GenSigSendType" SG_ 82 IC_songFaultNum 1;
BA_ "GenSigSendType" SG_ 82 IC_songWarningSts 1;
BA_ "GenSigStartValue" SG_ 1016 IC_driverSeatBeltStatusValid 1;
BA_ "GenSigStartValue" SG_ 1016 IC_passengerSeatBeltStatusValid 1;
BA_ "SystemSignalLongSymbol" SG_ 1268 ic_avgTimeSincethelastchargeTrip "ic_avgTimeSincethelastchargeTripReserved";
BA_ "SystemSignalLongSymbol" SG_ 1268 ic_avgSpdSincethelastchargeTripR "ic_avgSpdSincethelastchargeTripReserved";
BA_ "GenSigStartValue" SG_ 1268 ic_FuelTankResistance 255;
BA_ "GenSigStartValue" SG_ 942 mcur0_iBus 3000;
BA_ "GenSigStartValue" SG_ 958 mcuf0_iBus 3000;
BA_ "GenSigStartValue" SG_ 894 ecu_engCoolantTemp 64;
BA_ "GenSigStartValue" SG_ 547 esc_vehicleSpeed 8190;
BA_ "GenSigStartValue" SG_ 547 esc_avhAvailable 1;
BA_ "GenSigStartValue" SG_ 547 esc_vlcTorqReq 8191;
BA_ "GenSigStartValue" SG_ 547 esc_vlcInterTargetAx 140;
BA_ "GenSigStartValue" SG_ 547 eps_modeStatus 1;
BA_ "GenSigStartValue" SG_ 590 vcu_brakePedalStsValid 1;
BA_ "GenSigStartValue" SG_ 590 vcu_actualGearValid 1;
BA_ "GenSigStartValue" SG_ 974 ac_ambientTemp 80;
BA_ "GenSigStartValue" SG_ 974 ac_cabinTemp 80;
BA_ "GenSigStartValue" SG_ 1018 hud_onOffSts 1;
BA_ "GenSigSendType" SG_ 169 MFW_PRE_Key 1;
BA_ "GenSigSendType" SG_ 169 MFW_NEXT_Key 1;
BA_ "GenSigSendType" SG_ 169 MFW_VolumeUp_Key 1;
BA_ "GenSigSendType" SG_ 169 MFW_VolumeDown_Key 1;
BA_ "GenSigSendType" SG_ 169 MFW_PlayPause_Key 1;
BA_ "GenSigSendType" SG_ 169 MFW_Answer_Key 1;
BA_ "GenSigSendType" SG_ 169 MFW_HangUp_Key 1;
BA_ "GenSigSendType" SG_ 169 MFW_APA_AVM_Key 1;
BA_ "GenSigSendType" SG_ 169 MFW_PageUP_Key 1;
BA_ "GenSigSendType" SG_ 169 MFW_PageDown_Key 1;
BA_ "GenSigSendType" SG_ 169 MFW_Interface_Key 1;
BA_ "GenSigSendType" SG_ 169 MFW_VoiceButton_Key 1;
BA_ "GenSigSendType" SG_ 169 MFW_CustomButton1_Key 1;
BA_ "GenSigSendType" SG_ 169 MFW_ExhibitionMode 1;
BA_ "GenSigSendType" SG_ 169 MFW_TJAICAACTIVEKeySts 1;
BA_ "GenSigSendType" SG_ 169 MFW_TJAICAACTIVEKeyStsValid 1;
BA_ "GenSigSendType" SG_ 169 MFW_IVI_Reset 1;
BA_ "SystemSignalLongSymbol" SG_ 1141 SWHC_SterringWheelHeatFaultReaso "SWHC_SterringWheelHeatFaultReason";
BA_ "GenSigStartValue" SG_ 754 ic_2ndRowLeftSeatBeltStsValid 1;
BA_ "GenSigStartValue" SG_ 754 ic_2ndRowMiddleSeatBeltStsValid 1;
BA_ "GenSigStartValue" SG_ 754 ic_2ndRowRightSeatBeltStsValid 1;
BA_ "GenSigStartValue" SG_ 1169 IC_E_energyconsumption 500;
BA_ "GenSigStartValue" SG_ 1169 IC_E_energyconsumptionA 500;
BA_ "GenSigStartValue" SG_ 1169 IC_E_energyconsumptionB 500;
BA_ "GenSigStartValue" SG_ 1520 cdc_status 15;
BA_ "GenSigStartValue" SG_ 1520 cdc_mcuStatus 15;
BA_ "GenSigStartValue" SG_ 1520 cdc_mcuEnvStatus 15;
BA_ "GenSigStartValue" SG_ 1520 cdc_mcuBatStatus 15;
BA_ "GenSigStartValue" SG_ 1520 cdc_mcuFsmStatus 15;
BA_ "GenSigStartValue" SG_ 1520 cdc_rdcStatus 15;
BA_ "GenSigStartValue" SG_ 1520 cdc_socChipStatus 15;
BA_ "GenSigStartValue" SG_ 1520 cdc_icPowerStatus 15;
BA_ "GenSigStartValue" SG_ 1520 cdc_iviPowerStatus 15;
BA_ "GenSigStartValue" SG_ 1520 cdc_silsStatus 15;
BA_ "GenSigStartValue" SG_ 1520 cdc_icLcdStatus 15;
BA_ "GenSigStartValue" SG_ 1520 cdc_iviLcdStatus 15;
BA_ "GenSigStartValue" SG_ 949 ivi_hvacModeReq 7;
BA_ "GenSigStartValue" SG_ 949 ivi_driverTempCSet 31;
BA_ "GenSigStartValue" SG_ 949 ivi_passengerTempCSet 31;
BA_ "SystemSignalLongSymbol" SG_ 949 ivi_svcSteerInteractionSetReserv "ivi_svcSteerInteractionSetReserved";
BA_ "GenSigStartValue" SG_ 1269 IVI_timeInfoDay 1;
BA_ "GenSigStartValue" SG_ 1269 IVI_timeInfoMonth 1;
BA_ "GenSigStartValue" SG_ 1269 IVI_timeValid 1;
BA_ "GenSigStartValue" SG_ 1269 IVI_longitude 1800;
BA_ "GenSigStartValue" SG_ 1269 IVI_latitude 1800;
BA_ "GenSigSendType" SG_ 81 ECALL_EcallReq 1;
BA_ "GenSigSendType" SG_ 81 ECALL_MUTE 1;
BA_ "GenSigSendType" SG_ 1570 NM_IVI_SourceNodeIdentifier 1;
BA_ "GenSigSendType" SG_ 1570 NM_IVI_RepeatMessageRequestBit 1;
BA_ "GenSigSendType" SG_ 1570 NM_IVI_ActiveWakeup_Bit 1;
BA_ "GenSigSendType" SG_ 1570 NM_IVI_RepeatSts 1;
BA_ "GenSigSendType" SG_ 1570 NMIVI_Active_Source 1;
BA_ "GenSigSendType" SG_ 1829 Diag_PhyReq_IVI_Data 1;
BA_ "GenSigSendType" SG_ 1957 Diag_Resp_IVI_Data 1;
VAL_ 197 ivi_darkIllumiLevelSetReserved 0 "NORequest" 1 "LEVEL1" 2 "LEVEL2" 3 "LEVEL3" 4 "LEVEL4" 5 "LEVEL5" 6 "LEVEL6" 7 "LEVEL7" 8 "LEVEL8" 9 "LEVEL9" 10 "LEVEL10" 11 "LEVEL11" 12 "LEVEL12" 13 "LEVEL13" 14 "LEVEL14" 15 "LEVEL15" 16 "LEVEL16" 17 "LEVEL17" 18 "LEVEL18" 19 "LEVEL19" 20 "LEVEL20" 21 "LEVEL21" 22 "LEVEL22" 23 "LEVEL23" 24 "LEVEL24" 25 "LEVEL25" 26 "LEVEL26" 27 "LEVEL27" 28 "LEVEL28" 29 "LEVEL29" 30 "LEVEL30" 31 " LEVEL31" ;
VAL_ 197 ivi_TripSwitchReserved 0 "NO_REQUEST" 1 "TripA Display" 2 "TripB Display" 3 "Current Trip Display" 4 "Since the last charge Display" 5 "Reserved" 6 "Reserved" 7 "Reserved" ;
VAL_ 197 IVI_RearseatbeltVoiceWarningSet 0 "NORequest" 1 "OFF" 2 "ON" 3 " INVALID" ;
VAL_ 197 ivi_hudOnOffSet 0 "OFF" 1 "ON" 2 "RESERVED" 3 " NO_COMMAND" ;
VAL_ 197 IVI_PEBSVoiceWarningSet 0 "NORequest" 1 "OFF" 2 "ON" 3 " INVALID" ;
VAL_ 197 ivi_NaviSwitchReserved 0 "NORequest" 1 " Navi" ;
VAL_ 197 ivi_themeSetReserved 0 "NONE" 1 "ECO" 2 "COMMON" 3 "SPORT" 4 "DAY" 5 "NIGHT" 6 "RESERVED" 7 " INVALID" ;
VAL_ 197 ivi_wcmOnOffSet 0 "NORequest" 1 "OFF" 2 "ON" 3 " INVALID" ;
VAL_ 197 ivi_pdcOnOffSet 0 "NORequest" 1 "OFF" 2 "ON" 3 " INVALID" ;
VAL_ 197 ivi_ICthemegangedSetReserved 0 "NORequest" 1 "OFF" 2 "ON" 3 " INVALID" ;
VAL_ 197 ivi_ICIllumiLevelSet 0 "NORequest" 1 "LEVEL1" 2 "LEVEL2" 3 "LEVEL3" 4 "LEVEL4" 5 "LEVEL5" 6 "LEVEL6" 7 "LEVEL7" 8 "LEVEL8" 9 "LEVEL9" 10 "LEVEL10" 11 "LEVEL11" 12 "LEVEL12" 13 "LEVEL13" 14 "LEVEL14" 15 "LEVEL15" 16 "LEVEL16" 17 "LEVEL17" 18 "LEVEL18" 19 "LEVEL19" 20 "LEVEL20" 21 "LEVEL21" 22 "LEVEL22" 23 "LEVEL23" 24 "LEVEL24" 25 "LEVEL25" 26 "LEVEL26" 27 "LEVEL27" 28 "LEVEL28" 29 "LEVEL29" 30 "LEVEL30" 31 " LEVEL31" ;
VAL_ 197 IVI_laeb_SW 0 "No Requset" 1 "ON" 2 "OFF" ;
VAL_ 197 ivi_IllumiLevelSetReserved 0 "NORequest" 1 "LEVEL1" 2 "LEVEL2" 3 "LEVEL3" 4 "LEVEL4" 5 "LEVEL5" 6 "LEVEL6" 7 "LEVEL7" 8 "LEVEL8" 9 "LEVEL9" 10 "LEVEL10" 11 "LEVEL11" 12 "LEVEL12" 13 "LEVEL13" 14 "LEVEL14" 15 "LEVEL15" 16 "LEVEL16" 17 "LEVEL17" 18 "LEVEL18" 19 "LEVEL19" 20 "LEVEL20" 21 "LEVEL21" 22 "LEVEL22" 23 "LEVEL23" 24 "LEVEL24" 25 "LEVEL25" 26 "LEVEL26" 27 "LEVEL27" 28 "LEVEL28" 29 "LEVEL29" 30 "LEVEL30" 31 " LEVEL31" ;
VAL_ 198 IVI_VehMntnMileClea 0 "No request" 1 "Request" ;
VAL_ 198 IVI_OilMntnMileClea 0 "No request" 1 "Request" ;
VAL_ 198 IVI_OilFilMntnMileClea 0 "No request" 1 "Request" ;
VAL_ 198 IVI_AirFilMntnMileClea 0 "No request" 1 "Request" ;
VAL_ 198 IVI_VehMntnTimeClea 0 "No request" 1 "Request" ;
VAL_ 978 ivi_AVMCoTouchMotion 0 "RELEASE" 1 " TOUCH_DOWN" ;
VAL_ 978 ivi_IVIthemeSet1 0 "NO_REQUEST" 1 "Day" 2 "Night" 3 " INVALID" ;
VAL_ 978 IVI_TakeINVideoPosReq 0 "NO_REQUEST" 1 " REQUEST" ;
VAL_ 978 IVI_TakePhotoFaultReason 0 "Normal" 1 "超时" 2 "未插USB" 3 "无网" 4 "APA系统故障" 5 "LVDS通信故障" 6 "IVI系统异常" 7 "至0xF Reserved" ;
VAL_ 978 IVI_AlarmListrequest 0 "NO_REQUEST" 1 " REQUEST" ;
VAL_ 978 IVI_driveModeSts 0 "ECO" 1 "COMFORT" 2 "SPORT" 3 "PERSONAL" 4 "RESERVED" ;
VAL_ 978 IVI_PetFaultReason 0 "NORMAL" 1 "POWERFault" 2 "LOWSOC" 3 "BLEInterrupt" 4 "SeatFault" 5 "ConflictOtherScene" 6 "Reserved" ;
VAL_ 245 ivi_easyEntrySet 0 "NORequest" 1 "OFF" 2 "ON" 3 " INVALID" ;
VAL_ 245 ivi_drSeatHeatLevelSet 0 "No req" 1 "LEVEL_1" 2 "LEVEL_2" 3 "LEVEL_3" 4 "OFF" 7 " ERROR" ;
VAL_ 245 ivi_drSeatVentLevelSet 0 "No req" 1 "LEVEL_1" 2 "LEVEL_2" 3 "LEVEL_3" 4 "OFF" 7 " ERROR" ;
VAL_ 245 ivi_passSeatHeatLevelSet 0 "NO_COMMAND" 1 "Level 1" 2 "Level 2" 3 "Level 3" 4 "OFF" 7 " INVALID" ;
VAL_ 245 ivi_passSeatVentLevelSet 0 "No req" 1 "LEVEL_1" 2 "LEVEL_2" 3 "LEVEL_3" 4 "OFF" 7 " ERROR" ;
VAL_ 245 ivi_drSeatMassLevelSet 0 "No req" 1 "LEVEL_1" 2 "LEVEL_2" 3 "LEVEL_3" 4 "LEVEL_4" 5 "LEVEL_5" 6 "RESERVED" 7 " ERROR" ;
VAL_ 245 ivi_passSeatMassLevelSet 0 "No req" 1 "LEVEL_1" 2 "LEVEL_2" 3 "LEVEL_3" 4 "LEVEL_4" 5 "LEVEL_5" 6 "RESERVED" 7 " ERROR" ;
VAL_ 245 ivi_MirrorAutoFoldUnfoldSet 0 "NORequest" 1 "OFF" 2 "ON" 3 " INVALID" ;
VAL_ 245 IVI_RLSeatHeatLevelSet 0 "No req" 1 "LEVEL_1" 2 "LEVEL_2" 3 "LEVEL_3" 4 "OFF" 7 " ERROR" ;
VAL_ 245 ivi_DrMassgIntenSet 0 "NORequest" 1 "Weak Intensity" 2 "Normal Intensity" 3 "High Intensity" 4 "OFF" 5 "Reserved" 7 "Invalid" ;
VAL_ 245 ivi_PsgMassgIntenSet 0 "NORequest" 1 "Weak Intensity" 2 "Normal Intensity" 3 "High Intensity" 4 "OFF" 5 "Reserved" 7 "Invalid" ;
VAL_ 245 IVI_DSMMemoryReq 0 "NO REQUEST" 1 "Memory" 2 "RESERVED" 3 " INVALID" ;
VAL_ 245 IVI_RRSeatHeatLevelSet 0 "No req" 1 "LEVEL_1" 2 "LEVEL_2" 3 "LEVEL_3" 4 "OFF" 7 " ERROR" ;
VAL_ 796 ivi_ElVent1ProgrammingDataSave 0 "PROGRAMMING DATA UNSAVED" 1 "PROGRAMMING DATA SAVED" 2 "RESERVED" 3 "INVALID" ;
VAL_ 796 ivi_ElVent1ObstructionCheck 0 "Obstruction Detectiion closed" 1 "Obstruction Detectiion open" 2 "RESERVED" 3 "INVALID" ;
VAL_ 796 ivi_ElVent1CoilElectrify 0 "coil unergenized" 1 "coil ergenized" 2 "RESERVED" 3 "INVALID" ;
VAL_ 796 ivi_ElVent1LocationSelect 0 "TARGET LOCATION VALID" 1 "ORIGINAL LOCATION VALID" 2 "RESERVED" 3 "INVALID" ;
VAL_ 796 ivi_ElVent1SpeedMode 0 "RESERVED" 1 "SPEED 1" 2 "SPEED 2" 3 "SPEED3" 4 "SPEED4" 5 "AUTO CHANGE SPEED" 15 "INVALID" ;
VAL_ 796 ivi_ElVent1EmergencyStopSwitch 0 "CLOSE EMERGENCY RUNNING" 1 "OPEN EMERGENCY RUNNING" 2 "RESERVED" 3 "INVALID" ;
VAL_ 796 ivi_ElVent1EmergencyStopLocation 0 "BOTTOM BRAKE" 1 "TOP BRAKE" 2 "RESERVED" 3 "INVALID" ;
VAL_ 796 ivi_ElVent1RotationMode 0 "MOVE ON CW DIRECTION" 1 "MOVE ON CCW DIRECTION" 2 "RESERVED" 3 " INVALID" ;
VAL_ 796 ivi_ElVent1StopMode 0 "NORMAL MODE" 1 "STOP MODE" 2 "RESERVED" 3 " INVALID" ;
VAL_ 797 ivi_ElVent2ProgrammingDataSave 0 "PROGRAMMING DATA UNSAVED" 1 "PROGRAMMING DATA SAVED" 2 "RESERVED" 3 "INVALID" ;
VAL_ 797 ivi_ElVent2ObstructionCheck 0 "Obstruction Detectiion closed" 1 "Obstruction Detectiion open" 2 "RESERVED" 3 "INVALID" ;
VAL_ 797 ivi_ElVent2CoilElectrify 0 "coil unergenized" 1 "coil ergenized" 2 "RESERVED" 3 "INVALID" ;
VAL_ 797 ivi_ElVent2LocationSelect 0 "TARGET LOCATION VALID" 1 "ORIGINAL LOCATION VALID" 2 "RESERVED" 3 "INVALID" ;
VAL_ 797 ivi_ElVent2SpeedMode 0 "RESERVED" 1 "SPEED 1" 2 "SPEED 2" 3 "SPEED3" 4 "SPEED4" 5 "AUTO CHANGE SPEED" 15 "INVALID" ;
VAL_ 797 ivi_ElVent2EmergencyStopSwitch 0 "CLOSE EMERGENCY RUNNING" 1 "OPEN EMERGENCY RUNNING" 2 "RESERVED" 3 "INVALID" ;
VAL_ 797 ivi_ElVent2EmergencyStopLocation 0 "BOTTOM BRAKE" 1 "TOP BRAKE" 2 "RESERVED" 3 "INVALID" ;
VAL_ 797 ivi_ElVent2RotationMode 0 "MOVE ON CW DIRECTION" 1 "MOVE ON CCW DIRECTION" 2 "RESERVED" 3 " INVALID" ;
VAL_ 797 ivi_ElVent2StopMode 0 "NORMAL MODE" 1 "STOP MODE" 2 "RESERVED" 3 " INVALID" ;
VAL_ 805 ivi_ElVent3ProgrammingDataSave 0 "PROGRAMMING DATA UNSAVED" 1 "PROGRAMMING DATA SAVED" 2 "RESERVED" 3 "INVALID" ;
VAL_ 805 ivi_ElVent3ObstructionCheck 0 "Obstruction Detectiion closed" 1 "Obstruction Detectiion open" 2 "RESERVED" 3 "INVALID" ;
VAL_ 805 ivi_ElVent3CoilElectrify 0 "coil unergenized" 1 "coil ergenized" 2 "RESERVED" 3 "INVALID" ;
VAL_ 805 ivi_ElVent3LocationSelect 0 "TARGET LOCATION VALID" 1 "ORIGINAL LOCATION VALID" 2 "RESERVED" 3 "INVALID" ;
VAL_ 805 ivi_ElVent3SpeedMode 0 "RESERVED" 1 "SPEED 1" 2 "SPEED 2" 3 "SPEED3" 4 "SPEED4" 5 "AUTO CHANGE SPEED" 15 "INVALID" ;
VAL_ 805 ivi_ElVent3EmergencyStopSwitch 0 "CLOSE EMERGENCY RUNNING" 1 "OPEN EMERGENCY RUNNING" 2 "RESERVED" 3 "INVALID" ;
VAL_ 805 ivi_ElVent3EmergencyStopLocation 0 "BOTTOM BRAKE" 1 "TOP BRAKE" 2 "RESERVED" 3 "INVALID" ;
VAL_ 805 ivi_ElVent3RotationMode 0 "MOVE ON CW DIRECTION" 1 "MOVE ON CCW DIRECTION" 2 "RESERVED" 3 " INVALID" ;
VAL_ 805 ivi_ElVent3StopMode 0 "NORMAL MODE" 1 "STOP MODE" 2 "RESERVED" 3 " INVALID" ;
VAL_ 808 ivi_ElVent4ProgrammingDataSave 0 "PROGRAMMING DATA UNSAVED" 1 "PROGRAMMING DATA SAVED" 2 "RESERVED" 3 "INVALID" ;
VAL_ 808 ivi_ElVent4ObstructionCheck 0 "Obstruction Detectiion closed" 1 "Obstruction Detectiion open" 2 "RESERVED" 3 "INVALID" ;
VAL_ 808 ivi_ElVent4CoilElectrify 0 "coil unergenized" 1 "coil ergenized" 2 "RESERVED" 3 "INVALID" ;
VAL_ 808 ivi_ElVent4LocationSelect 0 "TARGET LOCATION VALID" 1 "ORIGINAL LOCATION VALID" 2 "RESERVED" 3 "INVALID" ;
VAL_ 808 ivi_ElVent4SpeedMode 0 "RESERVED" 1 "SPEED 1" 2 "SPEED 2" 3 "SPEED3" 4 "SPEED4" 5 "AUTO CHANGE SPEED" 15 "INVALID" ;
VAL_ 808 ivi_ElVent4EmergencyStopSwitch 0 "CLOSE EMERGENCY RUNNING" 1 "OPEN EMERGENCY RUNNING" 2 "RESERVED" 3 "INVALID" ;
VAL_ 808 ivi_ElVent4EmergencyStopLocation 0 "BOTTOM BRAKE" 1 "TOP BRAKE" 2 "RESERVED" 3 "INVALID" ;
VAL_ 808 ivi_ElVent4RotationMode 0 "MOVE ON CW DIRECTION" 1 "MOVE ON CCW DIRECTION" 2 "RESERVED" 3 " INVALID" ;
VAL_ 808 ivi_ElVent4StopMode 0 "NORMAL MODE" 1 "STOP MODE" 2 "RESERVED" 3 " INVALID" ;
VAL_ 826 ivi_ElVent5ProgrammingDataSave 0 "PROGRAMMING DATA UNSAVED" 1 "PROGRAMMING DATA SAVED" 2 "RESERVED" 3 "INVALID" ;
VAL_ 826 ivi_ElVent5ObstructionCheck 0 "Obstruction Detectiion closed" 1 "Obstruction Detectiion open" 2 "RESERVED" 3 "INVALID" ;
VAL_ 826 ivi_ElVent5CoilElectrify 0 "coil unergenized" 1 "coil ergenized" 2 "RESERVED" 3 "INVALID" ;
VAL_ 826 ivi_ElVent5LocationSelect 0 "TARGET LOCATION VALID" 1 "ORIGINAL LOCATION VALID" 2 "RESERVED" 3 "INVALID" ;
VAL_ 826 ivi_ElVent5SpeedMode 0 "RESERVED" 1 "SPEED 1" 2 "SPEED 2" 3 "SPEED3" 4 "SPEED4" 5 "AUTO CHANGE SPEED" 15 "INVALID" ;
VAL_ 826 ivi_ElVent5EmergencyStopSwitch 0 "CLOSE EMERGENCY RUNNING" 1 "OPEN EMERGENCY RUNNING" 2 "RESERVED" 3 "INVALID" ;
VAL_ 826 ivi_ElVent5EmergencyStopLocation 0 "BOTTOM BRAKE" 1 "TOP BRAKE" 2 "RESERVED" 3 "INVALID" ;
VAL_ 826 ivi_ElVent5RotationMode 0 "MOVE ON CW DIRECTION" 1 "MOVE ON CCW DIRECTION" 2 "RESERVED" 3 " INVALID" ;
VAL_ 826 ivi_ElVent5StopMode 0 "NORMAL MODE" 1 "STOP MODE" 2 "RESERVED" 3 " INVALID" ;
VAL_ 827 ivi_ElVent6ProgrammingDataSave 0 "PROGRAMMING DATA UNSAVED" 1 "PROGRAMMING DATA SAVED" 2 "RESERVED" 3 "INVALID" ;
VAL_ 827 ivi_ElVent6ObstructionCheck 0 "Obstruction Detectiion closed" 1 "Obstruction Detectiion open" 2 "RESERVED" 3 "INVALID" ;
VAL_ 827 ivi_ElVent6CoilElectrify 0 "coil unergenized" 1 "coil ergenized" 2 "RESERVED" 3 "INVALID" ;
VAL_ 827 ivi_ElVent6LocationSelect 0 "TARGET LOCATION VALID" 1 "ORIGINAL LOCATION VALID" 2 "RESERVED" 3 "INVALID" ;
VAL_ 827 ivi_ElVent6SpeedMode 0 "RESERVED" 1 "SPEED 1" 2 "SPEED 2" 3 "SPEED3" 4 "SPEED4" 5 "AUTO CHANGE SPEED" 15 "INVALID" ;
VAL_ 827 ivi_ElVent6EmergencyStopSwitch 0 "CLOSE EMERGENCY RUNNING" 1 "OPEN EMERGENCY RUNNING" 2 "RESERVED" 3 "INVALID" ;
VAL_ 827 ivi_ElVent6EmergencyStopLocation 0 "BOTTOM BRAKE" 1 "TOP BRAKE" 2 "RESERVED" 3 "INVALID" ;
VAL_ 827 ivi_ElVent6RotationMode 0 "MOVE ON CW DIRECTION" 1 "MOVE ON CCW DIRECTION" 2 "RESERVED" 3 " INVALID" ;
VAL_ 827 ivi_ElVent6StopMode 0 "NORMAL MODE" 1 "STOP MODE" 2 "RESERVED" 3 " INVALID" ;
VAL_ 842 ivi_ElVent7ProgrammingDataSave 0 "PROGRAMMING DATA UNSAVED" 1 "PROGRAMMING DATA SAVED" 2 "RESERVED" 3 "INVALID" ;
VAL_ 842 ivi_ElVent7ObstructionCheck 0 "Obstruction Detectiion closed" 1 "Obstruction Detectiion open" 2 "RESERVED" 3 "INVALID" ;
VAL_ 842 ivi_ElVent7CoilElectrify 0 "coil unergenized" 1 "coil ergenized" 2 "RESERVED" 3 "INVALID" ;
VAL_ 842 ivi_ElVent7LocationSelect 0 "TARGET LOCATION VALID" 1 "ORIGINAL LOCATION VALID" 2 "RESERVED" 3 "INVALID" ;
VAL_ 842 ivi_ElVent7SpeedMode 0 "RESERVED" 1 "SPEED 1" 2 "SPEED 2" 3 "SPEED3" 4 "SPEED4" 5 "AUTO CHANGE SPEED" 15 "INVALID" ;
VAL_ 842 ivi_ElVent7EmergencyStopSwitch 0 "CLOSE EMERGENCY RUNNING" 1 "OPEN EMERGENCY RUNNING" 2 "RESERVED" 3 "INVALID" ;
VAL_ 842 ivi_ElVent7EmergencyStopLocation 0 "BOTTOM BRAKE" 1 "TOP BRAKE" 2 "RESERVED" 3 "INVALID" ;
VAL_ 842 ivi_ElVent7RotationMode 0 "MOVE ON CW DIRECTION" 1 "MOVE ON CCW DIRECTION" 2 "RESERVED" 3 " INVALID" ;
VAL_ 842 ivi_ElVent7StopMode 0 "NORMAL MODE" 1 "STOP MODE" 2 "RESERVED" 3 " INVALID" ;
VAL_ 843 ivi_ElVent8ProgrammingDataSave 0 "PROGRAMMING DATA UNSAVED" 1 "PROGRAMMING DATA SAVED" 2 "RESERVED" 3 "INVALID" ;
VAL_ 843 ivi_ElVent8ObstructionCheck 0 "Obstruction Detectiion closed" 1 "Obstruction Detectiion open" 2 "RESERVED" 3 "INVALID" ;
VAL_ 843 ivi_ElVent8CoilElectrify 0 "coil unergenized" 1 "coil ergenized" 2 "RESERVED" 3 "INVALID" ;
VAL_ 843 ivi_ElVent8LocationSelect 0 "TARGET LOCATION VALID" 1 "ORIGINAL LOCATION VALID" 2 "RESERVED" 3 "INVALID" ;
VAL_ 843 ivi_ElVent8SpeedMode 0 "RESERVED" 1 "SPEED 1" 2 "SPEED 2" 3 "SPEED3" 4 "SPEED4" 5 "AUTO CHANGE SPEED" 15 "INVALID" ;
VAL_ 843 ivi_ElVent8EmergencyStopSwitch 0 "CLOSE EMERGENCY RUNNING" 1 "OPEN EMERGENCY RUNNING" 2 "RESERVED" 3 "INVALID" ;
VAL_ 843 ivi_ElVent8EmergencyStopLocation 0 "BOTTOM BRAKE" 1 "TOP BRAKE" 2 "RESERVED" 3 "INVALID" ;
VAL_ 843 ivi_ElVent8RotationMode 0 "MOVE ON CW DIRECTION" 1 "MOVE ON CCW DIRECTION" 2 "RESERVED" 3 " INVALID" ;
VAL_ 843 ivi_ElVent8StopMode 0 "NORMAL MODE" 1 "STOP MODE" 2 "RESERVED" 3 " INVALID" ;
VAL_ 966 gw_ElVent1ErrorStatus 0 "NO ERROR" 1 " ERROR" ;
VAL_ 966 gw_ElVent1OverHeatStatus 0 "NO OVER HEAT" 1 "OVER HEAT" 2 "RESERVED" 3 " INVALID" ;
VAL_ 966 gw_ElVent1ElectricalFailureSts 0 "NO ERROR" 1 "ELECTRICAL FAILURE EXIST" 2 "PERSISTENT ELECTRICAL FAILURE EXIST" 3 "INVALID" ;
VAL_ 966 gw_ElVent1VoltageStatus 0 "NORMAL VOLTAGE" 1 "LOW VOLTAGE" 2 "OVER VOLTAGE" 3 " INVALID" ;
VAL_ 966 gw_ElVent1EmergencyRunningSts 0 "NO EMERGENCY RUNNING OCCUR" 1 "EMERGENCY RUNNING" 2 "RESERVED" 3 " INVALID" ;
VAL_ 966 gw_ElVent1ObstructionDetect 0 "Obstruction Detection Closed" 1 "Obstruction Detection Open" 2 "RESERVED" 3 " INVALID" ;
VAL_ 966 gw_ElVent1ObstructionStatus 0 "NO OBSTRUCTION" 1 "OBSTRUCTION DETECTED" 2 "RESERVED" 3 " INVALID" ;
VAL_ 966 gw_ElVent1ResetStatus 0 "NO RESET" 1 "RESET" 2 "RESERVED" 3 " INVALID" ;
VAL_ 966 gw_ElVent1CoilStatus 0 "coil unergenized" 1 "coil ergenized" 2 "RESERVED" 3 " INVALID" ;
VAL_ 966 gw_ElVent1LocationStatus 0 "TARGET LOCATION VALID" 1 "ORIGINAL LOCATION VALID" 2 "NO DEFAULT SIGNIFICANT BIT" 3 " INVALID" ;
VAL_ 966 gw_ElVent1SpeedStatus 0 "RESERVED" 1 "SPEED 1" 2 "SPEED 2" 3 "SPEED3" 4 "SPEED4" 5 "AUTO CHANGE SPEED" 15 "INVALID" ;
VAL_ 966 gw_ElVent1MotorDrivingDirection 0 "SMALL PROCESS LOCATION" 1 "LARGE PROCESS LOCATION" 2 "INITIALIZATION" 3 " INVALID" ;
VAL_ 966 gw_ElVent1TorqueKeepingSts 0 "NO SELF SUSTAINING TURQUE" 1 "SELF SUSTAINING TURQUE" 2 "RESERVED" 3 " INVALID" ;
VAL_ 966 gw_ElVent1SpecialFunction 0 "NO SPECIAL FUNCTION" 1 "SPECIAL FUNCTION" 2 "RESERVED" 3 " INVALID" ;
VAL_ 966 gw_ElVent1EmgyStopSwitchSts 0 "STOP EMERGENCY RUNNING" 1 "OPEN EMERGENCY RUNNING" 2 "RESERVED" 3 " INVALID" ;
VAL_ 966 gw_ElVent1EmgyStopSLocation 0 "BOTTOM BRAKE" 1 "TOP BRAKE" 2 "RESERVED" 3 "INVALID" ;
VAL_ 966 gw_ElVent1RotationMode 0 "MOVE ON CW DIRECTION" 1 "MOVE ON CCW DIRECTION" 2 "RESERVED" 3 " INVALID" ;
VAL_ 966 gw_ElVent1StopStatus 0 "NORMAL MODE" 1 "STOP MODE" 2 "RESERVED" 3 " INVALID" ;
VAL_ 967 gw_ElVent2ErrorStatus 0 "NO ERROR" 1 " ERROR" ;
VAL_ 967 gw_ElVent2OverHeatStatus 0 "NO OVER HEAT" 1 "OVER HEAT" 2 "RESERVED" 3 " INVALID" ;
VAL_ 967 gw_ElVent2ElectricalFailureSts 0 "NO ERROR" 1 "ELECTRICAL FAILURE EXIST" 2 "PERSISTENT ELECTRICAL FAILURE EXIST" 3 "INVALID" ;
VAL_ 967 gw_ElVent2VoltageStatus 0 "NORMAL VOLTAGE" 1 "LOW VOLTAGE" 2 "OVER VOLTAGE" 3 " INVALID" ;
VAL_ 967 gw_ElVent2EmergencyRunningSts 0 "NO EMERGENCY RUNNING OCCUR" 1 "EMERGENCY RUNNING" 2 "RESERVED" 3 " INVALID" ;
VAL_ 967 gw_ElVent2ObstructionDetect 0 "Obstruction Detection Closed" 1 "Obstruction Detection Open" 2 "RESERVED" 3 " INVALID" ;
VAL_ 967 gw_ElVent2ObstructionStatus 0 "NO OBSTRUCTION" 1 "OBSTRUCTION DETECTED" 2 "RESERVED" 3 " INVALID" ;
VAL_ 967 gw_ElVent2ResetStatus 0 "NO RESET" 1 "RESET" 2 "RESERVED" 3 " INVALID" ;
VAL_ 967 gw_ElVent2CoilStatus 0 "coil unergenized" 1 "coil ergenized" 2 "RESERVED" 3 " INVALID" ;
VAL_ 967 gw_ElVent2LocationStatus 0 "TARGET LOCATION VALID" 1 "ORIGINAL LOCATION VALID" 2 "NO DEFAULT SIGNIFICANT BIT" 3 " INVALID" ;
VAL_ 967 gw_ElVent2SpeedStatus 0 "RESERVED" 1 "SPEED 1" 2 "SPEED 2" 3 "SPEED3" 4 "SPEED4" 5 "AUTO CHANGE SPEED" 15 "INVALID" ;
VAL_ 967 gw_ElVent2MotorDrivingDirection 0 "SMALL PROCESS LOCATION" 1 "LARGE PROCESS LOCATION" 2 "INITIALIZATION" 3 " INVALID" ;
VAL_ 967 gw_ElVent2TorqueKeepingSts 0 "NO SELF SUSTAINING TURQUE" 1 "SELF SUSTAINING TURQUE" 2 "RESERVED" 3 " INVALID" ;
VAL_ 967 gw_ElVent2SpecialFunction 0 "NO SPECIAL FUNCTION" 1 "SPECIAL FUNCTION" 2 "RESERVED" 3 " INVALID" ;
VAL_ 967 gw_ElVent2EmgyStopSwitchSts 0 "STOP EMERGENCY RUNNING" 1 "OPEN EMERGENCY RUNNING" 2 "RESERVED" 3 " INVALID" ;
VAL_ 967 gw_ElVent2EmgyStopSLocation 0 "BOTTOM BRAKE" 1 "TOP BRAKE" 2 "RESERVED" 3 "INVALID" ;
VAL_ 967 gw_ElVent2RotationMode 0 "MOVE ON CW DIRECTION" 1 "MOVE ON CCW DIRECTION" 2 "RESERVED" 3 " INVALID" ;
VAL_ 967 gw_ElVent2StopStatus 0 "NORMAL MODE" 1 "STOP MODE" 2 "RESERVED" 3 " INVALID" ;
VAL_ 968 gw_ElVent3ErrorStatus 0 "NO ERROR" 1 " ERROR" ;
VAL_ 968 gw_ElVent3OverHeatStatus 0 "NO OVER HEAT" 1 "OVER HEAT" 2 "RESERVED" 3 " INVALID" ;
VAL_ 968 gw_ElVent3ElectricalFailureSts 0 "NO ERROR" 1 "ELECTRICAL FAILURE EXIST" 2 "PERSISTENT ELECTRICAL FAILURE EXIST" 3 "INVALID" ;
VAL_ 968 gw_ElVent3VoltageStatus 0 "NORMAL VOLTAGE" 1 "LOW VOLTAGE" 2 "OVER VOLTAGE" 3 " INVALID" ;
VAL_ 968 gw_ElVent3EmergencyRunningSts 0 "NO EMERGENCY RUNNING OCCUR" 1 "EMERGENCY RUNNING" 2 "RESERVED" 3 " INVALID" ;
VAL_ 968 gw_ElVent3ObstructionDetect 0 "Obstruction Detection Closed" 1 "Obstruction Detection Open" 2 "RESERVED" 3 " INVALID" ;
VAL_ 968 gw_ElVent3ObstructionStatus 0 "NO OBSTRUCTION" 1 "OBSTRUCTION DETECTED" 2 "RESERVED" 3 " INVALID" ;
VAL_ 968 gw_ElVent3ResetStatus 0 "NO RESET" 1 "RESET" 2 "RESERVED" 3 " INVALID" ;
VAL_ 968 gw_ElVent3CoilStatus 0 "coil unergenized" 1 "coil ergenized" 2 "RESERVED" 3 " INVALID" ;
VAL_ 968 gw_ElVent3LocationStatus 0 "TARGET LOCATION VALID" 1 "ORIGINAL LOCATION VALID" 2 "NO DEFAULT SIGNIFICANT BIT" 3 " INVALID" ;
VAL_ 968 gw_ElVent3SpeedStatus 0 "RESERVED" 1 "SPEED 1" 2 "SPEED 2" 3 "SPEED3" 4 "SPEED4" 5 "AUTO CHANGE SPEED" 15 "INVALID" ;
VAL_ 968 gw_ElVent3MotorDrivingDirection 0 "SMALL PROCESS LOCATION" 1 "LARGE PROCESS LOCATION" 2 "INITIALIZATION" 3 " INVALID" ;
VAL_ 968 gw_ElVent3TorqueKeepingSts 0 "NO SELF SUSTAINING TURQUE" 1 "SELF SUSTAINING TURQUE" 2 "RESERVED" 3 " INVALID" ;
VAL_ 968 gw_ElVent3SpecialFunction 0 "NO SPECIAL FUNCTION" 1 "SPECIAL FUNCTION" 2 "RESERVED" 3 " INVALID" ;
VAL_ 968 gw_ElVent3EmgyStopSwitchSts 0 "STOP EMERGENCY RUNNING" 1 "OPEN EMERGENCY RUNNING" 2 "RESERVED" 3 " INVALID" ;
VAL_ 968 gw_ElVent3EmgyStopSLocation 0 "BOTTOM BRAKE" 1 "TOP BRAKE" 2 "RESERVED" 3 "INVALID" ;
VAL_ 968 gw_ElVent3RotationMode 0 "MOVE ON CW DIRECTION" 1 "MOVE ON CCW DIRECTION" 2 "RESERVED" 3 " INVALID" ;
VAL_ 968 gw_ElVent3StopStatus 0 "NORMAL MODE" 1 "STOP MODE" 2 "RESERVED" 3 " INVALID" ;
VAL_ 969 gw_ElVent4ErrorStatus 0 "NO ERROR" 1 " ERROR" ;
VAL_ 969 gw_ElVent4OverHeatStatus 0 "NO OVER HEAT" 1 "OVER HEAT" 2 "RESERVED" 3 " INVALID" ;
VAL_ 969 gw_ElVent4ElectricalFailureSts 0 "NO ERROR" 1 "ELECTRICAL FAILURE EXIST" 2 "PERSISTENT ELECTRICAL FAILURE EXIST" 3 "INVALID" ;
VAL_ 969 gw_ElVent4VoltageStatus 0 "NORMAL VOLTAGE" 1 "LOW VOLTAGE" 2 "OVER VOLTAGE" 3 " INVALID" ;
VAL_ 969 gw_ElVent4EmergencyRunningSts 0 "NO EMERGENCY RUNNING OCCUR" 1 "EMERGENCY RUNNING" 2 "RESERVED" 3 " INVALID" ;
VAL_ 969 gw_ElVent4ObstructionDetect 0 "Obstruction Detection Closed" 1 "Obstruction Detection Open" 2 "RESERVED" 3 " INVALID" ;
VAL_ 969 gw_ElVent4ObstructionStatus 0 "NO OBSTRUCTION" 1 "OBSTRUCTION DETECTED" 2 "RESERVED" 3 " INVALID" ;
VAL_ 969 gw_ElVent4ResetStatus 0 "NO RESET" 1 "RESET" 2 "RESERVED" 3 " INVALID" ;
VAL_ 969 gw_ElVent4CoilStatus 0 "coil unergenized" 1 "coil ergenized" 2 "RESERVED" 3 " INVALID" ;
VAL_ 969 gw_ElVent4LocationStatus 0 "TARGET LOCATION VALID" 1 "ORIGINAL LOCATION VALID" 2 "NO DEFAULT SIGNIFICANT BIT" 3 " INVALID" ;
VAL_ 969 gw_ElVent4SpeedStatus 0 "RESERVED" 1 "SPEED 1" 2 "SPEED 2" 3 "SPEED3" 4 "SPEED4" 5 "AUTO CHANGE SPEED" 15 "INVALID" ;
VAL_ 969 gw_ElVent4MotorDrivingDirection 0 "SMALL PROCESS LOCATION" 1 "LARGE PROCESS LOCATION" 2 "INITIALIZATION" 3 " INVALID" ;
VAL_ 969 gw_ElVent4TorqueKeepingSts 0 "NO SELF SUSTAINING TURQUE" 1 "SELF SUSTAINING TURQUE" 2 "RESERVED" 3 " INVALID" ;
VAL_ 969 gw_ElVent4SpecialFunction 0 "NO SPECIAL FUNCTION" 1 "SPECIAL FUNCTION" 2 "RESERVED" 3 " INVALID" ;
VAL_ 969 gw_ElVent4EmgyStopSwitchSts 0 "STOP EMERGENCY RUNNING" 1 "OPEN EMERGENCY RUNNING" 2 "RESERVED" 3 " INVALID" ;
VAL_ 969 gw_ElVent4EmgyStopSLocation 0 "BOTTOM BRAKE" 1 "TOP BRAKE" 2 "RESERVED" 3 "INVALID" ;
VAL_ 969 gw_ElVent4RotationMode 0 "MOVE ON CW DIRECTION" 1 "MOVE ON CCW DIRECTION" 2 "RESERVED" 3 " INVALID" ;
VAL_ 969 gw_ElVent4StopStatus 0 "NORMAL MODE" 1 "STOP MODE" 2 "RESERVED" 3 " INVALID" ;
VAL_ 970 gw_ElVent5ErrorStatus 0 "NO ERROR" 1 " ERROR" ;
VAL_ 970 gw_ElVent5OverHeatStatus 0 "NO OVER HEAT" 1 "OVER HEAT" 2 "RESERVED" 3 " INVALID" ;
VAL_ 970 gw_ElVent5ElectricalFailureSts 0 "NO ERROR" 1 "ELECTRICAL FAILURE EXIST" 2 "PERSISTENT ELECTRICAL FAILURE EXIST" 3 "INVALID" ;
VAL_ 970 gw_ElVent5VoltageStatus 0 "NORMAL VOLTAGE" 1 "LOW VOLTAGE" 2 "OVER VOLTAGE" 3 " INVALID" ;
VAL_ 970 gw_ElVent5EmergencyRunningSts 0 "NO EMERGENCY RUNNING OCCUR" 1 "EMERGENCY RUNNING" 2 "RESERVED" 3 " INVALID" ;
VAL_ 970 gw_ElVent5ObstructionDetect 0 "Obstruction Detection Closed" 1 "Obstruction Detection Open" 2 "RESERVED" 3 " INVALID" ;
VAL_ 970 gw_ElVent5ObstructionStatus 0 "NO OBSTRUCTION" 1 "OBSTRUCTION DETECTED" 2 "RESERVED" 3 " INVALID" ;
VAL_ 970 gw_ElVent5ResetStatus 0 "NO RESET" 1 "RESET" 2 "RESERVED" 3 " INVALID" ;
VAL_ 970 gw_ElVent5CoilStatus 0 "coil unergenized" 1 "coil ergenized" 2 "RESERVED" 3 " INVALID" ;
VAL_ 970 gw_ElVent5LocationStatus 0 "TARGET LOCATION VALID" 1 "ORIGINAL LOCATION VALID" 2 "NO DEFAULT SIGNIFICANT BIT" 3 " INVALID" ;
VAL_ 970 gw_ElVent5SpeedStatus 0 "RESERVED" 1 "SPEED 1" 2 "SPEED 2" 3 "SPEED3" 4 "SPEED4" 5 "AUTO CHANGE SPEED" 15 "INVALID" ;
VAL_ 970 gw_ElVent5MotorDrivingDirection 0 "SMALL PROCESS LOCATION" 1 "LARGE PROCESS LOCATION" 2 "INITIALIZATION" 3 " INVALID" ;
VAL_ 970 gw_ElVent5TorqueKeepingSts 0 "NO SELF SUSTAINING TURQUE" 1 "SELF SUSTAINING TURQUE" 2 "RESERVED" 3 " INVALID" ;
VAL_ 970 gw_ElVent5SpecialFunction 0 "NO SPECIAL FUNCTION" 1 "SPECIAL FUNCTION" 2 "RESERVED" 3 " INVALID" ;
VAL_ 970 gw_ElVent5EmgyStopSwitchSts 0 "STOP EMERGENCY RUNNING" 1 "OPEN EMERGENCY RUNNING" 2 "RESERVED" 3 " INVALID" ;
VAL_ 970 gw_ElVent5EmgyStopSLocation 0 "BOTTOM BRAKE" 1 "TOP BRAKE" 2 "RESERVED" 3 "INVALID" ;
VAL_ 970 gw_ElVent5RotationMode 0 "MOVE ON CW DIRECTION" 1 "MOVE ON CCW DIRECTION" 2 "RESERVED" 3 " INVALID" ;
VAL_ 970 gw_ElVent5StopStatus 0 "NORMAL MODE" 1 "STOP MODE" 2 "RESERVED" 3 " INVALID" ;
VAL_ 971 gw_ElVent6ErrorStatus 0 "NO ERROR" 1 " ERROR" ;
VAL_ 971 gw_ElVent6OverHeatStatus 0 "NO OVER HEAT" 1 "OVER HEAT" 2 "RESERVED" 3 " INVALID" ;
VAL_ 971 gw_ElVent6ElectricalFailureSts 0 "NO ERROR" 1 "ELECTRICAL FAILURE EXIST" 2 "PERSISTENT ELECTRICAL FAILURE EXIST" 3 "INVALID" ;
VAL_ 971 gw_ElVent6VoltageStatus 0 "NORMAL VOLTAGE" 1 "LOW VOLTAGE" 2 "OVER VOLTAGE" 3 " INVALID" ;
VAL_ 971 gw_ElVent6EmergencyRunningSts 0 "NO EMERGENCY RUNNING OCCUR" 1 "EMERGENCY RUNNING" 2 "RESERVED" 3 " INVALID" ;
VAL_ 971 gw_ElVent6ObstructionDetect 0 "Obstruction Detection Closed" 1 "Obstruction Detection Open" 2 "RESERVED" 3 " INVALID" ;
VAL_ 971 gw_ElVent6ObstructionStatus 0 "NO OBSTRUCTION" 1 "OBSTRUCTION DETECTED" 2 "RESERVED" 3 " INVALID" ;
VAL_ 971 gw_ElVent6ResetStatus 0 "NO RESET" 1 "RESET" 2 "RESERVED" 3 " INVALID" ;
VAL_ 971 gw_ElVent6CoilStatus 0 "coil unergenized" 1 "coil ergenized" 2 "RESERVED" 3 " INVALID" ;
VAL_ 971 gw_ElVent6LocationStatus 0 "TARGET LOCATION VALID" 1 "ORIGINAL LOCATION VALID" 2 "NO DEFAULT SIGNIFICANT BIT" 3 " INVALID" ;
VAL_ 971 gw_ElVent6SpeedStatus 0 "RESERVED" 1 "SPEED 1" 2 "SPEED 2" 3 "SPEED3" 4 "SPEED4" 5 "AUTO CHANGE SPEED" 15 "INVALID" ;
VAL_ 971 gw_ElVent6MotorDrivingDirection 0 "SMALL PROCESS LOCATION" 1 "LARGE PROCESS LOCATION" 2 "INITIALIZATION" 3 " INVALID" ;
VAL_ 971 gw_ElVent6TorqueKeepingSts 0 "NO SELF SUSTAINING TURQUE" 1 "SELF SUSTAINING TURQUE" 2 "RESERVED" 3 " INVALID" ;
VAL_ 971 gw_ElVent6SpecialFunction 0 "NO SPECIAL FUNCTION" 1 "SPECIAL FUNCTION" 2 "RESERVED" 3 " INVALID" ;
VAL_ 971 gw_ElVent6EmgyStopSwitchSts 0 "STOP EMERGENCY RUNNING" 1 "OPEN EMERGENCY RUNNING" 2 "RESERVED" 3 " INVALID" ;
VAL_ 971 gw_ElVent6EmgyStopSLocation 0 "BOTTOM BRAKE" 1 "TOP BRAKE" 2 "RESERVED" 3 "INVALID" ;
VAL_ 971 gw_ElVent6RotationMode 0 "MOVE ON CW DIRECTION" 1 "MOVE ON CCW DIRECTION" 2 "RESERVED" 3 " INVALID" ;
VAL_ 971 gw_ElVent6StopStatus 0 "NORMAL MODE" 1 "STOP MODE" 2 "RESERVED" 3 " INVALID" ;
VAL_ 972 gw_ElVent7ErrorStatus 0 "NO ERROR" 1 " ERROR" ;
VAL_ 972 gw_ElVent7OverHeatStatus 0 "NO OVER HEAT" 1 "OVER HEAT" 2 "RESERVED" 3 " INVALID" ;
VAL_ 972 gw_ElVent7ElectricalFailureSts 0 "NO ERROR" 1 "ELECTRICAL FAILURE EXIST" 2 "PERSISTENT ELECTRICAL FAILURE EXIST" 3 "INVALID" ;
VAL_ 972 gw_ElVent7VoltageStatus 0 "NORMAL VOLTAGE" 1 "LOW VOLTAGE" 2 "OVER VOLTAGE" 3 " INVALID" ;
VAL_ 972 gw_ElVent7EmergencyRunningSts 0 "NO EMERGENCY RUNNING OCCUR" 1 "EMERGENCY RUNNING" 2 "RESERVED" 3 " INVALID" ;
VAL_ 972 gw_ElVent7ObstructionDetect 0 "Obstruction Detection Closed" 1 "Obstruction Detection Open" 2 "RESERVED" 3 " INVALID" ;
VAL_ 972 gw_ElVent7ObstructionStatus 0 "NO OBSTRUCTION" 1 "OBSTRUCTION DETECTED" 2 "RESERVED" 3 " INVALID" ;
VAL_ 972 gw_ElVent7ResetStatus 0 "NO RESET" 1 "RESET" 2 "RESERVED" 3 " INVALID" ;
VAL_ 972 gw_ElVent7CoilStatus 0 "coil unergenized" 1 "coil ergenized" 2 "RESERVED" 3 " INVALID" ;
VAL_ 972 gw_ElVent7LocationStatus 0 "TARGET LOCATION VALID" 1 "ORIGINAL LOCATION VALID" 2 "NO DEFAULT SIGNIFICANT BIT" 3 " INVALID" ;
VAL_ 972 gw_ElVent7SpeedStatus 0 "RESERVED" 1 "SPEED 1" 2 "SPEED 2" 3 "SPEED3" 4 "SPEED4" 5 "AUTO CHANGE SPEED" 15 "INVALID" ;
VAL_ 972 gw_ElVent7MotorDrivingDirection 0 "SMALL PROCESS LOCATION" 1 "LARGE PROCESS LOCATION" 2 "INITIALIZATION" 3 " INVALID" ;
VAL_ 972 gw_ElVent7TorqueKeepingSts 0 "NO SELF SUSTAINING TURQUE" 1 "SELF SUSTAINING TURQUE" 2 "RESERVED" 3 " INVALID" ;
VAL_ 972 gw_ElVent7SpecialFunction 0 "NO SPECIAL FUNCTION" 1 "SPECIAL FUNCTION" 2 "RESERVED" 3 " INVALID" ;
VAL_ 972 gw_ElVent7EmgyStopSwitchSts 0 "STOP EMERGENCY RUNNING" 1 "OPEN EMERGENCY RUNNING" 2 "RESERVED" 3 " INVALID" ;
VAL_ 972 gw_ElVent7EmgyStopSLocation 0 "BOTTOM BRAKE" 1 "TOP BRAKE" 2 "RESERVED" 3 "INVALID" ;
VAL_ 972 gw_ElVent7RotationMode 0 "MOVE ON CW DIRECTION" 1 "MOVE ON CCW DIRECTION" 2 "RESERVED" 3 " INVALID" ;
VAL_ 972 gw_ElVent7StopStatus 0 "NORMAL MODE" 1 "STOP MODE" 2 "RESERVED" 3 " INVALID" ;
VAL_ 973 gw_ElVent8ErrorStatus 0 "NO ERROR" 1 " ERROR" ;
VAL_ 973 gw_ElVent8OverHeatStatus 0 "NO OVER HEAT" 1 "OVER HEAT" 2 "RESERVED" 3 " INVALID" ;
VAL_ 973 gw_ElVent8ElectricalFailureSts 0 "NO ERROR" 1 "ELECTRICAL FAILURE EXIST" 2 "PERSISTENT ELECTRICAL FAILURE EXIST" 3 "INVALID" ;
VAL_ 973 gw_ElVent8VoltageStatus 0 "NORMAL VOLTAGE" 1 "LOW VOLTAGE" 2 "OVER VOLTAGE" 3 " INVALID" ;
VAL_ 973 gw_ElVent8EmergencyRunningSts 0 "NO EMERGENCY RUNNING OCCUR" 1 "EMERGENCY RUNNING" 2 "RESERVED" 3 " INVALID" ;
VAL_ 973 gw_ElVent8ObstructionDetect 0 "Obstruction Detection Closed" 1 "Obstruction Detection Open" 2 "RESERVED" 3 " INVALID" ;
VAL_ 973 gw_ElVent8ObstructionStatus 0 "NO OBSTRUCTION" 1 "OBSTRUCTION DETECTED" 2 "RESERVED" 3 " INVALID" ;
VAL_ 973 gw_ElVent8ResetStatus 0 "NO RESET" 1 "RESET" 2 "RESERVED" 3 " INVALID" ;
VAL_ 973 gw_ElVent8CoilStatus 0 "coil unergenized" 1 "coil ergenized" 2 "RESERVED" 3 " INVALID" ;
VAL_ 973 gw_ElVent8LocationStatus 0 "TARGET LOCATION VALID" 1 "ORIGINAL LOCATION VALID" 2 "NO DEFAULT SIGNIFICANT BIT" 3 " INVALID" ;
VAL_ 973 gw_ElVent8SpeedStatus 0 "RESERVED" 1 "SPEED 1" 2 "SPEED 2" 3 "SPEED3" 4 "SPEED4" 5 "AUTO CHANGE SPEED" 15 "INVALID" ;
VAL_ 973 gw_ElVent8MotorDrivingDirection 0 "SMALL PROCESS LOCATION" 1 "LARGE PROCESS LOCATION" 2 "INITIALIZATION" 3 " INVALID" ;
VAL_ 973 gw_ElVent8TorqueKeepingSts 0 "NO SELF SUSTAINING TURQUE" 1 "SELF SUSTAINING TURQUE" 2 "RESERVED" 3 " INVALID" ;
VAL_ 973 gw_ElVent8SpecialFunction 0 "NO SPECIAL FUNCTION" 1 "SPECIAL FUNCTION" 2 "RESERVED" 3 " INVALID" ;
VAL_ 973 gw_ElVent8EmgyStopSwitchSts 0 "STOP EMERGENCY RUNNING" 1 "OPEN EMERGENCY RUNNING" 2 "RESERVED" 3 " INVALID" ;
VAL_ 973 gw_ElVent8EmgyStopSLocation 0 "BOTTOM BRAKE" 1 "TOP BRAKE" 2 "RESERVED" 3 "INVALID" ;
VAL_ 973 gw_ElVent8RotationMode 0 "MOVE ON CW DIRECTION" 1 "MOVE ON CCW DIRECTION" 2 "RESERVED" 3 " INVALID" ;
VAL_ 973 gw_ElVent8StopStatus 0 "NORMAL MODE" 1 "STOP MODE" 2 "RESERVED" 3 " INVALID" ;
VAL_ 897 VAP_FragranceWorkingSts 0 "Standby" 1 "Running" ;
VAL_ 897 VAP_FragranceConcentration 0 "Initial value" 1 "Low concentration" 2 "Middle concentration" 3 "High concentration" 4 "Reserved (预留）" 5 "Reserved (预留）" 6 "Reserved (预留）" 7 "Reserved (预留）" 8 "Reserved (预留）" 9 "Reserved (预留）" 10 "Reserved (预留）" 11 "Reserved (预留）" 12 "Reserved (预留）" 13 "Reserved (预留）" 14 "Reserved (预留）" 15 "Reserved (预留）" ;
VAL_ 897 VAP_FragranceType_Position_1 0 "No Type (无香型)" 1 "Type_1 (远行)" 2 "Type_2 (和畅似风）" 3 "Type_3 (雨后花园）" 4 "Type_4 (清雅若林）" 5 "Type_5 (沉静如珀）" 6 "Type_6 (白色广藿香）" 7 "Type_7 (保加利亚玫瑰）" 8 "Type_8 (天竺葵先生）" 9 "Type_9 (绚丽栀子花）" 10 "Type_10 (五时姜香）" 11 "Reserved (预留）" 12 "Reserved (预留）" 13 "Reserved (预留）" 14 "Reserved (预留）" 15 "Reserved (预留）" ;
VAL_ 897 VAP_FragranceType_Position_2 0 "No Type (无香型)" 1 "Type_1 (远行)" 2 "Type_2 (和畅似风）" 3 "Type_3 (雨后花园）" 4 "Type_4 (清雅若林）" 5 "Type_5 (沉静如珀）" 6 "Type_6 (白色广藿香）" 7 "Type_7 (保加利亚玫瑰）" 8 "Type_8 (天竺葵先生）" 9 "Type_9 (绚丽栀子花）" 10 "Type_10 (五时姜香）" 11 "Reserved (预留）" 12 "Reserved (预留）" 13 "Reserved (预留）" 14 "Reserved (预留）" 15 "Reserved (预留）" ;
VAL_ 897 VAP_FragranceType_Position_3 0 "No Type (无香型)" 1 "Type_1 (远行)" 2 "Type_2 (和畅似风）" 3 "Type_3 (雨后花园）" 4 "Type_4 (清雅若林）" 5 "Type_5 (沉静如珀）" 6 "Type_6 (白色广藿香）" 7 "Type_7 (保加利亚玫瑰）" 8 "Type_8 (天竺葵先生）" 9 "Type_9 (绚丽栀子花）" 10 "Type_10 (五时姜香）" 11 "Reserved (预留）" 12 "Reserved (预留）" 13 "Reserved (预留）" 14 "Reserved (预留）" 15 "Reserved (预留）" ;
VAL_ 897 VAP_FragrancePositionSts 0 "Initial value" 1 "Fragrance Position_1 (位置1的香型)" 2 "Fragrance Position_2 (位置2的香型）" 3 "Fragrance Position_3 (位置3的香型）" 4 "Reserved (预留）" 5 "Reserved (预留）" 6 "Reserved (预留）" 7 "Reserved (预留）" 8 "Reserved (预留）" 9 "Reserved (预留）" 10 "Reserved (预留）" 11 "Reserved (预留）" 12 "Reserved (预留）" 13 "Reserved (预留）" 14 "Reserved (预留）" 15 "Reserved (预留） " ;
VAL_ 897 VAP_OverVoltageFault 0 "Normal" 1 "Fault" ;
VAL_ 897 VAP_LowVoltageFault 0 "Normal" 1 "Fault" ;
VAL_ 897 VAP_BusoffFault 0 "Normal" 1 "Fault" ;
VAL_ 897 VAP_hardwareFault 0 "Normal" 1 "Fault" ;
VAL_ 897 VAP_softwareFault 0 "Normal" 1 "Fault" ;
VAL_ 897 VAP_RFIDCRCCheckFault 0 "Normal" 1 "Fault" ;
VAL_ 897 VAP_Motor_Fault 0 "Normal" 1 "Fault" ;
VAL_ 897 VAP_FAN_Fault 0 "Normal" 1 "Fault" ;
VAL_ 82 ic_engOffTimeValid 0 "INVALID" 1 " VALID" ;
VAL_ 82 IC_songFaultNum 0 "NO REQUEST" 1 "SOUND1" 2 "SOUND2" 3 "SOUND3" 4 "SOUND4" 5 "SOUND5" 6 "SOUND6" 7 "SOUND7" 8 "SOUND8" 9 "SOUND9" 10 "SOUND10" 11 "SOUND11" 12 "SOUND12" 13 "SOUND13" 14 "SOUND14" 15 "SOUND15" 16 "SOUND16" 17 "SOUND17" 18 "SOUND18" 19 "SOUND19" 20 "SOUND20" 21 "SOUND21" 22 "SOUND22" 23 "SOUND23" 24 "SOUND24" 25 "SOUND25" 26 "SOUND26" 27 "SOUND27" 28 "SOUND28" 29 "SOUND29" 30 "SOUND30" 31 "至0x3E reserved" 63 "INVALID" ;
VAL_ 82 IC_songWarningSts 0 "NO REQUEST" 1 "报警" 2 "取消报警" 3 " 预留" ;
VAL_ 1533 IC_LowBatteryvoltage 0 "NO Warning" 1 " Warning" ;
VAL_ 1533 IC_engCoolantTempAlarm 0 "NO Warning" 1 " Warning" ;
VAL_ 1533 IC_lowfuleAlarm 0 "NO Warning" 1 " Warning" ;
VAL_ 1533 IC_lowbrakefluidlevel 0 "NO Warning" 1 " Warning" ;
VAL_ 1533 IC_lowoilpressure 0 "NO Warning" 1 " Warning" ;
VAL_ 1010 ic_hudScreenTransition 0 "SPEED" 1 "PERFORMANCE" 2 "MULTIMEDIA" 3 " NAVI" ;
VAL_ 1010 ic_hudHeightSet 0 "-14" 1 "-13" 2 "-12" 3 "-11" 4 "-10" 5 "-9" 6 "-8" 7 "-7" 8 "-6" 9 "-5" 10 "-4" 11 "-3" 12 "-2" 13 "-1" 14 "±0" 15 "+1" 16 "+2" 17 "+3" 18 "+4" 19 "+5" 20 "+6" 21 "+7" 22 "+8" 23 "+9" 24 "+10" 25 "+11" 26 "+12" 27 "+13" 28 "+14" 29 " INVALID" ;
VAL_ 1010 ic_hudillumiLvSet 0 "-5" 1 "-4" 2 "-3" 3 "-2" 4 "-1" 5 "0" 6 "1" 7 "2" 8 "3" 9 "4" 10 "5" 11 "INVALID" ;
VAL_ 1016 IC_driverSeatBeltStatus 0 "UNTIED" 1 " TIED" ;
VAL_ 1016 IC_driverSeatBeltStatusValid 0 "INVALID" 1 " VALID" ;
VAL_ 1016 IC_passengerSeatBeltStatus 0 "UNTIED" 1 " TIED" ;
VAL_ 1016 IC_passengerSeatBeltStatusValid 0 "INVALID" 1 " VALID" ;
VAL_ 1393 IC_AlarmListflag 0 "No Request" 1 "Request" 2 "Reserved" 3 " INVALID" ;
VAL_ 1393 IC_WarningStatus 0 "No Request" 1 "报警" 2 "取消报警" 3 " 故障列表状态" ;
VAL_ 1393 IC_WarningStatus2 0 "No Request" 1 "报警" 2 "取消报警" 3 " 故障列表状态" ;
VAL_ 1393 IC_WarningStatus3 0 "No Request" 1 "报警" 2 "取消报警" 3 " 故障列表状态" ;
VAL_ 1393 IC_WarningStatus4 0 "No Request" 1 "报警" 2 "取消报警" 3 " 故障列表状态" ;
VAL_ 1393 IC_WarningStatus5 0 "No Request" 1 "报警" 2 "取消报警" 3 " 故障列表状态" ;
VAL_ 1393 IC_WarningStatus6 0 "No Request" 1 "报警" 2 "取消报警" 3 " 故障列表状态" ;
VAL_ 1392 IC_DMS_DistractionIconFB 0 "no request" 1 "显示图标:高风险分神" 2 "显示图标:中风险分神" 3 "显示图标:检测到打电话" 4 "显示图标:分神检测功能关闭" 5 "显示图标:低风险分神" 6 " Reserved" ;
VAL_ 1392 IC_DMS_FatigueIconFB 0 "no request" 1 "显示图标:高风险疲劳" 2 "显示图标:中风险疲劳" 3 "显示图标:连续驾驶超3小时" 4 "显示图标:连续驾驶超4小时" 5 "显示图标:长时间未休息" 6 "显示图标:低风险疲劳" 7 " Reserved" ;
VAL_ 798 bms_state 0 "INIT初始化" 1 "STANDBY准备" 2 "PRECHARGE预充电" 3 "CONTACTORS_CLOSED继电器闭合" 4 "AC_CHARGE交流充电" 5 "DC_CHARGE直流充电" 6 "SHUT_DOWN高压下电" 7 "OFF" 8 "FAULT" 9 "V2L" 10 "V2V" 11 "RTCPolling" 12 "Reserved" 13 "Reserved" 14 "Reserved" 15 "Reserved" ;
VAL_ 798 bms_dcChargeState 0 "OFF" 1 "INIT" 2 "STANDBY" 3 "CHARGING" 4 "CHARGE_END" 5 "Warming" 6 "FAULT" 7 "Float" ;
VAL_ 798 bms_acChargeState 0 "OFF" 1 "INIT" 2 "STANDBY" 3 "CHARGING" 4 "CHARGE_END" 5 "Warming" 6 "FAULT" 7 "Float" ;
VAL_ 798 BMS_HVInterlock_Status 0 "Lock" 1 "Unlock" ;
VAL_ 798 bms_isolationState 0 "UNKNOWN" 1 "NORMAL" 2 "FAULT" 3 " None" ;
VAL_ 798 bms_contactorState 0 "IDLE空闲" 1 "PRECHG_START预充继电器开始闭合" 2 "PRECHG_CLOSE_NEG_MAIN主负闭合" 3 "PRECHG_WAIT_POST_NEG主负闭合中" 4 "PRECHG_CLOSE_PRECHG预充闭合" 5 "PRECHG_FINISH预充继电器闭合完成" 6 "CMC_START主正继电器开始闭合" 7 "CMC_CLOSE_POS_MAIN主正闭合" 8 "CMC_WAIT_POST_NEG主正等待主负闭合" 9 "CMC_OPEN_PRECHG主正打开预充闭合" 10 "CMC_FINISH主正继电器闭合完成" 11 "SD_START下电开始" 12 "SHUTDOWN正在下电" 13 "SD_FINISH下电完成" 14 "FAULT错误" 15 " None" ;
VAL_ 798 bms_acChargeConnection 0 "DISCONNECT" 1 " CONNECT" ;
VAL_ 798 bms_dcChargeConnection 0 "DISCONNECT" 1 " CONNECT" ;
VAL_ 798 bms_authenticationResult 0 "UINITIAL_OR_AUTH_INPROGRESS认证中" 1 "AUTH_FAILED认证失败" 2 "AUTH_SUCCESS认证成功" 3 " No Valid Key" ;
VAL_ 798 bms_alertLevel 0 "Normal" 1 "Level1" 2 "Level2" 3 "Level3" 4 "Level4" 5 "Level5" 6 "Level6" 7 "Reserved" ;
VAL_ 942 mcur0_stEgyFlowAndBatt 0 "NEUTRAL" 1 "Rear_MOTOR_TO_BATTERY" 2 " BATTERY_TO_Rear_MOTOR" ;
VAL_ 942 mcur0_faultLevel 0 "Normal" 1 "Level1" 2 "Level2" 3 "Level3" 4 "Level4" 5 "Level5" 6 "Level6" 7 "Reserved" ;
VAL_ 942 mcur0_Fault_Light_Ctrl 0 "OFF" 1 "ON" ;
VAL_ 958 mcuf0_stEgyFlowAndBatt 0 "NEUTRAL" 1 "FRONT_MOTOR_TO_BATTERY" 2 " BATTERY_TO_FRONT_MOTOR" ;
VAL_ 958 mcuf0_faultLevel 0 "Normal" 1 "Level1" 2 "Level2" 3 "Level3" 4 "Level4" 5 "Level5" 6 "Level6" 7 "Reserved" ;
VAL_ 958 mcuf0_Fault_Light_Ctrl 0 "OFF" 1 "ON" ;
VAL_ 894 ecu_milIndicator 0 "OFF" 1 "INVALID" 2 "ON" 3 " INVALID" ;
VAL_ 894 vcu_coolantLevelLow 0 "NORMAL" 1 " FAULT" ;
VAL_ 894 vcu_brakeLight 0 "OFF" 1 " ON" ;
VAL_ 894 ecu_state 0 "STANDBY" 1 "READY" 2 "CRANKING" 3 "RUNNING" 4 "STOPPING" 5 "FINISH" 6 "AUTOSTOPPING" 7 " None" ;
VAL_ 894 vcu_highVoltFail 0 "NOT_FAIL" 1 "FAIL" 2 "RESERVED" 3 " INVALID" ;
VAL_ 894 vcu_Regenmode 0 "OFF" 1 " ON" ;
VAL_ 894 vcu_accelPosValid 0 "INVALID" 1 " VALID" ;
VAL_ 547 esc_vehicleSpeedValid 0 "INVALID" 1 " VALID" ;
VAL_ 547 esc_avhActive 0 "INACTIVE" 1 " ACTIVE" ;
VAL_ 547 esc_avhStandby 0 "NOT_STANDBY" 1 "STANDBY" ;
VAL_ 547 esc_avhAvailable 0 "NOT_AVAILABLE" 1 " AVAILABLE" ;
VAL_ 547 esc_hdcStatus 0 "OFF" 1 "STANDBY" 2 " ACTIVE" ;
VAL_ 547 esc_vlcTorqReqActive 0 "NOT_ACTIVE" 1 " ACTIVE" ;
VAL_ 547 esc_vlcError 0 "NOT_ERROR" 1 " ERROR" ;
VAL_ 547 esc_vlcAvalible 0 "NOT_AVAILABLE" 1 " AVAILABLE" ;
VAL_ 547 esc_vlcActive 0 "INACTIVE" 1 " ACTIVE" ;
VAL_ 547 eps_modeStatus 0 "reserve" 1 "COMFORT" 2 "SPORT" 3 " INVALID" ;
VAL_ 547 esc_escActive 0 "INACTIVE" 1 " ACTIVE" ;
VAL_ 547 esc_hdcAvailable 0 "NOT_AVAILABLE" 1 " AVAILABLE" ;
VAL_ 547 iB_hmiWarningOn 0 "NO_REQUEST" 1 "YELLOW" 2 "RED" 3 " NOT_AVAILABLE" ;
VAL_ 547 iB_hmiWarningOn_Q 0 "NOT_INITIALIZED" 1 "NORMAL" 2 " FAULTY" ;
VAL_ 547 esc_hhcAvailable 0 "NOT_AVAILABLE" 1 " AVAILABLE" ;
VAL_ 851 eps_torsionBarTorqueValid 0 "INVALID" 1 " VALID" ;
VAL_ 590 vcu_brakePedalSts 0 "NORMAL_OPEN" 1 " NORMAL_CLOSE" ;
VAL_ 590 vcu_brakePedalStsValid 0 "INVALID" 1 " VALID" ;
VAL_ 590 vcu_actualGearValid 0 "INVALID" 1 " VALID" ;
VAL_ 590 vcu_actualGear 0 "P" 1 "R" 2 "N" 3 " D" ;
VAL_ 974 ac_ambientTempValid 0 "INVALID" 1 " VALID" ;
VAL_ 951 pdc_buzzerAlarmPattern 0 "BUZZER_OFF" 1 "FRONT_BUZZER_ON" 2 "FRONT_BUZZER_ON_AT_4HZ" 3 "FRONT_BUZZER_ON_AT_2HZ" 4 "REAR_BUZZER_ON" 5 "REAR_BUZZER_ON_AT_4HZ" 6 "REAR_BUZZER_ON_AT_2HZ" 7 " REAR_BUZZER_ON_AT_1HZ" ;
VAL_ 951 pdc_modeStatus 0 "OFF" 1 "STANDBY" 2 "FRONT_REAR_ACTIVE" 3 "FRONT_ACTIVE" 4 "REAR_ACTIVE" 5 "SYSTEM_FAILURE" 6 "INHIBITED" 7 "FAILURE WARNING" ;
VAL_ 951 pdc_distanceFL 0 "NO_DISTANCE" 1 "RANGE_1" 2 "RANGE_2" 3 "RANGE_3" 4 "RESERVED" 5 "RESERVED" 6 "RESERVED" 7 " RESERVED" ;
VAL_ 951 pdc_sensorFaultFL 0 "NORMAL" 1 " FAULT" ;
VAL_ 951 pdc_distanceFML 0 "NO_DISTANCE" 1 "RANGE_1" 2 "RANGE_2" 3 "RANGE_3" 4 "RESERVED" 5 "RESERVED" 6 "RESERVED" 7 " RESERVED" ;
VAL_ 951 pdc_sensorFaultFML 0 "NORMAL" 1 " FAULT" ;
VAL_ 951 pdc_distanceFMR 0 "NO_DISTANCE" 1 "RANGE_1" 2 "RANGE_2" 3 "RANGE_3" 4 "RESERVED" 5 "RESERVED" 6 "RESERVED" 7 " RESERVED" ;
VAL_ 951 pdc_sensorFaultFMR 0 "NORMAL" 1 " FAULT" ;
VAL_ 951 pdc_distanceFR 0 "NO_DISTANCE" 1 "RANGE_1" 2 "RANGE_2" 3 "RANGE_3" 4 "RESERVED" 5 "RESERVED" 6 "RESERVED" 7 " RESERVED" ;
VAL_ 951 pdc_sensorFaultFR 0 "NORMAL" 1 " FAULT" ;
VAL_ 951 pdc_distanceRL 0 "NO_DISTANCE" 1 "RANGE_1" 2 "RANGE_2" 3 "RESERVED" 4 "RESERVED" 5 "RESERVED" 6 "RESERVED" 7 " RESERVED" ;
VAL_ 951 pdc_sensorFaultRL 0 "NORMAL" 1 " FAULT" ;
VAL_ 951 pdc_distanceRML 0 "NO_DISTANCE" 1 "RANGE_1" 2 "RANGE_2" 3 "RANGE_3" 4 "RANGE_4" 5 "RESERVED" 6 "RESERVED" 7 " RESERVED" ;
VAL_ 951 pdc_sensorFaultRML 0 "NORMAL" 1 " FAULT" ;
VAL_ 951 pdc_distanceRMR 0 "NO_DISTANCE" 1 "RANGE_1" 2 "RANGE_2" 3 "RANGE_3" 4 "RANGE_4" 5 "RESERVED" 6 "RESERVED" 7 " RESERVED" ;
VAL_ 951 pdc_sensorFaultRMR 0 "NORMAL" 1 " FAULT" ;
VAL_ 951 pdc_distanceRR 0 "NO_DISTANCE" 1 "RANGE_1" 2 "RANGE_2" 3 "RANGE_3" 4 "RESERVED" 5 "RESERVED" 6 "RESERVED" 7 " RESERVED" ;
VAL_ 951 pdc_sensorFaultRR 0 "NORMAL" 1 " FAULT" ;
VAL_ 951 pdc_FrontRadarActiveStatus 0 "INACTIVE" 1 "OFF" 2 "ON" 3 " INVALID" ;
VAL_ 951 pdc_distanceFSL 0 "NO_DISTANCE" 1 "RANGE_1" 2 "RANGE_2" 3 "RANGE_3" 4 "RESERVED" 5 "RESERVED" 6 "RESERVED" 7 " RESERVED" ;
VAL_ 951 pdc_sensorFaultFSL 0 "NORMAL" 1 " FAULT" ;
VAL_ 951 pdc_distanceFSR 0 "NO_DISTANCE" 1 "RANGE_1" 2 "RANGE_2" 3 "RANGE_3" 4 "RESERVED" 5 "RESERVED" 6 "RESERVED" 7 " RESERVED" ;
VAL_ 951 pdc_sensorFaultFSR 0 "NORMAL" 1 " FAULT" ;
VAL_ 951 pdc_distanceRSL 0 "NO_DISTANCE" 1 "RANGE_1" 2 "RANGE_2" 3 "RANGE_3" 4 "RESERVED" 5 "RESERVED" 6 "RESERVED" 7 " RESERVED" ;
VAL_ 951 pdc_sensorFaultRSL 0 "NORMAL" 1 " FAULT" ;
VAL_ 951 pdc_distanceRSR 0 "NO_DISTANCE" 1 "RANGE_1" 2 "RANGE_2" 3 "RANGE_3" 4 "RESERVED" 5 "RESERVED" 6 "RESERVED" 7 " RESERVED" ;
VAL_ 951 pdc_sensorFaultRSR 0 "NORMAL" 1 " FAULT" ;
VAL_ 952 pdc_actualdistanceFL_ 0 " NO_DISTANCE " ;
VAL_ 952 pdc_actualdistanceFML_ 0 " NO_DISTANCE " ;
VAL_ 952 pdc_actualdistanceFMR_ 0 " NO_DISTANCE" ;
VAL_ 952 pdc_actualdistanceFR_ 0 " NO_DISTANCE" ;
VAL_ 952 pdc_actualdistanceFSL 0 " NO_DISTANCE" ;
VAL_ 952 pdc_actualdistanceFSR 0 " NO_DISTANCE" ;
VAL_ 953 pdc_actualdistanceRL_ 0 " NO_DISTANCE" ;
VAL_ 953 pdc_actualdistanceRML_ 0 " NO_DISTANCE" ;
VAL_ 953 pdc_actualdistanceRMR_ 0 " NO_DISTANCE" ;
VAL_ 953 pdc_actualdistanceRR_ 0 " NO_DISTANCE" ;
VAL_ 953 pdc_actualdistanceRSL 0 " NO_DISTANCE" ;
VAL_ 953 pdc_actualdistanceRSR 0 " NO_DISTANCE" ;
VAL_ 941 wcm_chargingStatus 0 "NO_CHARGE" 1 "CHARGING" 2 "CHARGE_FINISHED" 3 " FAULT" ;
VAL_ 941 wcm_failureStatus 0 "NORMAL" 1 "LOW_VOLT" 2 "HIGH_VOLT" 3 "HIGH_TEMP" 4 "FOREIGN_MATTER_DETECTED" 0 "(左侧区异物检测" 5 "FOREIGN_MATTER_DETECTED(右侧区异物检测)" ;
VAL_ 941 wcm_workingStatus 0 "INACTIVE" 1 "OFF" 2 "ON" 3 " INVALID" ;
VAL_ 941 wcm_selfCheckToIVI 0 "ON CHECKING" 1 "CHECK COMPLETED" 2 "CHECK FAILED" 3 " INVALID" ;
VAL_ 941 WCM_PhoneReminder 0 "无提醒" 1 " 手机遗忘提醒" ;
VAL_ 941 WCM_LeftChargingStatus 0 "没有充电" 1 "充电中" 2 "充满电" 3 " 充电故障" ;
VAL_ 941 WCM_RightChargingStatus 0 "没有充电" 1 "充电中" 2 "充满电" 3 " 充电故障" ;
VAL_ 1156 AVM_apa_sts 0 "OFF" 1 "AVM ON" 2 "APA ON" 3 "STARTING" 4 "Take Photo" 5 "video" 6 "reserved" 7 " INVALID" ;
VAL_ 1156 AVM_SentryModeFB 0 "Reserved" 1 "OFF" 2 "ON" 3 " INVALID" ;
VAL_ 1156 AVM_sysFailureSts 0 "NORMAL" 1 " FAULT" ;
VAL_ 1156 AVM_singleViewSts 0 "off" 1 "2D Front view" 2 "2D Rear view" 3 "2D Left view" 4 "2D Right view" 5 "3D Top view of the head" 6 "3D Top view of the trail" 7 "3D Left side view" 8 "3D Right side view" 9 "3D Front-Left view" 10 "3D Front-Right view" 11 "3D Rear-Left view" 12 "3D Rear-Right view" 13 "Dynamic front view" 14 "Dynamic rear view" 15 "Side View" 16 "3D rotation view" 17 "front enlarge view" 18 "rear enlarge view" 19 "SentryMode view" 20 "Single Front view" 21 "Single Rear view" 22 "Single Left view" 23 "Single Right view" 24 "3D Front view 3D 前视图" 25 "Planform 俯视图" 26 "2D Left Rear view" 27 " 2D Right Rear view" ;
VAL_ 1156 AVM_apa_FrontCameraFailure 0 "NORMAL" 1 " FAULT" ;
VAL_ 1156 AVM_apa_RearCameraFailure 0 "NORMAL" 1 " FAULT" ;
VAL_ 1156 AVM_apa_LeftCameraFailure 0 "NORMAL" 1 " FAULT" ;
VAL_ 1156 AVM_apa_RightCameraFailure 0 "NORMAL" 1 " FAULT" ;
VAL_ 1156 APA_laeb_SW_Sts 0 "Inhibit" 1 "ON" 2 "OFF" ;
VAL_ 1018 hud_onOffSts 0 "OFF" 1 " ON" ;
VAL_ 169 MFW_PRE_Key 0 "No press" 1 "Press" 2 "INVALID" 3 "RESERVED" ;
VAL_ 169 MFW_NEXT_Key 0 "No press" 1 "Press" 2 "INVALID" 3 "RESERVED" ;
VAL_ 169 MFW_VolumeUp_Key 0 "No press" 1 "Press" 2 "INVALID" 3 "RESERVED" ;
VAL_ 169 MFW_VolumeDown_Key 0 "No press" 1 "Press" 2 "INVALID" 3 "RESERVED" ;
VAL_ 169 MFW_PlayPause_Key 0 "No press" 1 "Press" 2 "INVALID" 3 "RESERVED" ;
VAL_ 169 MFW_Answer_Key 0 "No press" 1 "Press" 2 "INVALID" 3 "RESERVED" ;
VAL_ 169 MFW_HangUp_Key 0 "No press" 1 "Press" 2 "INVALID" 3 "RESERVED" ;
VAL_ 169 MFW_APA_AVM_Key 0 "No press" 1 "Press" 2 "INVALID" 3 "RESERVED" ;
VAL_ 169 MFW_PageUP_Key 0 "No press" 1 "Press" 2 "INVALID" 3 "RESERVED" ;
VAL_ 169 MFW_PageDown_Key 0 "No press" 1 "Press" 2 "INVALID" 3 "RESERVED" ;
VAL_ 169 MFW_Interface_Key 0 "No press" 1 "Press" 2 "INVALID" 3 "RESERVED" ;
VAL_ 169 MFW_VoiceButton_Key 0 "No press" 1 "Press" 2 "INVALID" 3 "RESERVED" ;
VAL_ 169 MFW_CustomButton1_Key 0 "No press" 1 "Short Press" 2 "Long Press" 3 "RESERVED" ;
VAL_ 169 MFW_ExhibitionMode 0 "No_request" 1 "OFF" 2 "ON" 3 " Reserved" ;
VAL_ 169 MFW_TJAICAACTIVEKeySts 0 "No press" 1 "Press" 2 "INVALID" 3 "RESERVED" ;
VAL_ 169 MFW_TJAICAACTIVEKeyStsValid 0 "VALID" 1 " INVALID" ;
VAL_ 169 MFW_IVI_Reset 0 "No press" 1 "Press" 2 "RESERVED" 3 " INVALID" ;
VAL_ 1176 MFW_PRE_KeySt 0 "NO_Request" 1 " Request" ;
VAL_ 1176 MFW_NEXT_KeySt 0 "NO_Request" 1 " Request" ;
VAL_ 1176 MFW_PlayPause_KeySt 0 "NO_Request" 1 " Request" ;
VAL_ 1176 MFW_Answer_KeySt 0 "NO_Request" 1 " Request" ;
VAL_ 1176 MFW_HangUp_KeySt 0 "NO_Request" 1 " Request" ;
VAL_ 1176 MFW_VoiceButton_KeySt 0 "NO_Request" 1 " Request" ;
VAL_ 1176 MFW_CustomButton1_KeySt 0 "NO_Request" 1 " Request" ;
VAL_ 1141 SWHC_SterringWheelHeatSts 0 "INACTIVE" 1 "Level_1" 2 "Level_2" 3 "Level_3" 4 "OFF" 5 "Reserved" 6 "Reserved" 7 "Invalid" ;
VAL_ 1141 SWHC_SterringWheelHeatFaultReaso 0 "Normal" 1 "resistive heater open circuit 加热电阻丝丝开路" 2 "resistive heater short out 加热电阻丝短路/过流" 3 "thermistor open circuit 热敏电阻开路" 4 "thermistor short out 热敏电阻短路" 5 "thermistor overheat 热敏电阻检测温度过高＞45℃" ;
VAL_ 768 ALC_ALCThemeModeSts 0 "INACTIVE" 1 "First_Theme" 2 "Second_Theme" 3 "Third_Theme:单色" 4 "Fourth_Theme:音律随动" 5 "Fifth_Theme车速随动" 6 "Reserved" 15 "Invalid" ;
VAL_ 768 ALC_DOWALCWarnningSetSts 0 "INACTIVE" 1 "OFF" 2 "ON" 3 "INVALID" ;
VAL_ 768 ALC_easyEntryALCWarnningSetSts 0 "INACTIVE" 1 "OFF" 2 "ON" 3 "INVALID" ;
VAL_ 768 ALC_BreathFrequencyfb 0 "INACTIVE" 1 "OFF" 2 "ON" 3 "Reserved" 4 "Reserved" 5 "Reserved" 6 "Reserved" 7 "INVALID" ;
VAL_ 768 ALC_ALCSwithCSts 0 "INACTIVE" 1 "OFF" 2 "ON" 3 "INVALID" ;
VAL_ 768 ALC_NavigationTurnSetSts 0 "INACTIVE" 1 "OFF" 2 "ON" 3 "INVALID" ;
VAL_ 768 ALC_TemperatureSwithSts 0 "INACTIVE" 1 "OFF" 2 "ON" 3 "INVALID" ;
VAL_ 768 ALC_BSDWarnningSetSts 0 "INACTIVE" 1 "OFF" 2 "ON" 3 "INVALID" ;
VAL_ 768 ALC_BlueToothSetSts 0 "INACTIVE" 1 "OFF" 2 "ON" 3 "INVALID" ;
VAL_ 768 ALC_FatigueReminderSetSts 0 "NO Request" 1 "OFF" 2 "ON" 3 "INVALID" ;
VAL_ 768 ALC_vehicleWarnningSetSts 0 "INACTIVE" 1 "OFF" 2 "ON" 3 "INVALID" ;
VAL_ 768 ALC_driveModeALCctrltsetSts 0 "INACTIVE" 1 "OFF" 2 "ON" 3 "INVALID" ;
VAL_ 768 ALC_ALCAImodeSetSts 0 "INACTIVE" 1 "OFF" 2 "ON" 3 "INVALID" ;
VAL_ 768 ALC_ALCAplLuminancefb 0 "NO Request" 1 "1-100%" 127 "Invalid" ;
VAL_ 385 ic_displayFail 0 "NORMAL" 1 " FAULT" ;
VAL_ 385 ic_IllumiLevelSts 0 "INVALID" 1 "LEVEL1" 2 "LEVEL2" 3 "LEVEL3" 4 "LEVEL4" 5 "LEVEL5" 6 "LEVEL6" 7 "LEVEL7" 8 "LEVEL8" 9 "LEVEL9" 10 "LEVEL10" 11 "LEVEL11" 12 "LEVEL12" 13 "LEVEL13" 14 "LEVEL14" 15 "LEVEL15" 16 "LEVEL16" 17 "LEVEL17" 18 "LEVEL18" 19 "LEVEL19" 20 "LEVEL20" 21 "LEVEL21" 22 "LEVEL22" 23 "LEVEL23" 24 "LEVEL24" 25 "LEVEL25" 26 "LEVEL26" 27 "LEVEL27" 28 "LEVEL28" 29 "LEVEL29" 30 "LEVEL30" 31 " LEVEL31" ;
VAL_ 754 ic_RRSeatDetectSts 0 "NOT_DETECTED" 1 " DETECTED" ;
VAL_ 754 ic_RMSeatDetectSts 0 "NOT_DETECTED" 1 " DETECTED" ;
VAL_ 754 ic_lowSocIndication 0 "INACTIVE" 1 " ACTIVE" ;
VAL_ 754 ic_passengerSeatDetectSts 0 "NOT_DETECTED" 1 " DETECTED" ;
VAL_ 754 ic_2ndRowLeftSeatBeltSts 0 "UNTIED" 1 " TIED" ;
VAL_ 754 ic_2ndRowLeftSeatBeltStsValid 0 "INVALID" 1 " VALID" ;
VAL_ 754 ic_2ndRowMiddleSeatBeltSts 0 "UNTIED" 1 " TIED" ;
VAL_ 754 ic_2ndRowMiddleSeatBeltStsValid 0 "INVALID" 1 " VALID" ;
VAL_ 754 ic_2ndRowRightSeatBeltSts 0 "UNTIED" 1 " TIED" ;
VAL_ 754 ic_2ndRowRightSeatBeltStsValid 0 "INVALID" 1 " VALID" ;
VAL_ 754 ic_displayFail 0 "NORMAL" 1 " FAULT" ;
VAL_ 754 ic_qDashACCFail 0 "NO_ERROR" 1 "ERROR" 2 "RESERVED" 3 " RESERVED" ;
VAL_ 754 ic_RLSeatDetectSts 0 "NOT_DETECTED" 1 " DETECTED" ;
VAL_ 754 ic_brakeFluidLevel 0 "NORMAL" 1 " LEVEL_LOW" ;
VAL_ 754 ic_totalMileageValid 0 "INVALID" 1 " VALID" ;
VAL_ 754 ic_vehicleSpeedDispValid 0 "INVALID" 1 " VALID" ;
VAL_ 1015 ic_SpeedLimitSts 0 "INACTIVE" 1 "OFF" 2 "Display" 3 " Display+Voice" ;
VAL_ 1015 ic_SpeedLimitModeSts 0 "Inactive" 1 "Manual" 2 "Intelligent" 3 " INVALID" ;
VAL_ 1015 ic_RearseatbeltVoiceWarningSetFb 0 "INACTIVE" 1 "OFF" 2 "ON" 3 " INVALID" ;
VAL_ 1015 ic_OverspeedSts 0 "NO" 1 "OverSpeed" 2 "Reserved" ;
VAL_ 1015 ic_RemainingMilmodeSts 0 "Inactive" 1 "WLTC" 2 "SUM" 3 "CLTC" 4 " NEDC" ;
VAL_ 1015 ic_IllumiLevelSts 0 "INVALID" 1 "LEVEL1" 2 "LEVEL2" 3 "LEVEL3" 4 "LEVEL4" 5 "LEVEL5" 6 "LEVEL6" 7 "LEVEL7" 8 "LEVEL8" 9 "LEVEL9" 10 "LEVEL10" 11 "LEVEL11" 12 "LEVEL12" 13 "LEVEL13" 14 "LEVEL14" 15 "LEVEL15" 16 "LEVEL16" 17 "LEVEL17" 18 "LEVEL18" 19 "LEVEL19" 20 "LEVEL20" 21 "LEVEL21" 22 "LEVEL22" 23 "LEVEL23" 24 "LEVEL24" 25 "LEVEL25" 26 "LEVEL26" 27 "LEVEL27" 28 "LEVEL28" 29 "LEVEL29" 30 "LEVEL30" 31 " LEVEL31" ;
VAL_ 1154 ic_languageSts 0 "SIMPLIFIED_CHINESE" 1 "ENGLISH" 15 " INVALID" ;
VAL_ 1154 ic_oilPercentFail 0 "NORMAL" 1 "SHORT_GROUND" 2 "OUT_RANGE" 3 " SHORT_POWER_OR_OPEN_CIRCURT" ;
VAL_ 1170 IC_VehMntnMileRmnReq 0 "No request" 1 "Request" 2 "Alarm Request" 3 "reserved" ;
VAL_ 1170 IC_VehMntnTimeRmnReq 0 "No request" 1 "Request" 2 "Alarm Request" 3 "reserved" ;
VAL_ 1170 IC_REMntnRmnReq 0 "No request" 1 "Request" 2 "Alarm Request" 3 "reserved" ;
VAL_ 1170 ic_PowerReset 0 "NORequest" 1 " Reset" ;
VAL_ 1171 IC_VehMntnMileCleaFb 0 "INACTIVE" 1 "fail" 2 "success" 3 "Reverse" ;
VAL_ 1171 IC_OilMntnMileCleaFb 0 "INACTIVE" 1 "fail" 2 "success" 3 "Reverse" ;
VAL_ 1171 IC_OilFilMntnMileCleaFb 0 "INACTIVE" 1 "fail" 2 "success" 3 "Reverse" ;
VAL_ 1171 IC_AirFilMntnMileCleaFb 0 "INACTIVE" 1 "fail" 2 "success" 3 "Reverse" ;
VAL_ 1171 IC_VehIntMntnMileFb 0 "INACTIVE" 1 "fail" 2 "success" 3 "Reverse" ;
VAL_ 1173 IVI_FrameType 0 "INVALID" 1 "IVI_Status" 2 " IVI_ACK" ;
VAL_ 1173 IVI_WorkStatus 0 "INVALID" 1 "IVI正常工作" 2 "IVI异常工作" 3 " IVI启动未完成" ;
VAL_ 1173 IVI_CurrentVideo 0 "INVALID" 1 "大导航全屏" 2 "小导航" 3 "电话_个人收藏" 4 "电话_通话记录" 5 "USB音乐" 6 "蓝牙音乐" 7 "在线音乐" 8 "IPod音乐" 9 "本地电台" 10 "在线电台" 11 " 无LVDS视频" ;
VAL_ 1173 IVI_EventNotify 0 "INVALID" 1 "来电" 2 "去电" 3 "通话中" 4 " 电话挂断" ;
VAL_ 1173 IVI_IC_Sync 0 "No COMMAND" 1 "取消全屏同步" 2 "全屏导航同步" 3 "全屏ADS同步" 4 "全屏APA同步" 15 " INVALID" ;
VAL_ 1173 IVI_Respitemodests 0 "INACTIVE" 1 "OFF" 2 "ON" 3 " INVALID" ;
VAL_ 1173 IVI_ModeSts 0 "INACTIVE" 1 "OFF" 2 "ON" 3 " INVALID" ;
VAL_ 1173 IVI_SentryReq 0 "NO_REQUEST" 1 "OFF" 2 "ON" 3 " INVALID" ;
VAL_ 1173 IVI_SentryAlarmSts 0 "OFF" 1 "Active" 2 "Alert" 3 " Alarm" ;
VAL_ 1173 IVI_ModeReq 0 "NO_REQUEST" 1 "OFF" 2 "ON" 3 " INVALID" ;
VAL_ 1173 IVI_SentryTimeFd 0 "Inactive" 1 "0.5" 2 "1" 3 "1.5" 4 "2" 5 "2.5" 6 "3" 7 "3.5" 8 "4" 9 "4.5" 10 "5" 11 "5.5" 12 "6" 13 "6.5" 14 "7" 15 "7.5" 16 "8" 17 "reserve" 31 "INVALID" ;
VAL_ 1173 IVI_RangeExtenderdisenable 0 "NO_REQUEST" 1 "OFF" 2 "ON" 3 " INVALID" ;
VAL_ 1173 IVI_ChildrenLeftremindSts 0 "NO 不提醒" 1 "YES 提醒" 2 "Reserved" 3 " INVALID" ;
VAL_ 1173 IVI_PetModeSts 0 "OFF" 1 "ON" 2 "reserve" 3 " INVALID" ;
VAL_ 1173 IVI_SentryFaultReason 0 "Normal" 1 "BCMSYSFault" 2 "APASYSFault" 3 "LOWSOC" 4 "CameraFault" 5 "USBUNCONNECTED" 6 "USBNearly FULL" 7 "ModeConflict" 8 "Emergency recording" 9 " Reserved" ;
VAL_ 1173 IVI_WashModeSts 0 "OFF" 1 "Normal" 2 "ConveyerBelt" 3 " INVAILD" ;
VAL_ 1173 IVI_HCUcontrol 0 "No request" 1 "spread（展开）" 2 "retract （缩回）" 3 " reserved" ;
VAL_ 1174 IVI_DMS_DistractionIcon 0 "no request" 1 "显示图标:高风险分神" 2 "显示图标:中风险分神" 3 "显示图标:检测到打电话" 4 "显示图标:分神检测功能关闭" 5 "显示图标:低风险分神" 6 " Reserved" ;
VAL_ 1174 IVI_DMS_FatigueIcon 0 "no request" 1 "显示图标:高风险疲劳" 2 "显示图标:中风险疲劳" 3 "显示图标:连续驾驶超3小时" 4 "显示图标:连续驾驶超4小时" 5 "显示图标:长时间未休息" 6 "显示图标:低风险疲劳" 7 " Reserved" ;
VAL_ 1520 cdc_status 0 "NORMAL" 1 "SOC_STR" 2 "OTA" 3 "FAULT" 15 " INVALID" ;
VAL_ 1520 cdc_mcuStatus 0 "NORMAL" 1 "OTA" 2 "FAULT" 15 " INVALID" ;
VAL_ 1520 cdc_mcuEnvStatus 0 "THERMAL_STATE_NUMB" 1 "THERMAL_STATE_COLD" 2 "THERMAL_STATE_COMFORT" 3 "THERMAL_STATE_LIGHTHOT" 4 "THERMAL_STATE_HOT" 5 "THERMAL_STATE_SEVERE" 6 "THERMAL_STATE_CRITICAL" 7 "THERMAL_STATE_EMERGENCY" 8 "THERMAL_STATE_SHUTDOWN" 15 " INVALID" ;
VAL_ 1520 cdc_mcuBatStatus 0 "BAT_STATE_ULTRA_LOW" 1 "BAT_STATE_LOW" 2 "BAT_STATE_NORMAL" 3 "BAT_STATE_HIGH" 4 "BAT_STATE_ULTRA_HIGH" 15 " INVALID" ;
VAL_ 1520 cdc_mcuFsmStatus 0 "FSM_mcu_off" 1 "FSM_state_init" 2 "FSM_state_str" 3 "FSM_state_down" 4 "FSM_state_goto_shut_mcu" 5 "FSM_state_goto_shut_soc" 6 "FSM_state_goto_enable" 7 "FSM_state_on" 8 "FSM_state_abnormal_rest" 9 "FSM_state_reseting" 10 "FSM_state_mcu_on" 15 " INVALID" ;
VAL_ 1520 cdc_rdcStatus 0 "NORMAL" 1 "Reserved" 15 " INVALID" ;
VAL_ 1520 cdc_socChipStatus 0 "ON" 1 "OFF" 2 "STR" 3 "FASTBOOT" 4 "FAULT" 15 " INVALID" ;
VAL_ 1520 cdc_icPowerStatus 0 "ACTIVE" 1 "STANDBY" 2 "STR" 3 "SHUTDOWN" 4 "OTA" 5 "FAULT" 15 " INVALID" ;
VAL_ 1520 cdc_iviPowerStatus 0 "ACTIVE" 1 "STANDBY" 2 "STR" 3 "SHUTDOWN" 4 "OTA" 5 "FAULT" 15 " INVALID" ;
VAL_ 1520 cdc_silsStatus 0 "ACTIVE" 1 "STANDBY" 2 "STR" 3 "SHUTDOWN" 4 "OTA" 5 "FAULT" 15 " INVALID" ;
VAL_ 1520 cdc_icLcdStatus 0 "ON" 1 "OFF" 2 "OTA" 3 "FAULT" 15 " INVALID" ;
VAL_ 1520 cdc_iviLcdStatus 0 "ON" 1 "OFF" 2 "OTA" 3 "FAULT" 15 " INVALID" ;
VAL_ 1186 IC_FrameType 0 "INVALID" 1 "IC Status" 2 "IC REQ" 3 " IC ACK" ;
VAL_ 1186 IC_WorkStatus 0 "INVALID" 1 "IC工作正常" 2 "IC工作异常" 3 " IC处于保护模式" ;
VAL_ 1186 IC_RequestVideo 0 "INVALID" 1 "大导航全屏" 2 "小导航（上切）" 3 "电话_个人收藏" 4 "电话_通话记录" 5 "USB音乐" 6 "蓝牙音乐" 7 "在线音乐" 8 "IPod音乐" 9 "本地电台" 10 "在线电台" 11 "二指同步" 12 "取消小导航(上切)" 13 "小导航（下切)" 14 "取消小导航（下切）" ;
VAL_ 1186 IC_currentDisplayVideo 0 "INVALID" 1 "大导航全屏" 2 "小导航" 3 "电话_个人收藏" 4 "电话_通话记录" 5 "USB音乐" 6 "蓝牙音乐" 7 "在线音乐" 8 "IPod音乐" 9 "本地电台" 10 "在线电台" 11 "无需LVDS视频输出的画面" 12 "全屏大导航+诱导" 13 "无导航" 14 "ADS全屏显示" 15 "APA全屏显示" ;
VAL_ 1186 IC_keyOperation 0 "INVALID" 1 "上短按" 2 "下短按" 3 "左短按" 4 "右短按" 5 "确定短按" 6 "确定长按" 7 " 返回短按" ;
VAL_ 1186 IC_RightVideoStatus 0 "no popup" 1 " popup" ;
VAL_ 1186 IC_DisFail 0 "No Error" 1 " Error" ;
VAL_ 949 ivi_hvacDefrostMode 0 "INVALID" 1 " KEY_PRESS" ;
VAL_ 949 ivi_hvacOnOffReq 0 "INVALID" 1 " KEY_PRESS" ;
VAL_ 949 IVI_ExhibitionScene 0 "Normal" 1 "ExhibitionInDoor（内展）" 2 " ExhibitionOutDoor（外展）" ;
VAL_ 949 ivi_hvacAutoModeReq 0 "INVALID" 1 " KEY_PRESS" ;
VAL_ 949 ivi_hvacRecircModeReq 0 "INVALID" 1 " KEY_PRESS" ;
VAL_ 949 ivi_hvacModeReq 0 "FACE" 1 "FACE_AND_FOOT" 2 "FOOT" 3 "FOOT_AND_DEFROST" 4 "DEFROST" 5 "reserve" 7 " INVALID" ;
VAL_ 949 ivi_hvacBlowLvReq 0 "OFF" 1 "LEVEL_1" 2 "LEVEL_2" 3 "LEVEL_3" 4 "LEVEL_4" 5 "LEVEL_5" 6 "LEVEL_6" 7 " LEVEL_7" ;
VAL_ 949 ivi_hvacDualMode 0 "INVALID" 1 " KEY_PRESS" ;
VAL_ 949 ivi_acReq 0 "INVALID" 1 " KEY_PRESS" ;
VAL_ 949 IVI_NavigatioRecircReq 0 "NORequest" 1 "OFF" 2 "ON" 3 " INVALID" ;
VAL_ 949 IVI_NaviTunnelstatus 0 "OUT" 1 " Enter" ;
VAL_ 949 IVI_ScreenOutReq 0 "NO_REQUEST" 1 "OFF" 2 "ON" 3 " INVALID" ;
VAL_ 949 USB_Sts 0 "Normal" 1 "FULL" 2 "nearly FULL" 3 " Fault" ;
VAL_ 949 ivi_svcSteerInteractionSetReserv 0 "OFF" 1 " ON" ;
VAL_ 949 ivi_InterfaceSwitchReq 0 "No_request" 1 "APA ON" 2 "AVM ON" 3 " OFF" ;
VAL_ 949 ivi_languageSet 0 "SIMPLIFIED_CHINESE" 1 "ENGLISH" 2 "RESERVED" 3 " NO_COMMAND" ;
VAL_ 949 ivi_unitSet 0 "KM" 1 "MILE" 2 "NORequest" 3 " INVALID" ;
VAL_ 949 IVI_IntPuficationSw 0 "NORequest" 1 "OFF" 2 "ON" 3 " Invalid" ;
VAL_ 949 IVI_NaturalwindSw 0 "NORequest" 1 "OFF" 2 "ON" 3 " Invalid" ;
VAL_ 949 IVI_VideoResult 0 "OFF" 1 "take Video in operation" 2 "talke Video success" 3 " take Video failed" ;
VAL_ 949 IVI_AutoRainWiperReq 0 "no request" 1 "ON" 2 "OFF" 3 " reserved" ;
VAL_ 949 IVI_TakePhotoReq 0 "NO_REQUEST" 1 "Front" 2 "Rear" 3 "Left" 4 "Right" 5 "3D Front view" 6 "Planform" 7 "OFF" ;
VAL_ 1269 IVI_TimeFormatset 0 "24" 1 " 12" ;
VAL_ 1269 IVI_timeValid 0 "INVALID" 1 " VALID" ;
VAL_ 1157 ivi_crossNaviDistance 0 "0x0: UNCONNECTED给HUD；" ;
VAL_ 1157 ivi_naviDirection 0 "导航未开启" 1 "东" 2 "南" 3 "西" 4 "北" 5 "东南" 6 "东北" 7 "西南" 8 "西北" 9 "Reserved" 15 " INVALID" ;
VAL_ 917 ivi_radioStatus 0 "UNCONNECTED" 1 "FM" 2 "AM" 3 "FREQUENCY SCAN" 4 "AUTO SEARCH" 5 "TRACK SCAN" 6 "TRACK RANDOM" 7 " TRACK REPEAT" ;
VAL_ 917 ivi_blueToothStatus 0 "UNCONNECTED" 1 "CONNECTED" 2 "RESERVED" 3 "MUSIC" 4 "BT CALLING" 5 "BT Dial in" 6 "BT Dial out" 7 " Reserved" ;
VAL_ 917 ivi_usbStatus 0 "UNCONNECTED" 1 "CONNECTED" 2 " PLAY" ;
VAL_ 917 ivi_iPodStatus 0 "UNCONNECTED" 1 "CONNECTED" 2 " PLAY" ;
VAL_ 917 ivi_lvdsStatus 0 "INVALID" 1 "退出小导航" 2 "显示小导航" 3 " LVDS显示故障" ;
VAL_ 917 ivi_DMS_Sysfault 0 "OFF" 1 "ON" 2 "预留" 3 " INVALID" ;
VAL_ 917 ivi_sdStatus 0 "UNCONNECTED" 1 "CONNECTED" 2 " PLAY" ;
VAL_ 917 ivi_auxStatus_Reserved 0 "UNCONNECTED" 1 "CONNECTED" 2 " PLAY" ;
VAL_ 917 ivi_tvStatus 0 "UNCONNECTED" 1 "CONNECTED" 2 " PLAY" ;
VAL_ 917 ivi_discStatus 0 "UNCONNECTED" 1 "CONNECTED" 2 " PLAY" ;
VAL_ 917 ivi_dvbtStatus 0 "UNCONNECTED" 1 "CONNECTED" 2 " PLAY" ;
VAL_ 917 ivi_naviStatus 0 "UNCONNECTED" 1 "CONNECTED" 2 " ACTIVE开始导航" ;
VAL_ 917 ivi_lvdsReadyStatus 0 "0x0 未就绪" 1 "小图标导航" 2 "全屏导航" 3 "电话" 4 "多媒体" 5 "收音机" 6 "LVDS信号显示屏蔽被其他界面打断" 7 "预留" 8 "预留" 9 "预留" 10 "预留" 11 "预留" 12 "预留" 13 "预留" 14 "预留" 15 " 预留" ;
VAL_ 965 ivi_naviTextStrLength 0 "NO INFO导航未开启或退出" 1 "文本长度1" 2 "文本长度2" 3 "文本长度3" 4 "文本长度4" 5 "文本长度5" 6 "文本长度6" 7 "文本长度7" 8 "文本长度8" 9 "文本长度9" 10 "文本长度10" 11 "文本长度11" 12 "文本长度12" 13 "文本长度13" 14 "文本长度14" 15 "文本长度15" 16 "文本长度16" 17 "文本长度17" 18 "文本长度18" 19 "文本长度19" 20 "文本长度20" 21 "文本长度21" 22 "文本长度22" 23 "文本长度23" 24 "文本长度24" 25 "文本长度25" 26 "文本长度26" 27 "文本长度27" 28 "文本长度28" 29 "文本长度29" 30 "道路信息保持" 31 " 至0x3FReserved" ;
VAL_ 965 ivi_naviTextCountNum 0 "Default" 1 "数据包编号1" 2 "数据包编号2" 3 "数据包编号3" 4 "数据包编号4" 5 "数据包编号5" 6 "数据包编号6" 7 "数据包编号7" 8 "数据包编号8" 9 "数据包编号9" 10 "数据包编号10" 11 "Reserved" 12 "Reserved" 13 "Reserved" 14 "Reserved" 15 " Reserved" ;
VAL_ 975 ECALL_EcallState 0 "idle初始状态" 1 "diagling拨打中" 2 "connected通话中" 3 "hung up挂断" 4 "Reserved" 7 "Invalid" ;
VAL_ 81 ECALL_EcallReq 0 "No Request" 1 "Request" 2 "Reserved" 3 "Invalid" ;
VAL_ 81 ECALL_MUTE 0 "No Request" 1 "NO MUTE" 2 "MUTE" 3 "Invalid" ;
VAL_ 933 ivi_telSongTextStrLength 0 "ON INFO" 1 "文本长度1" 2 "文本长度2" 3 "文本长度3" 4 "文本长度4" 5 "文本长度5" 6 "文本长度6" 45 "文本长度45" 46 "信息保持" 47 "至0x3FReserved" ;
VAL_ 933 ivi_telSongTextCountNum 0 "Default" 1 "数据包编号1" 2 "数据包编号2" 3 "数据包编号3" 4 "数据包编号4" 5 "数据包编号5" 6 "数据包编号6" 7 "数据包编号7" 8 "数据包编号8" 9 "数据包编号9" 10 "数据包编号10" 11 "数据包编号11" 12 "数据包编号12" 13 "数据包编号13" 14 "数据包编号14" 15 " 数据包编号15" ;
VAL_ 933 ivi_telSongTextType 0 "NULL" 1 "歌曲相关信息" 2 "蓝牙通话人姓名文本" 3 " 蓝牙电话号码文本" ;
VAL_ 933 ivi_telSongTextEncodingType 0 "NULL" 1 "ASCII" 2 "AUTF-8" 3 "NICODE小端模式" 4 "UNICODE大端模式" 5 " GBK" ;
VAL_ 485 IVI_BlueToothStatus 0 "unconnected" 1 "connected" 2 "通话结束" 3 "music" 4 "talking(通话中)" 5 "call in(来电中)" 6 "call out(去电中)" 7 "预留" ;
VAL_ 485 IVI_AISpeaking 0 "NO_REQUEST" 1 "FL" 2 "FR" 3 "RL" 4 "RR" 7 "INVALID" ;
VAL_ 485 IVI_AIListening 0 "NO_REQUEST" 1 "FL" 2 "FR" 3 "RL" 4 "RR" 5 "预留" 7 "INVALID" ;
VAL_ 485 IVI_AIawaken 0 "NO_REQUEST" 1 "FL" 2 "FR" 3 "RL" 4 "RR" 7 "INVALID" ;
VAL_ 485 IVI_AIUnderstand 0 "NO_REQUEST" 1 "FL" 2 "FR" 3 "RL" 4 "RR" 7 "INVALID" ;
VAL_ 485 IVI_AIRecognition 0 "NO_REQUEST" 1 "FL" 2 "FR" 3 "RL" 4 "RR" 7 "INVALID" ;
VAL_ 485 IVI_A_Vehiclealarm 0 "NOWarnningmess" 1 " WarnningFlag" ;
VAL_ 1570 NM_IVI_RepeatMessageRequestBit 0 "该报文发送节点未请求其他节点进入重复报文状态" 1 "该报文发送节点请求其他节点进入重复报文状态" ;
VAL_ 1570 NM_IVI_ActiveWakeup_Bit 0 "该报文发送节点未主动唤醒网络被其它节点唤醒" 1 "该报文发送节点主动唤醒网络" ;
VAL_ 1570 NM_IVI_RepeatSts 0 "节点不在重复报文状态" 1 "节点处于重复报文状态" ;
VAL_ 1570 NMIVI_Active_Source 0 "电源ON档" 1 "直接网络管理报文" 2 "预留" 3 "预留" 4 "预留" 5 "预留" 6 "预留" 7 "预留" 8 "预留" 9 "预留" 10 "预留" 11 "预留" ;
VAL_ 862 CCU_CompressorState 0 "Init" 1 "Standby" 2 "HV_Standby" 3 "Running" 4 "Fault" 5 "Reserve" 6 "Reserve" 7 "Reserve" ;
VAL_ 862 vcu_PTC_Request 0 "PTC off" 1 "PTC on" 2 "Reserved" 3 " Signal not available" ;
VAL_ 862 bms_v2vChrgConnection 0 "Disconnect" 1 " Connected" ;
